VERSION ""

NS_ :

BS_:

BU_: DTCO ICL COO11 SRR6TRightMaster_R_Master SRR6TLeftMaster_L_Master

BO_ 2399091085 SRRL_Objects_09_SRR2: 64 SRR6TLeftMaster_L_Master
 SG_ SRRL_Object_E2E_CRC_09 : 0|16@1+ (1,0) [0|65535] "-"  COO11
 SG_ SRRL_Object_E2E_Counter_09 : 16|8@1+ (1,0) [0|255] "-"  COO11
 SG_ BatchId_SRRObj_L_09 : 24|3@1+ (1,0) [0|5] "-"  COO11
 SG_ LonPosition_L_17 : 28|13@1+ (0.0625,-254.9375) [-254.9375|254.9375] "m"  COO11
 SG_ LonPositionStd_L_17 : 41|10@1+ (0.025,0.025) [0.025|20] "m"  COO11
 SG_ LatPosition_L_17 : 51|13@1+ (0.0625,-254.9375) [-254.9375|254.9375] "m"  COO11
 SG_ LatPositionStd_L_17 : 64|10@1+ (0.025,0.025) [0.025|20] "m"  COO11
 SG_ LonGndVel_L_17 : 74|13@1+ (0.0625,-170) [-170|170] "m/s"  COO11
 SG_ LonGndVelStd_L_17 : 87|10@1+ (0.025,0.025) [0.025|14] "m/s"  COO11
 SG_ LatGndVel_L_17 : 97|13@1+ (0.0625,-170) [-170|170] "m/s"  COO11
 SG_ LatGndVelStd_L_17 : 110|10@1+ (0.025,0.025) [0.025|14] "m/s"  COO11
 SG_ ExistenceProbability_L_17 : 120|8@1+ (0.4,0) [0|100] "%"  COO11
 SG_ Width_L_17 : 128|8@1+ (0.1,0) [0|4] "m"  COO11
 SG_ Length_L_17 : 136|10@1+ (0.1,0) [0|60] "m"  COO11
 SG_ HeadingAngle_L_17 : 146|8@1+ (0.02618,-3.1416) [-3.1416|3.1416] "rad"  COO11
 SG_ DynamicProperty_L_17 : 154|3@1+ (1,0) [0|5] "-"  COO11
 SG_ ClassMostProb_L_17 : 157|3@1+ (1,0) [0|5] "-"  COO11
 SG_ ClassMostProbConf_L_17 : 160|8@1+ (0.4,0) [0|100] "%"  COO11
 SG_ ClassSecMostProb_L_17 : 168|3@1+ (1,0) [0|5] "-"  COO11
 SG_ ClassSecMostProbConf_L_17 : 171|8@1+ (0.4,0) [0|100] "%"  COO11
 SG_ MaintenanceState_L_17 : 179|3@1+ (1,0) [0|3] "-"  COO11
 SG_ YawRate_L_17 : 182|16@1+ (0.0001220703125,-3) [-3|3] "rad/s"  COO11
 SG_ Occlusion_L_17 : 198|3@1+ (1,0) [0|3] "-"  COO11
 SG_ TrackingId_L_17 : 201|8@1+ (1,0) [0|250] "-"  COO11
 SG_ ReferencePoint_L_17 : 209|4@1+ (1,0) [0|8] "-"  COO11
 SG_ RadarCrossSection_L_17 : 213|11@1+ (0.1,-100) [-100|100] "dBm²"  COO11
 SG_ AgeSinceCreated_L_17 : 224|10@1+ (0.01,0) [0|10] "s"  COO11
 SG_ LonPosition_L_18 : 268|13@1+ (0.0625,-254.9375) [-254.9375|254.9375] "m"  COO11
 SG_ LonPositionStd_L_18 : 281|10@1+ (0.025,0.025) [0.025|20] "m"  COO11
 SG_ LatPosition_L_18 : 291|13@1+ (0.0625,-254.9375) [-254.9375|254.9375] "m"  COO11
 SG_ LatPositionStd_L_18 : 304|10@1+ (0.025,0.025) [0.025|20] "m"  COO11
 SG_ LonGndVel_L_18 : 314|13@1+ (0.0625,-170) [-170|170] "m/s"  COO11
 SG_ LonGndVelStd_L_18 : 327|10@1+ (0.025,0.025) [0.025|14] "m/s"  COO11
 SG_ LatGndVel_L_18 : 337|13@1+ (0.0625,-170) [-170|170] "m/s"  COO11
 SG_ LatGndVelStd_L_18 : 350|10@1+ (0.025,0.025) [0.025|14] "m/s"  COO11
 SG_ ExistenceProbability_L_18 : 360|8@1+ (0.4,0) [0|100] "%"  COO11
 SG_ Width_L_18 : 368|8@1+ (0.1,0) [0|4] "m"  COO11
 SG_ Length_L_18 : 376|10@1+ (0.1,0) [0|60] "m"  COO11
 SG_ HeadingAngle_L_18 : 386|8@1+ (0.02618,-3.1416) [-3.1416|3.1416] "rad"  COO11
 SG_ DynamicProperty_L_18 : 394|3@1+ (1,0) [0|5] "-"  COO11
 SG_ ClassMostProb_L_18 : 397|3@1+ (1,0) [0|5] "-"  COO11
 SG_ ClassMostProbConf_L_18 : 400|8@1+ (0.4,0) [0|100] "%"  COO11
 SG_ ClassSecMostProb_L_18 : 408|3@1+ (1,0) [0|5] "-"  COO11
 SG_ ClassSecMostProbConf_L_18 : 411|8@1+ (0.4,0) [0|100] "%"  COO11
 SG_ MaintenanceState_L_18 : 419|3@1+ (1,0) [0|3] "-"  COO11
 SG_ YawRate_L_18 : 422|16@1+ (0.0001220703125,-3) [-3|3] "rad/s"  COO11
 SG_ Occlusion_L_18 : 438|3@1+ (1,0) [0|3] "-"  COO11
 SG_ TrackingId_L_18 : 441|8@1+ (1,0) [0|250] "-"  COO11
 SG_ ReferencePoint_L_18 : 449|4@1+ (1,0) [0|8] "-"  COO11
 SG_ RadarCrossSection_L_18 : 453|11@1+ (0.1,-100) [-100|100] "dbm²"  COO11
 SG_ AgeSinceCreated_L_18 : 464|10@1+ (0.01,0) [0|10] "s"  COO11

BO_ 2399091341 SRRL_Objects_10_SRR2: 64 SRR6TLeftMaster_L_Master
 SG_ SRRL_Object_E2E_CRC_10 : 0|16@1+ (1,0) [0|65535] "-"  COO11
 SG_ SRRL_Object_E2E_Counter_10 : 16|8@1+ (1,0) [0|255] "-"  COO11
 SG_ BatchId_SRRObj_L_10 : 24|3@1+ (1,0) [0|5] "-"  COO11
 SG_ LonPosition_L_19 : 28|13@1+ (0.0625,-254.9375) [-254.9375|254.9375] "m"  COO11
 SG_ LonPositionStd_L_19 : 41|10@1+ (0.025,0.025) [0.025|20] "m"  COO11
 SG_ LatPosition_L_19 : 51|13@1+ (0.0625,-254.9375) [-254.9375|254.9375] "m"  COO11
 SG_ LatPositionStd_L_19 : 64|10@1+ (0.025,0.025) [0.025|20] "m"  COO11
 SG_ LonGndVel_L_19 : 74|13@1+ (0.0625,-170) [-170|170] "m/s"  COO11
 SG_ LonGndVelStd_L_19 : 87|10@1+ (0.025,0.025) [0.025|14] "m/s"  COO11
 SG_ LatGndVel_L_19 : 97|13@1+ (0.0625,-170) [-170|170] "m/s"  COO11
 SG_ LatGndVelStd_L_19 : 110|10@1+ (0.025,0.025) [0.025|14] "m/s"  COO11
 SG_ ExistenceProbability_L_19 : 120|8@1+ (0.4,0) [0|100] "%"  COO11
 SG_ Width_L_19 : 128|8@1+ (0.1,0) [0|4] "m"  COO11
 SG_ Length_L_19 : 136|10@1+ (0.1,0) [0|60] "m"  COO11
 SG_ HeadingAngle_L_19 : 146|8@1+ (0.02618,-3.1416) [-3.1416|3.1416] "rad"  COO11
 SG_ DynamicProperty_L_19 : 154|3@1+ (1,0) [0|5] "-"  COO11
 SG_ ClassMostProb_L_19 : 157|3@1+ (1,0) [0|5] "-"  COO11
 SG_ ClassMostProbConf_L_19 : 160|8@1+ (0.4,0) [0|100] "%"  COO11
 SG_ ClassSecMostProb_L_19 : 168|3@1+ (1,0) [0|5] "-"  COO11
 SG_ ClassSecMostProbConf_L_19 : 171|8@1+ (0.4,0) [0|100] "%"  COO11
 SG_ MaintenanceState_L_19 : 179|3@1+ (1,0) [0|3] "-"  COO11
 SG_ YawRate_L_19 : 182|16@1+ (0.0001220703125,-3) [-3|3] "rad/s"  COO11
 SG_ Occlusion_L_19 : 198|3@1+ (1,0) [0|3] "-"  COO11
 SG_ TrackingId_L_19 : 201|8@1+ (1,0) [0|250] "-"  COO11
 SG_ ReferencePoint_L_19 : 209|4@1+ (1,0) [0|8] "-"  COO11
 SG_ RadarCrossSection_L_19 : 213|11@1+ (0.1,-100) [-100|100] "dBm²"  COO11
 SG_ AgeSinceCreated_L_19 : 224|10@1+ (0.01,0) [0|10] "s"  COO11
 SG_ LonPosition_L_20 : 268|13@1+ (0.0625,-254.9375) [-254.9375|254.9375] "m"  COO11
 SG_ LonPositionStd_L_20 : 281|10@1+ (0.025,0.025) [0.025|20] "m"  COO11
 SG_ LatPosition_L_20 : 291|13@1+ (0.0625,-254.9375) [-254.9375|254.9375] "m"  COO11
 SG_ LatPositionStd_L_20 : 304|10@1+ (0.025,0.025) [0.025|20] "m"  COO11
 SG_ LonGndVel_L_20 : 314|13@1+ (0.0625,-170) [-170|170] "m/s"  COO11
 SG_ LonGndVelStd_L_20 : 327|10@1+ (0.025,0.025) [0.025|14] "m/s"  COO11
 SG_ LatGndVel_L_20 : 337|13@1+ (0.0625,-170) [-170|170] "m/s"  COO11
 SG_ LatGndVelStd_L_20 : 350|10@1+ (0.025,0.025) [0.025|14] "m/s"  COO11
 SG_ ExistenceProbability_L_20 : 360|8@1+ (0.4,0) [0|100] "%"  COO11
 SG_ Width_L_20 : 368|8@1+ (0.1,0) [0|4] "m"  COO11
 SG_ Length_L_20 : 376|10@1+ (0.1,0) [0|60] "m"  COO11
 SG_ HeadingAngle_L_20 : 386|8@1+ (0.02618,-3.1416) [-3.1416|3.1416] "rad"  COO11
 SG_ DynamicProperty_L_20 : 394|3@1+ (1,0) [0|5] "-"  COO11
 SG_ ClassMostProb_L_20 : 397|3@1+ (1,0) [0|5] "-"  COO11
 SG_ ClassMostProbConf_L_20 : 400|8@1+ (0.4,0) [0|100] "%"  COO11
 SG_ ClassSecMostProb_L_20 : 408|3@1+ (1,0) [0|5] "-"  COO11
 SG_ ClassSecMostProbConf_L_20 : 411|8@1+ (0.4,0) [0|100] "%"  COO11
 SG_ MaintenanceState_L_20 : 419|3@1+ (1,0) [0|3] "-"  COO11
 SG_ YawRate_L_20 : 422|16@1+ (0.0001220703125,-3) [-3|3] "rad/s"  COO11
 SG_ Occlusion_L_20 : 438|3@1+ (1,0) [0|3] "-"  COO11
 SG_ TrackingId_L_20 : 441|8@1+ (1,0) [0|250] "-"  COO11
 SG_ ReferencePoint_L_20 : 449|4@1+ (1,0) [0|8] "-"  COO11
 SG_ RadarCrossSection_L_20 : 453|11@1+ (0.1,-100) [-100|100] "dbm²"  COO11
 SG_ AgeSinceCreated_L_20 : 464|10@1+ (0.01,0) [0|10] "s"  COO11

BO_ 2399089039 SRRR_Objects_01_SRR2: 64 SRR6TRightMaster_R_Master
 SG_ SRRR_Object_E2E_CRC_01 : 0|16@1+ (1,0) [0|65535] "-"  COO11
 SG_ SRRR_Object_E2E_Counter_01 : 16|8@1+ (1,0) [0|255] "-"  COO11
 SG_ BatchId_SRRObj_R_01 : 24|3@1+ (1,0) [0|5] "-"  COO11
 SG_ LonPosition_R_01 : 28|13@1+ (0.0625,-254.9375) [-254.9375|254.9375] "m"  COO11
 SG_ LonPositionStd_R_01 : 41|10@1+ (0.025,0.025) [0.025|20] "m"  COO11
 SG_ LatPosition_R_01 : 51|13@1+ (0.0625,-254.9375) [-254.9375|254.9375] "m"  COO11
 SG_ LatPositionStd_R_01 : 64|10@1+ (0.025,0.025) [0.025|20] "m"  COO11
 SG_ LonGndVel_R_01 : 74|13@1+ (0.0625,-170) [-170|170] "m/s"  COO11
 SG_ LonGndVelStd_R_01 : 87|10@1+ (0.025,0.025) [0.025|14] "m/s"  COO11
 SG_ LatGndVel_R_01 : 97|13@1+ (0.0625,-170) [-170|170] "m/s"  COO11
 SG_ LatGndVelStd_R_01 : 110|10@1+ (0.025,0.025) [0.025|14] "m/s"  COO11
 SG_ ExistenceProbability_R_01 : 120|8@1+ (0.4,0) [0|100] "%"  COO11
 SG_ Width_R_01 : 128|8@1+ (0.1,0) [0|4] "m"  COO11
 SG_ Length_R_01 : 136|10@1+ (0.1,0) [0|60] "m"  COO11
 SG_ HeadingAngle_R_01 : 146|8@1+ (0.02618,-3.1416) [-3.1416|3.1416] "rad"  COO11
 SG_ DynamicProperty_R_01 : 154|3@1+ (1,0) [0|5] "-"  COO11
 SG_ ClassMostProb_R_01 : 157|3@1+ (1,0) [0|5] "-"  COO11
 SG_ ClassMostProbConf_R_01 : 160|8@1+ (0.4,0) [0|100] "%"  COO11
 SG_ ClassSecMostProb_R_01 : 168|3@1+ (1,0) [0|5] "-"  COO11
 SG_ ClassSecMostProbConf_R_01 : 171|8@1+ (0.4,0) [0|100] "%"  COO11
 SG_ MaintenanceState_R_01 : 179|3@1+ (1,0) [0|3] "-"  COO11
 SG_ YawRate_R_01 : 182|16@1+ (0.0001220703125,-3) [-3|3] "rad/s"  COO11
 SG_ Occlusion_R_01 : 198|3@1+ (1,0) [0|3] "-"  COO11
 SG_ TrackingId_R_01 : 201|8@1+ (1,0) [0|250] "-"  COO11
 SG_ ReferencePoint_R_01 : 209|4@1+ (1,0) [0|8] "-"  COO11
 SG_ RadarCrossSection_R_01 : 213|11@1+ (0.1,-100) [-100|100] "dBm²"  COO11
 SG_ AgeSinceCreated_R_01 : 224|10@1+ (0.01,0) [0|10] "s"  COO11
 SG_ LonPosition_R_02 : 268|13@1+ (0.0625,-254.9375) [-254.9375|254.9375] "m"  COO11
 SG_ LonPositionStd_R_02 : 281|10@1+ (0.025,0.025) [0.025|20] "m"  COO11
 SG_ LatPosition_R_02 : 291|13@1+ (0.0625,-254.9375) [-254.9375|254.9375] "m"  COO11
 SG_ LatPositionStd_R_02 : 304|10@1+ (0.025,0.025) [0.025|20] "m"  COO11
 SG_ LonGndVel_R_02 : 314|13@1+ (0.0625,-170) [-170|170] "m/s"  COO11
 SG_ LonGndVelStd_R_02 : 327|10@1+ (0.025,0.025) [0.025|14] "m/s"  COO11
 SG_ LatGndVel_R_02 : 337|13@1+ (0.0625,-170) [-170|170] "m/s"  COO11
 SG_ LatGndVelStd_R_02 : 350|10@1+ (0.025,0.025) [0.025|14] "m/s"  COO11
 SG_ ExistenceProbability_R_02 : 360|8@1+ (0.4,0) [0|100] "%"  COO11
 SG_ Width_R_02 : 368|8@1+ (0.1,0) [0|4] "m"  COO11
 SG_ Length_R_02 : 376|10@1+ (0.1,0) [0|60] "m"  COO11
 SG_ HeadingAngle_R_02 : 386|8@1+ (0.02618,-3.1416) [-3.1416|3.1416] "rad"  COO11
 SG_ DynamicProperty_R_02 : 394|3@1+ (1,0) [0|5] "-"  COO11
 SG_ ClassMostProb_R_02 : 397|3@1+ (1,0) [0|5] "-"  COO11
 SG_ ClassMostProbConf_R_02 : 400|8@1+ (0.4,0) [0|100] "%"  COO11
 SG_ ClassSecMostProb_R_02 : 408|3@1+ (1,0) [0|5] "-"  COO11
 SG_ ClassSecMostProbConf_R_02 : 411|8@1+ (0.4,0) [0|100] "%"  COO11
 SG_ MaintenanceState_R_02 : 419|3@1+ (1,0) [0|3] "-"  COO11
 SG_ YawRate_R_02 : 422|16@1+ (0.0001220703125,-3) [-3|3] "rad/s"  COO11
 SG_ Occlusion_R_02 : 438|3@1+ (1,0) [0|3] "-"  COO11
 SG_ TrackingId_R_02 : 441|8@1+ (1,0) [0|250] "-"  COO11
 SG_ ReferencePoint_R_02 : 449|4@1+ (1,0) [0|8] "-"  COO11
 SG_ RadarCrossSection_R_02 : 453|11@1+ (0.1,-100) [-100|100] "dbm²"  COO11
 SG_ AgeSinceCreated_R_02 : 464|10@1+ (0.01,0) [0|10] "s"  COO11

BO_ 2399089295 SRRR_Objects_02_SRR2: 64 SRR6TRightMaster_R_Master
 SG_ SRRR_Object_E2E_CRC_02 : 0|16@1+ (1,0) [0|65535] "-"  COO11
 SG_ SRRR_Object_E2E_Counter_02 : 16|8@1+ (1,0) [0|255] "-"  COO11
 SG_ BatchId_SRRObj_R_02 : 24|3@1+ (1,0) [0|5] "-"  COO11
 SG_ LonPosition_R_03 : 28|13@1+ (0.0625,-254.9375) [-254.9375|254.9375] "m"  COO11
 SG_ LonPositionStd_R_03 : 41|10@1+ (0.025,0.025) [0.025|20] "m"  COO11
 SG_ LatPosition_R_03 : 51|13@1+ (0.0625,-254.9375) [-254.9375|254.9375] "m"  COO11
 SG_ LatPositionStd_R_03 : 64|10@1+ (0.025,0.025) [0.025|20] "m"  COO11
 SG_ LonGndVel_R_03 : 74|13@1+ (0.0625,-170) [-170|170] "m/s"  COO11
 SG_ LonGndVelStd_R_03 : 87|10@1+ (0.025,0.025) [0.025|14] "m/s"  COO11
 SG_ LatGndVel_R_03 : 97|13@1+ (0.0625,-170) [-170|170] "m/s"  COO11
 SG_ LatGndVelStd_R_03 : 110|10@1+ (0.025,0.025) [0.025|14] "m/s"  COO11
 SG_ ExistenceProbability_R_03 : 120|8@1+ (0.4,0) [0|100] "%"  COO11
 SG_ Width_R_03 : 128|8@1+ (0.1,0) [0|4] "m"  COO11
 SG_ Length_R_03 : 136|10@1+ (0.1,0) [0|60] "m"  COO11
 SG_ HeadingAngle_R_03 : 146|8@1+ (0.02618,-3.1416) [-3.1416|3.1416] "rad"  COO11
 SG_ DynamicProperty_R_03 : 154|3@1+ (1,0) [0|5] "-"  COO11
 SG_ ClassMostProb_R_03 : 157|3@1+ (1,0) [0|5] "-"  COO11
 SG_ ClassMostProbConf_R_03 : 160|8@1+ (0.4,0) [0|100] "%"  COO11
 SG_ ClassSecMostProb_R_03 : 168|3@1+ (1,0) [0|5] "-"  COO11
 SG_ ClassSecMostProbConf_R_03 : 171|8@1+ (0.4,0) [0|100] "%"  COO11
 SG_ MaintenanceState_R_03 : 179|3@1+ (1,0) [0|3] "-"  COO11
 SG_ YawRate_R_03 : 182|16@1+ (0.0001220703125,-3) [-3|3] "rad/s"  COO11
 SG_ Occlusion_R_03 : 198|3@1+ (1,0) [0|3] "-"  COO11
 SG_ TrackingId_R_03 : 201|8@1+ (1,0) [0|250] "-"  COO11
 SG_ ReferencePoint_R_03 : 209|4@1+ (1,0) [0|8] "-"  COO11
 SG_ RadarCrossSection_R_03 : 213|11@1+ (0.1,-100) [-100|100] "dBm²"  COO11
 SG_ AgeSinceCreated_R_03 : 224|10@1+ (0.01,0) [0|10] "s"  COO11
 SG_ LonPosition_R_04 : 268|13@1+ (0.0625,-254.9375) [-254.9375|254.9375] "m"  COO11
 SG_ LonPositionStd_R_04 : 281|10@1+ (0.025,0.025) [0.025|20] "m"  COO11
 SG_ LatPosition_R_04 : 291|13@1+ (0.0625,-254.9375) [-254.9375|254.9375] "m"  COO11
 SG_ LatPositionStd_R_04 : 304|10@1+ (0.025,0.025) [0.025|20] "m"  COO11
 SG_ LonGndVel_R_04 : 314|13@1+ (0.0625,-170) [-170|170] "m/s"  COO11
 SG_ LonGndVelStd_R_04 : 327|10@1+ (0.025,0.025) [0.025|14] "m/s"  COO11
 SG_ LatGndVel_R_04 : 337|13@1+ (0.0625,-170) [-170|170] "m/s"  COO11
 SG_ LatGndVelStd_R_04 : 350|10@1+ (0.025,0.025) [0.025|14] "m/s"  COO11
 SG_ ExistenceProbability_R_04 : 360|8@1+ (0.4,0) [0|100] "%"  COO11
 SG_ Width_R_04 : 368|8@1+ (0.1,0) [0|4] "m"  COO11
 SG_ Length_R_04 : 376|10@1+ (0.1,0) [0|60] "m"  COO11
 SG_ HeadingAngle_R_04 : 386|8@1+ (0.02618,-3.1416) [-3.1416|3.1416] "rad"  COO11
 SG_ DynamicProperty_R_04 : 394|3@1+ (1,0) [0|5] "-"  COO11
 SG_ ClassMostProb_R_04 : 397|3@1+ (1,0) [0|5] "-"  COO11
 SG_ ClassMostProbConf_R_04 : 400|8@1+ (0.4,0) [0|100] "%"  COO11
 SG_ ClassSecMostProb_R_04 : 408|3@1+ (1,0) [0|5] "-"  COO11
 SG_ ClassSecMostProbConf_R_04 : 411|8@1+ (0.4,0) [0|100] "%"  COO11
 SG_ MaintenanceState_R_04 : 419|3@1+ (1,0) [0|3] "-"  COO11
 SG_ YawRate_R_04 : 422|16@1+ (0.0001220703125,-3) [-3|3] "rad/s"  COO11
 SG_ Occlusion_R_04 : 438|3@1+ (1,0) [0|3] "-"  COO11
 SG_ TrackingId_R_04 : 441|8@1+ (1,0) [0|250] "-"  COO11
 SG_ ReferencePoint_R_04 : 449|4@1+ (1,0) [0|8] "-"  COO11
 SG_ RadarCrossSection_R_04 : 453|11@1+ (0.1,-100) [-100|100] "dbm²"  COO11
 SG_ AgeSinceCreated_R_04 : 464|10@1+ (0.01,0) [0|10] "s"  COO11

BO_ 2399089551 SRRR_Objects_03_SRR2: 64 SRR6TRightMaster_R_Master
 SG_ SRRR_Object_E2E_CRC_03 : 0|16@1+ (1,0) [0|65535] "-"  COO11
 SG_ SRRR_Object_E2E_Counter_03 : 16|8@1+ (1,0) [0|255] "-"  COO11
 SG_ BatchId_SRRObj_R_03 : 24|3@1+ (1,0) [0|5] "-"  COO11
 SG_ LonPosition_R_05 : 28|13@1+ (0.0625,-254.9375) [-254.9375|254.9375] "m"  COO11
 SG_ LonPositionStd_R_05 : 41|10@1+ (0.025,0.025) [0.025|20] "m"  COO11
 SG_ LatPosition_R_05 : 51|13@1+ (0.0625,-254.9375) [-254.9375|254.9375] "m"  COO11
 SG_ LatPositionStd_R_05 : 64|10@1+ (0.025,0.025) [0.025|20] "m"  COO11
 SG_ LonGndVel_R_05 : 74|13@1+ (0.0625,-170) [-170|170] "m/s"  COO11
 SG_ LonGndVelStd_R_05 : 87|10@1+ (0.025,0.025) [0.025|14] "m/s"  COO11
 SG_ LatGndVel_R_05 : 97|13@1+ (0.0625,-170) [-170|170] "m/s"  COO11
 SG_ LatGndVelStd_R_05 : 110|10@1+ (0.025,0.025) [0.025|14] "m/s"  COO11
 SG_ ExistenceProbability_R_05 : 120|8@1+ (0.4,0) [0|100] "%"  COO11
 SG_ Width_R_05 : 128|8@1+ (0.1,0) [0|4] "m"  COO11
 SG_ Length_R_05 : 136|10@1+ (0.1,0) [0|60] "m"  COO11
 SG_ HeadingAngle_R_05 : 146|8@1+ (0.02618,-3.1416) [-3.1416|3.1416] "rad"  COO11
 SG_ DynamicProperty_R_05 : 154|3@1+ (1,0) [0|5] "-"  COO11
 SG_ ClassMostProb_R_05 : 157|3@1+ (1,0) [0|5] "-"  COO11
 SG_ ClassMostProbConf_R_05 : 160|8@1+ (0.4,0) [0|100] "%"  COO11
 SG_ ClassSecMostProb_R_05 : 168|3@1+ (1,0) [0|5] "-"  COO11
 SG_ ClassSecMostProbConf_R_05 : 171|8@1+ (0.4,0) [0|100] "%"  COO11
 SG_ MaintenanceState_R_05 : 179|3@1+ (1,0) [0|3] "-"  COO11
 SG_ YawRate_R_05 : 182|16@1+ (0.0001220703125,-3) [-3|3] "rad/s"  COO11
 SG_ Occlusion_R_05 : 198|3@1+ (1,0) [0|3] "-"  COO11
 SG_ TrackingId_R_05 : 201|8@1+ (1,0) [0|250] "-"  COO11
 SG_ ReferencePoint_R_05 : 209|4@1+ (1,0) [0|8] "-"  COO11
 SG_ RadarCrossSection_R_05 : 213|11@1+ (0.1,-100) [-100|100] "dBm²"  COO11
 SG_ AgeSinceCreated_R_05 : 224|10@1+ (0.01,0) [0|10] "s"  COO11
 SG_ LonPosition_R_06 : 268|13@1+ (0.0625,-254.9375) [-254.9375|254.9375] "m"  COO11
 SG_ LonPositionStd_R_06 : 281|10@1+ (0.025,0.025) [0.025|20] "m"  COO11
 SG_ LatPosition_R_06 : 291|13@1+ (0.0625,-254.9375) [-254.9375|254.9375] "m"  COO11
 SG_ LatPositionStd_R_06 : 304|10@1+ (0.025,0.025) [0.025|20] "m"  COO11
 SG_ LonGndVel_R_06 : 314|13@1+ (0.0625,-170) [-170|170] "m/s"  COO11
 SG_ LonGndVelStd_R_06 : 327|10@1+ (0.025,0.025) [0.025|14] "m/s"  COO11
 SG_ LatGndVel_R_06 : 337|13@1+ (0.0625,-170) [-170|170] "m/s"  COO11
 SG_ LatGndVelStd_R_06 : 350|10@1+ (0.025,0.025) [0.025|14] "m/s"  COO11
 SG_ ExistenceProbability_R_06 : 360|8@1+ (0.4,0) [0|100] "%"  COO11
 SG_ Width_R_06 : 368|8@1+ (0.1,0) [0|4] "m"  COO11
 SG_ Length_R_06 : 376|10@1+ (0.1,0) [0|60] "m"  COO11
 SG_ HeadingAngle_R_06 : 386|8@1+ (0.02618,-3.1416) [-3.1416|3.1416] "rad"  COO11
 SG_ DynamicProperty_R_06 : 394|3@1+ (1,0) [0|5] "-"  COO11
 SG_ ClassMostProb_R_06 : 397|3@1+ (1,0) [0|5] "-"  COO11
 SG_ ClassMostProbConf_R_06 : 400|8@1+ (0.4,0) [0|100] "%"  COO11
 SG_ ClassSecMostProb_R_06 : 408|3@1+ (1,0) [0|5] "-"  COO11
 SG_ ClassSecMostProbConf_R_06 : 411|8@1+ (0.4,0) [0|100] "%"  COO11
 SG_ MaintenanceState_R_06 : 419|3@1+ (1,0) [0|3] "-"  COO11
 SG_ YawRate_R_06 : 422|16@1+ (0.0001220703125,-3) [-3|3] "rad/s"  COO11
 SG_ Occlusion_R_06 : 438|3@1+ (1,0) [0|3] "-"  COO11
 SG_ TrackingId_R_06 : 441|8@1+ (1,0) [0|250] "-"  COO11
 SG_ ReferencePoint_R_06 : 449|4@1+ (1,0) [0|8] "-"  COO11
 SG_ RadarCrossSection_R_06 : 453|11@1+ (0.1,-100) [-100|100] "dbm²"  COO11
 SG_ AgeSinceCreated_R_06 : 464|10@1+ (0.01,0) [0|10] "s"  COO11

BO_ 2399089807 SRRR_Objects_04_SRR2: 64 SRR6TRightMaster_R_Master
 SG_ SRRR_Object_E2E_CRC_04 : 0|16@1+ (1,0) [0|65535] "-"  COO11
 SG_ SRRR_Object_E2E_Counter_04 : 16|8@1+ (1,0) [0|255] "-"  COO11
 SG_ BatchId_SRRObj_R_04 : 24|3@1+ (1,0) [0|5] "-"  COO11
 SG_ LonPosition_R_07 : 28|13@1+ (0.0625,-254.9375) [-254.9375|254.9375] "m"  COO11
 SG_ LonPositionStd_R_07 : 41|10@1+ (0.025,0.025) [0.025|20] "m"  COO11
 SG_ LatPosition_R_07 : 51|13@1+ (0.0625,-254.9375) [-254.9375|254.9375] "m"  COO11
 SG_ LatPositionStd_R_07 : 64|10@1+ (0.025,0.025) [0.025|20] "m"  COO11
 SG_ LonGndVel_R_07 : 74|13@1+ (0.0625,-170) [-170|170] "m/s"  COO11
 SG_ LonGndVelStd_R_07 : 87|10@1+ (0.025,0.025) [0.025|14] "m/s"  COO11
 SG_ LatGndVel_R_07 : 97|13@1+ (0.0625,-170) [-170|170] "m/s"  COO11
 SG_ LatGndVelStd_R_07 : 110|10@1+ (0.025,0.025) [0.025|14] "m/s"  COO11
 SG_ ExistenceProbability_R_07 : 120|8@1+ (0.4,0) [0|100] "%"  COO11
 SG_ Width_R_07 : 128|8@1+ (0.1,0) [0|4] "m"  COO11
 SG_ Length_R_07 : 136|10@1+ (0.1,0) [0|60] "m"  COO11
 SG_ HeadingAngle_R_07 : 146|8@1+ (0.02618,-3.1416) [-3.1416|3.1416] "rad"  COO11
 SG_ DynamicProperty_R_07 : 154|3@1+ (1,0) [0|5] "-"  COO11
 SG_ ClassMostProb_R_07 : 157|3@1+ (1,0) [0|5] "-"  COO11
 SG_ ClassMostProbConf_R_07 : 160|8@1+ (0.4,0) [0|100] "%"  COO11
 SG_ ClassSecMostProb_R_07 : 168|3@1+ (1,0) [0|5] "-"  COO11
 SG_ ClassSecMostProbConf_R_07 : 171|8@1+ (0.4,0) [0|100] "%"  COO11
 SG_ MaintenanceState_R_07 : 179|3@1+ (1,0) [0|3] "-"  COO11
 SG_ YawRate_R_07 : 182|16@1+ (0.0001220703125,-3) [-3|3] "rad/s"  COO11
 SG_ Occlusion_R_07 : 198|3@1+ (1,0) [0|3] "-"  COO11
 SG_ TrackingId_R_07 : 201|8@1+ (1,0) [0|250] "-"  COO11
 SG_ ReferencePoint_R_07 : 209|4@1+ (1,0) [0|8] "-"  COO11
 SG_ RadarCrossSection_R_07 : 213|11@1+ (0.1,-100) [-100|100] "dBm²"  COO11
 SG_ AgeSinceCreated_R_07 : 224|10@1+ (0.01,0) [0|10] "s"  COO11
 SG_ LonPosition_R_08 : 268|13@1+ (0.0625,-254.9375) [-254.9375|254.9375] "m"  COO11
 SG_ LonPositionStd_R_08 : 281|10@1+ (0.025,0.025) [0.025|20] "m"  COO11
 SG_ LatPosition_R_08 : 291|13@1+ (0.0625,-254.9375) [-254.9375|254.9375] "m"  COO11
 SG_ LatPositionStd_R_08 : 304|10@1+ (0.025,0.025) [0.025|20] "m"  COO11
 SG_ LonGndVel_R_08 : 314|13@1+ (0.0625,-170) [-170|170] "m/s"  COO11
 SG_ LonGndVelStd_R_08 : 327|10@1+ (0.025,0.025) [0.025|14] "m/s"  COO11
 SG_ LatGndVel_R_08 : 337|13@1+ (0.0625,-170) [-170|170] "m/s"  COO11
 SG_ LatGndVelStd_R_08 : 350|10@1+ (0.025,0.025) [0.025|14] "m/s"  COO11
 SG_ ExistenceProbability_R_08 : 360|8@1+ (0.4,0) [0|100] "%"  COO11
 SG_ Width_R_08 : 368|8@1+ (0.1,0) [0|4] "m"  COO11
 SG_ Length_R_08 : 376|10@1+ (0.1,0) [0|60] "m"  COO11
 SG_ HeadingAngle_R_08 : 386|8@1+ (0.02618,-3.1416) [-3.1416|3.1416] "rad"  COO11
 SG_ DynamicProperty_R_08 : 394|3@1+ (1,0) [0|5] "-"  COO11
 SG_ ClassMostProb_R_08 : 397|3@1+ (1,0) [0|5] "-"  COO11
 SG_ ClassMostProbConf_R_08 : 400|8@1+ (0.4,0) [0|100] "%"  COO11
 SG_ ClassSecMostProb_R_08 : 408|3@1+ (1,0) [0|5] "-"  COO11
 SG_ ClassSecMostProbConf_R_08 : 411|8@1+ (0.4,0) [0|100] "%"  COO11
 SG_ MaintenanceState_R_08 : 419|3@1+ (1,0) [0|3] "-"  COO11
 SG_ YawRate_R_08 : 422|16@1+ (0.0001220703125,-3) [-3|3] "rad/s"  COO11
 SG_ Occlusion_R_08 : 438|3@1+ (1,0) [0|3] "-"  COO11
 SG_ TrackingId_R_08 : 441|8@1+ (1,0) [0|250] "-"  COO11
 SG_ ReferencePoint_R_08 : 449|4@1+ (1,0) [0|8] "-"  COO11
 SG_ RadarCrossSection_R_08 : 453|11@1+ (0.1,-100) [-100|100] "dbm²"  COO11
 SG_ AgeSinceCreated_R_08 : 464|10@1+ (0.01,0) [0|10] "s"  COO11

BO_ 2399090063 SRRR_Objects_05_SRR2: 64 SRR6TRightMaster_R_Master
 SG_ SRRR_Object_E2E_CRC_05 : 0|16@1+ (1,0) [0|65535] "-"  COO11
 SG_ SRRR_Object_E2E_Counter_05 : 16|8@1+ (1,0) [0|255] "-"  COO11
 SG_ BatchId_SRRObj_R_05 : 24|3@1+ (1,0) [0|5] "-"  COO11
 SG_ LonPosition_R_09 : 28|13@1+ (0.0625,-254.9375) [-254.9375|254.9375] "m"  COO11
 SG_ LonPositionStd_R_09 : 41|10@1+ (0.025,0.025) [0.025|20] "m"  COO11
 SG_ LatPosition_R_09 : 51|13@1+ (0.0625,-254.9375) [-254.9375|254.9375] "m"  COO11
 SG_ LatPositionStd_R_09 : 64|10@1+ (0.025,0.025) [0.025|20] "m"  COO11
 SG_ LonGndVel_R_09 : 74|13@1+ (0.0625,-170) [-170|170] "m/s"  COO11
 SG_ LonGndVelStd_R_09 : 87|10@1+ (0.025,0.025) [0.025|14] "m/s"  COO11
 SG_ LatGndVel_R_09 : 97|13@1+ (0.0625,-170) [-170|170] "m/s"  COO11
 SG_ LatGndVelStd_R_09 : 110|10@1+ (0.025,0.025) [0.025|14] "m/s"  COO11
 SG_ ExistenceProbability_R_09 : 120|8@1+ (0.4,0) [0|100] "%"  COO11
 SG_ Width_R_09 : 128|8@1+ (0.1,0) [0|4] "m"  COO11
 SG_ Length_R_09 : 136|10@1+ (0.1,0) [0|60] "m"  COO11
 SG_ HeadingAngle_R_09 : 146|8@1+ (0.02618,-3.1416) [-3.1416|3.1416] "rad"  COO11
 SG_ DynamicProperty_R_09 : 154|3@1+ (1,0) [0|5] "-"  COO11
 SG_ ClassMostProb_R_09 : 157|3@1+ (1,0) [0|5] "-"  COO11
 SG_ ClassMostProbConf_R_09 : 160|8@1+ (0.4,0) [0|100] "%"  COO11
 SG_ ClassSecMostProb_R_09 : 168|3@1+ (1,0) [0|5] "-"  COO11
 SG_ ClassSecMostProbConf_R_09 : 171|8@1+ (0.4,0) [0|100] "%"  COO11
 SG_ MaintenanceState_R_09 : 179|3@1+ (1,0) [0|3] "-"  COO11
 SG_ YawRate_R_09 : 182|16@1+ (0.0001220703125,-3) [-3|3] "rad/s"  COO11
 SG_ Occlusion_R_09 : 198|3@1+ (1,0) [0|3] "-"  COO11
 SG_ TrackingId_R_09 : 201|8@1+ (1,0) [0|250] "-"  COO11
 SG_ ReferencePoint_R_09 : 209|4@1+ (1,0) [0|8] "-"  COO11
 SG_ RadarCrossSection_R_09 : 213|11@1+ (0.1,-100) [-100|100] "dBm²"  COO11
 SG_ AgeSinceCreated_R_09 : 224|10@1+ (0.01,0) [0|10] "s"  COO11
 SG_ LonPosition_R_10 : 268|13@1+ (0.0625,-254.9375) [-254.9375|254.9375] "m"  COO11
 SG_ LonPositionStd_R_10 : 281|10@1+ (0.025,0.025) [0.025|20] "m"  COO11
 SG_ LatPosition_R_10 : 291|13@1+ (0.0625,-254.9375) [-254.9375|254.9375] "m"  COO11
 SG_ LatPositionStd_R_10 : 304|10@1+ (0.025,0.025) [0.025|20] "m"  COO11
 SG_ LonGndVel_R_10 : 314|13@1+ (0.0625,-170) [-170|170] "m/s"  COO11
 SG_ LonGndVelStd_R_10 : 327|10@1+ (0.025,0.025) [0.025|14] "m/s"  COO11
 SG_ LatGndVel_R_10 : 337|13@1+ (0.0625,-170) [-170|170] "m/s"  COO11
 SG_ LatGndVelStd_R_10 : 350|10@1+ (0.025,0.025) [0.025|14] "m/s"  COO11
 SG_ ExistenceProbability_R_10 : 360|8@1+ (0.4,0) [0|100] "%"  COO11
 SG_ Width_R_10 : 368|8@1+ (0.1,0) [0|4] "m"  COO11
 SG_ Length_R_10 : 376|10@1+ (0.1,0) [0|60] "m"  COO11
 SG_ HeadingAngle_R_10 : 386|8@1+ (0.02618,-3.1416) [-3.1416|3.1416] "rad"  COO11
 SG_ DynamicProperty_R_10 : 394|3@1+ (1,0) [0|5] "-"  COO11
 SG_ ClassMostProb_R_10 : 397|3@1+ (1,0) [0|5] "-"  COO11
 SG_ ClassMostProbConf_R_10 : 400|8@1+ (0.4,0) [0|100] "%"  COO11
 SG_ ClassSecMostProb_R_10 : 408|3@1+ (1,0) [0|5] "-"  COO11
 SG_ ClassSecMostProbConf_R_10 : 411|8@1+ (0.4,0) [0|100] "%"  COO11
 SG_ MaintenanceState_R_10 : 419|3@1+ (1,0) [0|3] "-"  COO11
 SG_ YawRate_R_10 : 422|16@1+ (0.0001220703125,-3) [-3|3] "rad/s"  COO11
 SG_ Occlusion_R_10 : 438|3@1+ (1,0) [0|3] "-"  COO11
 SG_ TrackingId_R_10 : 441|8@1+ (1,0) [0|250] "-"  COO11
 SG_ ReferencePoint_R_10 : 449|4@1+ (1,0) [0|8] "-"  COO11
 SG_ RadarCrossSection_R_10 : 453|11@1+ (0.1,-100) [-100|100] "dbm²"  COO11
 SG_ AgeSinceCreated_R_10 : 464|10@1+ (0.01,0) [0|10] "s"  COO11

BO_ 2399090319 SRRR_Objects_06_SRR2: 64 SRR6TRightMaster_R_Master
 SG_ SRRR_Object_E2E_CRC_06 : 0|16@1+ (1,0) [0|65535] "-"  COO11
 SG_ SRRR_Object_E2E_Counter_06 : 16|8@1+ (1,0) [0|255] "-"  COO11
 SG_ BatchId_SRRObj_R_06 : 24|3@1+ (1,0) [0|5] "-"  COO11
 SG_ LonPosition_R_11 : 28|13@1+ (0.0625,-254.9375) [-254.9375|254.9375] "m"  COO11
 SG_ LonPositionStd_R_11 : 41|10@1+ (0.025,0.025) [0.025|20] "m"  COO11
 SG_ LatPosition_R_11 : 51|13@1+ (0.0625,-254.9375) [-254.9375|254.9375] "m"  COO11
 SG_ LatPositionStd_R_11 : 64|10@1+ (0.025,0.025) [0.025|20] "m"  COO11
 SG_ LonGndVel_R_11 : 74|13@1+ (0.0625,-170) [-170|170] "m/s"  COO11
 SG_ LonGndVelStd_R_11 : 87|10@1+ (0.025,0.025) [0.025|14] "m/s"  COO11
 SG_ LatGndVel_R_11 : 97|13@1+ (0.0625,-170) [-170|170] "m/s"  COO11
 SG_ LatGndVelStd_R_11 : 110|10@1+ (0.025,0.025) [0.025|14] "m/s"  COO11
 SG_ ExistenceProbability_R_11 : 120|8@1+ (0.4,0) [0|100] "%"  COO11
 SG_ Width_R_11 : 128|8@1+ (0.1,0) [0|4] "m"  COO11
 SG_ Length_R_11 : 136|10@1+ (0.1,0) [0|60] "m"  COO11
 SG_ HeadingAngle_R_11 : 146|8@1+ (0.02618,-3.1416) [-3.1416|3.1416] "rad"  COO11
 SG_ DynamicProperty_R_11 : 154|3@1+ (1,0) [0|5] "-"  COO11
 SG_ ClassMostProb_R_11 : 157|3@1+ (1,0) [0|5] "-"  COO11
 SG_ ClassMostProbConf_R_11 : 160|8@1+ (0.4,0) [0|100] "%"  COO11
 SG_ ClassSecMostProb_R_11 : 168|3@1+ (1,0) [0|5] "-"  COO11
 SG_ ClassSecMostProbConf_R_11 : 171|8@1+ (0.4,0) [0|100] "%"  COO11
 SG_ MaintenanceState_R_11 : 179|3@1+ (1,0) [0|3] "-"  COO11
 SG_ YawRate_R_11 : 182|16@1+ (0.0001220703125,-3) [-3|3] "rad/s"  COO11
 SG_ Occlusion_R_11 : 198|3@1+ (1,0) [0|3] "-"  COO11
 SG_ TrackingId_R_11 : 201|8@1+ (1,0) [0|250] "-"  COO11
 SG_ ReferencePoint_R_11 : 209|4@1+ (1,0) [0|8] "-"  COO11
 SG_ RadarCrossSection_R_11 : 213|11@1+ (0.1,-100) [-100|100] "dBm²"  COO11
 SG_ AgeSinceCreated_R_11 : 224|10@1+ (0.01,0) [0|10] "s"  COO11
 SG_ LonPosition_R_12 : 268|13@1+ (0.0625,-254.9375) [-254.9375|254.9375] "m"  COO11
 SG_ LonPositionStd_R_12 : 281|10@1+ (0.025,0.025) [0.025|20] "m"  COO11
 SG_ LatPosition_R_12 : 291|13@1+ (0.0625,-254.9375) [-254.9375|254.9375] "m"  COO11
 SG_ LatPositionStd_R_12 : 304|10@1+ (0.025,0.025) [0.025|20] "m"  COO11
 SG_ LonGndVel_R_12 : 314|13@1+ (0.0625,-170) [-170|170] "m/s"  COO11
 SG_ LonGndVelStd_R_12 : 327|10@1+ (0.025,0.025) [0.025|14] "m/s"  COO11
 SG_ LatGndVel_R_12 : 337|13@1+ (0.0625,-170) [-170|170] "m/s"  COO11
 SG_ LatGndVelStd_R_12 : 350|10@1+ (0.025,0.025) [0.025|14] "m/s"  COO11
 SG_ ExistenceProbability_R_12 : 360|8@1+ (0.4,0) [0|100] "%"  COO11
 SG_ Width_R_12 : 368|8@1+ (0.1,0) [0|4] "m"  COO11
 SG_ Length_R_12 : 376|10@1+ (0.1,0) [0|60] "m"  COO11
 SG_ HeadingAngle_R_12 : 386|8@1+ (0.02618,-3.1416) [-3.1416|3.1416] "rad"  COO11
 SG_ DynamicProperty_R_12 : 394|3@1+ (1,0) [0|5] "-"  COO11
 SG_ ClassMostProb_R_12 : 397|3@1+ (1,0) [0|5] "-"  COO11
 SG_ ClassMostProbConf_R_12 : 400|8@1+ (0.4,0) [0|100] "%"  COO11
 SG_ ClassSecMostProb_R_12 : 408|3@1+ (1,0) [0|5] "-"  COO11
 SG_ ClassSecMostProbConf_R_12 : 411|8@1+ (0.4,0) [0|100] "%"  COO11
 SG_ MaintenanceState_R_12 : 419|3@1+ (1,0) [0|3] "-"  COO11
 SG_ YawRate_R_12 : 422|16@1+ (0.0001220703125,-3) [-3|3] "rad/s"  COO11
 SG_ Occlusion_R_12 : 438|3@1+ (1,0) [0|3] "-"  COO11
 SG_ TrackingId_R_12 : 441|8@1+ (1,0) [0|250] "-"  COO11
 SG_ ReferencePoint_R_12 : 449|4@1+ (1,0) [0|8] "-"  COO11
 SG_ RadarCrossSection_R_12 : 453|11@1+ (0.1,-100) [-100|100] "dbm²"  COO11
 SG_ AgeSinceCreated_R_12 : 464|10@1+ (0.01,0) [0|10] "s"  COO11

BO_ 2399090575 SRRR_Objects_07_SRR2: 64 SRR6TRightMaster_R_Master
 SG_ SRRR_Object_E2E_CRC_07 : 0|16@1+ (1,0) [0|65535] "-"  COO11
 SG_ SRRR_Object_E2E_Counter_07 : 16|8@1+ (1,0) [0|255] "-"  COO11
 SG_ BatchId_SRRObj_R_07 : 24|3@1+ (1,0) [0|5] "-"  COO11
 SG_ LonPosition_R_13 : 28|13@1+ (0.0625,-254.9375) [-254.9375|254.9375] "m"  COO11
 SG_ LonPositionStd_R_13 : 41|10@1+ (0.025,0.025) [0.025|20] "m"  COO11
 SG_ LatPosition_R_13 : 51|13@1+ (0.0625,-254.9375) [-254.9375|254.9375] "m"  COO11
 SG_ LatPositionStd_R_13 : 64|10@1+ (0.025,0.025) [0.025|20] "m"  COO11
 SG_ LonGndVel_R_13 : 74|13@1+ (0.0625,-170) [-170|170] "m/s"  COO11
 SG_ LonGndVelStd_R_13 : 87|10@1+ (0.025,0.025) [0.025|14] "m/s"  COO11
 SG_ LatGndVel_R_13 : 97|13@1+ (0.0625,-170) [-170|170] "m/s"  COO11
 SG_ LatGndVelStd_R_13 : 110|10@1+ (0.025,0.025) [0.025|14] "m/s"  COO11
 SG_ ExistenceProbability_R_13 : 120|8@1+ (0.4,0) [0|100] "%"  COO11
 SG_ Width_R_13 : 128|8@1+ (0.1,0) [0|4] "m"  COO11
 SG_ Length_R_13 : 136|10@1+ (0.1,0) [0|60] "m"  COO11
 SG_ HeadingAngle_R_13 : 146|8@1+ (0.02618,-3.1416) [-3.1416|3.1416] "rad"  COO11
 SG_ DynamicProperty_R_13 : 154|3@1+ (1,0) [0|5] "-"  COO11
 SG_ ClassMostProb_R_13 : 157|3@1+ (1,0) [0|5] "-"  COO11
 SG_ ClassMostProbConf_R_13 : 160|8@1+ (0.4,0) [0|100] "%"  COO11
 SG_ ClassSecMostProb_R_13 : 168|3@1+ (1,0) [0|5] "-"  COO11
 SG_ ClassSecMostProbConf_R_13 : 171|8@1+ (0.4,0) [0|100] "%"  COO11
 SG_ MaintenanceState_R_13 : 179|3@1+ (1,0) [0|3] "-"  COO11
 SG_ YawRate_R_13 : 182|16@1+ (0.0001220703125,-3) [-3|3] "rad/s"  COO11
 SG_ Occlusion_R_13 : 198|3@1+ (1,0) [0|3] "-"  COO11
 SG_ TrackingId_R_13 : 201|8@1+ (1,0) [0|250] "-"  COO11
 SG_ ReferencePoint_R_13 : 209|4@1+ (1,0) [0|8] "-"  COO11
 SG_ RadarCrossSection_R_13 : 213|11@1+ (0.1,-100) [-100|100] "dBm²"  COO11
 SG_ AgeSinceCreated_R_13 : 224|10@1+ (0.01,0) [0|10] "s"  COO11
 SG_ LonPosition_R_14 : 268|13@1+ (0.0625,-254.9375) [-254.9375|254.9375] "m"  COO11
 SG_ LonPositionStd_R_14 : 281|10@1+ (0.025,0.025) [0.025|20] "m"  COO11
 SG_ LatPosition_R_14 : 291|13@1+ (0.0625,-254.9375) [-254.9375|254.9375] "m"  COO11
 SG_ LatPositionStd_R_14 : 304|10@1+ (0.025,0.025) [0.025|20] "m"  COO11
 SG_ LonGndVel_R_14 : 314|13@1+ (0.0625,-170) [-170|170] "m/s"  COO11
 SG_ LonGndVelStd_R_14 : 327|10@1+ (0.025,0.025) [0.025|14] "m/s"  COO11
 SG_ LatGndVel_R_14 : 337|13@1+ (0.0625,-170) [-170|170] "m/s"  COO11
 SG_ LatGndVelStd_R_14 : 350|10@1+ (0.025,0.025) [0.025|14] "m/s"  COO11
 SG_ ExistenceProbability_R_14 : 360|8@1+ (0.4,0) [0|100] "%"  COO11
 SG_ Width_R_14 : 368|8@1+ (0.1,0) [0|4] "m"  COO11
 SG_ Length_R_14 : 376|10@1+ (0.1,0) [0|60] "m"  COO11
 SG_ HeadingAngle_R_14 : 386|8@1+ (0.02618,-3.1416) [-3.1416|3.1416] "rad"  COO11
 SG_ DynamicProperty_R_14 : 394|3@1+ (1,0) [0|5] "-"  COO11
 SG_ ClassMostProb_R_14 : 397|3@1+ (1,0) [0|5] "-"  COO11
 SG_ ClassMostProbConf_R_14 : 400|8@1+ (0.4,0) [0|100] "%"  COO11
 SG_ ClassSecMostProb_R_14 : 408|3@1+ (1,0) [0|5] "-"  COO11
 SG_ ClassSecMostProbConf_R_14 : 411|8@1+ (0.4,0) [0|100] "%"  COO11
 SG_ MaintenanceState_R_14 : 419|3@1+ (1,0) [0|3] "-"  COO11
 SG_ YawRate_R_14 : 422|16@1+ (0.0001220703125,-3) [-3|3] "rad/s"  COO11
 SG_ Occlusion_R_14 : 438|3@1+ (1,0) [0|3] "-"  COO11
 SG_ TrackingId_R_14 : 441|8@1+ (1,0) [0|250] "-"  COO11
 SG_ ReferencePoint_R_14 : 449|4@1+ (1,0) [0|8] "-"  COO11
 SG_ RadarCrossSection_R_14 : 453|11@1+ (0.1,-100) [-100|100] "dbm²"  COO11
 SG_ AgeSinceCreated_R_14 : 464|10@1+ (0.01,0) [0|10] "s"  COO11

BO_ 2399090831 SRRR_Objects_08_SRR2: 64 SRR6TRightMaster_R_Master
 SG_ SRRR_Object_E2E_CRC_08 : 0|16@1+ (1,0) [0|65535] "-"  COO11
 SG_ SRRR_Object_E2E_Counter_08 : 16|8@1+ (1,0) [0|255] "-"  COO11
 SG_ BatchId_SRRObj_R_08 : 24|3@1+ (1,0) [0|5] "-"  COO11
 SG_ LonPosition_R_15 : 28|13@1+ (0.0625,-254.9375) [-254.9375|254.9375] "m"  COO11
 SG_ LonPositionStd_R_15 : 41|10@1+ (0.025,0.025) [0.025|20] "m"  COO11
 SG_ LatPosition_R_15 : 51|13@1+ (0.0625,-254.9375) [-254.9375|254.9375] "m"  COO11
 SG_ LatPositionStd_R_15 : 64|10@1+ (0.025,0.025) [0.025|20] "m"  COO11
 SG_ LonGndVel_R_15 : 74|13@1+ (0.0625,-170) [-170|170] "m/s"  COO11
 SG_ LonGndVelStd_R_15 : 87|10@1+ (0.025,0.025) [0.025|14] "m/s"  COO11
 SG_ LatGndVel_R_15 : 97|13@1+ (0.0625,-170) [-170|170] "m/s"  COO11
 SG_ LatGndVelStd_R_15 : 110|10@1+ (0.025,0.025) [0.025|14] "m/s"  COO11
 SG_ ExistenceProbability_R_15 : 120|8@1+ (0.4,0) [0|100] "%"  COO11
 SG_ Width_R_15 : 128|8@1+ (0.1,0) [0|4] "m"  COO11
 SG_ Length_R_15 : 136|10@1+ (0.1,0) [0|60] "m"  COO11
 SG_ HeadingAngle_R_15 : 146|8@1+ (0.02618,-3.1416) [-3.1416|3.1416] "rad"  COO11
 SG_ DynamicProperty_R_15 : 154|3@1+ (1,0) [0|5] "-"  COO11
 SG_ ClassMostProb_R_15 : 157|3@1+ (1,0) [0|5] "-"  COO11
 SG_ ClassMostProbConf_R_15 : 160|8@1+ (0.4,0) [0|100] "%"  COO11
 SG_ ClassSecMostProb_R_15 : 168|3@1+ (1,0) [0|5] "-"  COO11
 SG_ ClassSecMostProbConf_R_15 : 171|8@1+ (0.4,0) [0|100] "%"  COO11
 SG_ MaintenanceState_R_15 : 179|3@1+ (1,0) [0|3] "-"  COO11
 SG_ YawRate_R_15 : 182|16@1+ (0.0001220703125,-3) [-3|3] "rad/s"  COO11
 SG_ Occlusion_R_15 : 198|3@1+ (1,0) [0|3] "-"  COO11
 SG_ TrackingId_R_15 : 201|8@1+ (1,0) [0|250] "-"  COO11
 SG_ ReferencePoint_R_15 : 209|4@1+ (1,0) [0|8] "-"  COO11
 SG_ RadarCrossSection_R_15 : 213|11@1+ (0.1,-100) [-100|100] "dBm²"  COO11
 SG_ AgeSinceCreated_R_15 : 224|10@1+ (0.01,0) [0|10] "s"  COO11
 SG_ LonPosition_R_16 : 268|13@1+ (0.0625,-254.9375) [-254.9375|254.9375] "m"  COO11
 SG_ LonPositionStd_R_16 : 281|10@1+ (0.025,0.025) [0.025|20] "m"  COO11
 SG_ LatPosition_R_16 : 291|13@1+ (0.0625,-254.9375) [-254.9375|254.9375] "m"  COO11
 SG_ LatPositionStd_R_16 : 304|10@1+ (0.025,0.025) [0.025|20] "m"  COO11
 SG_ LonGndVel_R_16 : 314|13@1+ (0.0625,-170) [-170|170] "m/s"  COO11
 SG_ LonGndVelStd_R_16 : 327|10@1+ (0.025,0.025) [0.025|14] "m/s"  COO11
 SG_ LatGndVel_R_16 : 337|13@1+ (0.0625,-170) [-170|170] "m/s"  COO11
 SG_ LatGndVelStd_R_16 : 350|10@1+ (0.025,0.025) [0.025|14] "m/s"  COO11
 SG_ ExistenceProbability_R_16 : 360|8@1+ (0.4,0) [0|100] "%"  COO11
 SG_ Width_R_16 : 368|8@1+ (0.1,0) [0|4] "m"  COO11
 SG_ Length_R_16 : 376|10@1+ (0.1,0) [0|60] "m"  COO11
 SG_ HeadingAngle_R_16 : 386|8@1+ (0.02618,-3.1416) [-3.1416|3.1416] "rad"  COO11
 SG_ DynamicProperty_R_16 : 394|3@1+ (1,0) [0|5] "-"  COO11
 SG_ ClassMostProb_R_16 : 397|3@1+ (1,0) [0|5] "-"  COO11
 SG_ ClassMostProbConf_R_16 : 400|8@1+ (0.4,0) [0|100] "%"  COO11
 SG_ ClassSecMostProb_R_16 : 408|3@1+ (1,0) [0|5] "-"  COO11
 SG_ ClassSecMostProbConf_R_16 : 411|8@1+ (0.4,0) [0|100] "%"  COO11
 SG_ MaintenanceState_R_16 : 419|3@1+ (1,0) [0|3] "-"  COO11
 SG_ YawRate_R_16 : 422|16@1+ (0.0001220703125,-3) [-3|3] "rad/s"  COO11
 SG_ Occlusion_R_16 : 438|3@1+ (1,0) [0|3] "-"  COO11
 SG_ TrackingId_R_16 : 441|8@1+ (1,0) [0|250] "-"  COO11
 SG_ ReferencePoint_R_16 : 449|4@1+ (1,0) [0|8] "-"  COO11
 SG_ RadarCrossSection_R_16 : 453|11@1+ (0.1,-100) [-100|100] "dbm²"  COO11
 SG_ AgeSinceCreated_R_16 : 464|10@1+ (0.01,0) [0|10] "s"  COO11

BO_ 2399091087 SRRR_Objects_09_SRR2: 64 SRR6TRightMaster_R_Master
 SG_ SRRR_Object_E2E_CRC_09 : 0|16@1+ (1,0) [0|65535] "-"  COO11
 SG_ SRRR_Object_E2E_Counter_09 : 16|8@1+ (1,0) [0|255] "-"  COO11
 SG_ BatchId_SRRObj_R_09 : 24|3@1+ (1,0) [0|5] "-"  COO11
 SG_ LonPosition_R_17 : 28|13@1+ (0.0625,-254.9375) [-254.9375|254.9375] "m"  COO11
 SG_ LonPositionStd_R_17 : 41|10@1+ (0.025,0.025) [0.025|20] "m"  COO11
 SG_ LatPosition_R_17 : 51|13@1+ (0.0625,-254.9375) [-254.9375|254.9375] "m"  COO11
 SG_ LatPositionStd_R_17 : 64|10@1+ (0.025,0.025) [0.025|20] "m"  COO11
 SG_ LonGndVel_R_17 : 74|13@1+ (0.0625,-170) [-170|170] "m/s"  COO11
 SG_ LonGndVelStd_R_17 : 87|10@1+ (0.025,0.025) [0.025|14] "m/s"  COO11
 SG_ LatGndVel_R_17 : 97|13@1+ (0.0625,-170) [-170|170] "m/s"  COO11
 SG_ LatGndVelStd_R_17 : 110|10@1+ (0.025,0.025) [0.025|14] "m/s"  COO11
 SG_ ExistenceProbability_R_17 : 120|8@1+ (0.4,0) [0|100] "%"  COO11
 SG_ Width_R_17 : 128|8@1+ (0.1,0) [0|4] "m"  COO11
 SG_ Length_R_17 : 136|10@1+ (0.1,0) [0|60] "m"  COO11
 SG_ HeadingAngle_R_17 : 146|8@1+ (0.02618,-3.1416) [-3.1416|3.1416] "rad"  COO11
 SG_ DynamicProperty_R_17 : 154|3@1+ (1,0) [0|5] "-"  COO11
 SG_ ClassMostProb_R_17 : 157|3@1+ (1,0) [0|5] "-"  COO11
 SG_ ClassMostProbConf_R_17 : 160|8@1+ (0.4,0) [0|100] "%"  COO11
 SG_ ClassSecMostProb_R_17 : 168|3@1+ (1,0) [0|5] "-"  COO11
 SG_ ClassSecMostProbConf_R_17 : 171|8@1+ (0.4,0) [0|100] "%"  COO11
 SG_ MaintenanceState_R_17 : 179|3@1+ (1,0) [0|3] "-"  COO11
 SG_ YawRate_R_17 : 182|16@1+ (0.0001220703125,-3) [-3|3] "rad/s"  COO11
 SG_ Occlusion_R_17 : 198|3@1+ (1,0) [0|3] "-"  COO11
 SG_ TrackingId_R_17 : 201|8@1+ (1,0) [0|250] "-"  COO11
 SG_ ReferencePoint_R_17 : 209|4@1+ (1,0) [0|8] "-"  COO11
 SG_ RadarCrossSection_R_17 : 213|11@1+ (0.1,-100) [-100|100] "dBm²"  COO11
 SG_ AgeSinceCreated_R_17 : 224|10@1+ (0.01,0) [0|10] "s"  COO11
 SG_ LonPosition_R_18 : 268|13@1+ (0.0625,-254.9375) [-254.9375|254.9375] "m"  COO11
 SG_ LonPositionStd_R_18 : 281|10@1+ (0.025,0.025) [0.025|20] "m"  COO11
 SG_ LatPosition_R_18 : 291|13@1+ (0.0625,-254.9375) [-254.9375|254.9375] "m"  COO11
 SG_ LatPositionStd_R_18 : 304|10@1+ (0.025,0.025) [0.025|20] "m"  COO11
 SG_ LonGndVel_R_18 : 314|13@1+ (0.0625,-170) [-170|170] "m/s"  COO11
 SG_ LonGndVelStd_R_18 : 327|10@1+ (0.025,0.025) [0.025|14] "m/s"  COO11
 SG_ LatGndVel_R_18 : 337|13@1+ (0.0625,-170) [-170|170] "m/s"  COO11
 SG_ LatGndVelStd_R_18 : 350|10@1+ (0.025,0.025) [0.025|14] "m/s"  COO11
 SG_ ExistenceProbability_R_18 : 360|8@1+ (0.4,0) [0|100] "%"  COO11
 SG_ Width_R_18 : 368|8@1+ (0.1,0) [0|4] "m"  COO11
 SG_ Length_R_18 : 376|10@1+ (0.1,0) [0|60] "m"  COO11
 SG_ HeadingAngle_R_18 : 386|8@1+ (0.02618,-3.1416) [-3.1416|3.1416] "rad"  COO11
 SG_ DynamicProperty_R_18 : 394|3@1+ (1,0) [0|5] "-"  COO11
 SG_ ClassMostProb_R_18 : 397|3@1+ (1,0) [0|5] "-"  COO11
 SG_ ClassMostProbConf_R_18 : 400|8@1+ (0.4,0) [0|100] "%"  COO11
 SG_ ClassSecMostProb_R_18 : 408|3@1+ (1,0) [0|5] "-"  COO11
 SG_ ClassSecMostProbConf_R_18 : 411|8@1+ (0.4,0) [0|100] "%"  COO11
 SG_ MaintenanceState_R_18 : 419|3@1+ (1,0) [0|3] "-"  COO11
 SG_ YawRate_R_18 : 422|16@1+ (0.0001220703125,-3) [-3|3] "rad/s"  COO11
 SG_ Occlusion_R_18 : 438|3@1+ (1,0) [0|3] "-"  COO11
 SG_ TrackingId_R_18 : 441|8@1+ (1,0) [0|250] "-"  COO11
 SG_ ReferencePoint_R_18 : 449|4@1+ (1,0) [0|8] "-"  COO11
 SG_ RadarCrossSection_R_18 : 453|11@1+ (0.1,-100) [-100|100] "dbm²"  COO11
 SG_ AgeSinceCreated_R_18 : 464|10@1+ (0.01,0) [0|10] "s"  COO11

BO_ 2399091343 SRRR_Objects_10_SRR2: 64 SRR6TRightMaster_R_Master
 SG_ SRRR_Object_E2E_CRC_10 : 0|16@1+ (1,0) [0|65535] "-"  COO11
 SG_ SRRR_Object_E2E_Counter_10 : 16|8@1+ (1,0) [0|255] "-"  COO11
 SG_ BatchId_SRRObj_R_10 : 24|3@1+ (1,0) [0|5] "-"  COO11
 SG_ LonPosition_R_19 : 28|13@1+ (0.0625,-254.9375) [-254.9375|254.9375] "m"  COO11
 SG_ LonPositionStd_R_19 : 41|10@1+ (0.025,0.025) [0.025|20] "m"  COO11
 SG_ LatPosition_R_19 : 51|13@1+ (0.0625,-254.9375) [-254.9375|254.9375] "m"  COO11
 SG_ LatPositionStd_R_19 : 64|10@1+ (0.025,0.025) [0.025|20] "m"  COO11
 SG_ LonGndVel_R_19 : 74|13@1+ (0.0625,-170) [-170|170] "m/s"  COO11
 SG_ LonGndVelStd_R_19 : 87|10@1+ (0.025,0.025) [0.025|14] "m/s"  COO11
 SG_ LatGndVel_R_19 : 97|13@1+ (0.0625,-170) [-170|170] "m/s"  COO11
 SG_ LatGndVelStd_R_19 : 110|10@1+ (0.025,0.025) [0.025|14] "m/s"  COO11
 SG_ ExistenceProbability_R_19 : 120|8@1+ (0.4,0) [0|100] "%"  COO11
 SG_ Width_R_19 : 128|8@1+ (0.1,0) [0|4] "m"  COO11
 SG_ Length_R_19 : 136|10@1+ (0.1,0) [0|60] "m"  COO11
 SG_ HeadingAngle_R_19 : 146|8@1+ (0.02618,-3.1416) [-3.1416|3.1416] "rad"  COO11
 SG_ DynamicProperty_R_19 : 154|3@1+ (1,0) [0|5] "-"  COO11
 SG_ ClassMostProb_R_19 : 157|3@1+ (1,0) [0|5] "-"  COO11
 SG_ ClassMostProbConf_R_19 : 160|8@1+ (0.4,0) [0|100] "%"  COO11
 SG_ ClassSecMostProb_R_19 : 168|3@1+ (1,0) [0|5] "-"  COO11
 SG_ ClassSecMostProbConf_R_19 : 171|8@1+ (0.4,0) [0|100] "%"  COO11
 SG_ MaintenanceState_R_19 : 179|3@1+ (1,0) [0|3] "-"  COO11
 SG_ YawRate_R_19 : 182|16@1+ (0.0001220703125,-3) [-3|3] "rad/s"  COO11
 SG_ Occlusion_R_19 : 198|3@1+ (1,0) [0|3] "-"  COO11
 SG_ TrackingId_R_19 : 201|8@1+ (1,0) [0|250] "-"  COO11
 SG_ ReferencePoint_R_19 : 209|4@1+ (1,0) [0|8] "-"  COO11
 SG_ RadarCrossSection_R_19 : 213|11@1+ (0.1,-100) [-100|100] "dBm²"  COO11
 SG_ AgeSinceCreated_R_19 : 224|10@1+ (0.01,0) [0|10] "s"  COO11
 SG_ LonPosition_R_20 : 268|13@1+ (0.0625,-254.9375) [-254.9375|254.9375] "m"  COO11
 SG_ LonPositionStd_R_20 : 281|10@1+ (0.025,0.025) [0.025|20] "m"  COO11
 SG_ LatPosition_R_20 : 291|13@1+ (0.0625,-254.9375) [-254.9375|254.9375] "m"  COO11
 SG_ LatPositionStd_R_20 : 304|10@1+ (0.025,0.025) [0.025|20] "m"  COO11
 SG_ LonGndVel_R_20 : 314|13@1+ (0.0625,-170) [-170|170] "m/s"  COO11
 SG_ LonGndVelStd_R_20 : 327|10@1+ (0.025,0.025) [0.025|14] "m/s"  COO11
 SG_ LatGndVel_R_20 : 337|13@1+ (0.0625,-170) [-170|170] "m/s"  COO11
 SG_ LatGndVelStd_R_20 : 350|10@1+ (0.025,0.025) [0.025|14] "m/s"  COO11
 SG_ ExistenceProbability_R_20 : 360|8@1+ (0.4,0) [0|100] "%"  COO11
 SG_ Width_R_20 : 368|8@1+ (0.1,0) [0|4] "m"  COO11
 SG_ Length_R_20 : 376|10@1+ (0.1,0) [0|60] "m"  COO11
 SG_ HeadingAngle_R_20 : 386|8@1+ (0.02618,-3.1416) [-3.1416|3.1416] "rad"  COO11
 SG_ DynamicProperty_R_20 : 394|3@1+ (1,0) [0|5] "-"  COO11
 SG_ ClassMostProb_R_20 : 397|3@1+ (1,0) [0|5] "-"  COO11
 SG_ ClassMostProbConf_R_20 : 400|8@1+ (0.4,0) [0|100] "%"  COO11
 SG_ ClassSecMostProb_R_20 : 408|3@1+ (1,0) [0|5] "-"  COO11
 SG_ ClassSecMostProbConf_R_20 : 411|8@1+ (0.4,0) [0|100] "%"  COO11
 SG_ MaintenanceState_R_20 : 419|3@1+ (1,0) [0|3] "-"  COO11
 SG_ YawRate_R_20 : 422|16@1+ (0.0001220703125,-3) [-3|3] "rad/s"  COO11
 SG_ Occlusion_R_20 : 438|3@1+ (1,0) [0|3] "-"  COO11
 SG_ TrackingId_R_20 : 441|8@1+ (1,0) [0|250] "-"  COO11
 SG_ ReferencePoint_R_20 : 449|4@1+ (1,0) [0|8] "-"  COO11
 SG_ RadarCrossSection_R_20 : 453|11@1+ (0.1,-100) [-100|100] "dbm²"  COO11
 SG_ AgeSinceCreated_R_20 : 464|10@1+ (0.01,0) [0|10] "s"  COO11

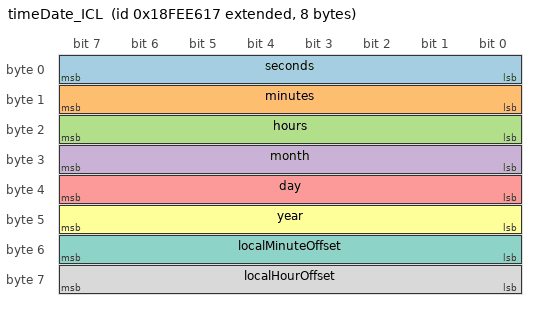
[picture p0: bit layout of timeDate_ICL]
BO_ 2566841879 timeDate_ICL: 8 ICL
 SG_ seconds : 0|8@1+ (0.25,0) [0|62.5] "s"  SRR6TRightMaster_R_Master,SRR6TLeftMaster_L_Master
 SG_ minutes : 8|8@1+ (1,0) [0|250] "min"  SRR6TRightMaster_R_Master,SRR6TLeftMaster_L_Master
 SG_ hours : 16|8@1+ (1,0) [0|250] "h"  SRR6TRightMaster_R_Master,SRR6TLeftMaster_L_Master
 SG_ month : 24|8@1+ (1,0) [0|250] "month"  SRR6TRightMaster_R_Master,SRR6TLeftMaster_L_Master
 SG_ day : 32|8@1+ (0.25,0) [0|62.5] "day"  SRR6TRightMaster_R_Master,SRR6TLeftMaster_L_Master
 SG_ year : 40|8@1+ (1,1985) [1985|2235] "year"  SRR6TRightMaster_R_Master,SRR6TLeftMaster_L_Master
 SG_ localMinuteOffset : 48|8@1+ (1,-125) [-125|125] "min"  SRR6TRightMaster_R_Master,SRR6TLeftMaster_L_Master
 SG_ localHourOffset : 56|8@1+ (1,-125) [-125|125] "h"  SRR6TRightMaster_R_Master,SRR6TLeftMaster_L_Master

BO_ 2399092775 SRR2_SensorInput_K: 16 COO11
 SG_ SRR2_Input_E2E_CRC : 0|16@1+ (1,0) [0|65535] "-"  SRR6TRightMaster_R_Master,SRR6TLeftMaster_L_Master
 SG_ SRR2_Input_E2E_Counter : 16|8@1+ (1,0) [0|255] "-"  SRR6TRightMaster_R_Master,SRR6TLeftMaster_L_Master
 SG_ VehicleSpeed : 24|16@1+ (0.00390625,-50) [-50|200.99609375] "km/h"  SRR6TRightMaster_R_Master,SRR6TLeftMaster_L_Master
 SG_ YawRate : 40|16@1+ (0.0001220703125,-3.9217529296875) [-3.9217529296875|3.9217529296875] "rad/s"  SRR6TRightMaster_R_Master,SRR6TLeftMaster_L_Master
 SG_ LongitudinalAcceleration : 56|8@1+ (0.1,-12.5) [-12.5|12.5] "m/s^2"  SRR6TRightMaster_R_Master,SRR6TLeftMaster_L_Master
 SG_ LateralAcceleration : 64|16@1+ (0.00048828125,-15.68701171875) [-15.68701171875|15.68701171875] "m/s^2"  SRR6TRightMaster_R_Master,SRR6TLeftMaster_L_Master
 SG_ EffectiveWheelBase : 80|8@1+ (0.05,0) [0|12.65] "m"  SRR6TRightMaster_R_Master,SRR6TLeftMaster_L_Master
 SG_ SteeringWheelAngle : 88|16@1+ (0.0009765625,-31.3740234375) [-31.3740234375|31.3740234375] "rad"  SRR6TRightMaster_R_Master,SRR6TLeftMaster_L_Master
 SG_ TrailerConnection : 104|2@1+ (1,0) [0|3] ""  SRR6TRightMaster_R_Master,SRR6TLeftMaster_L_Master
 SG_ ParkingBrakeStatus : 106|2@1+ (1,0) [0|3] ""  SRR6TRightMaster_R_Master,SRR6TLeftMaster_L_Master
 SG_ VehicleSpeed_QF : 108|2@1+ (1,0) [0|3] ""  SRR6TRightMaster_R_Master,SRR6TLeftMaster_L_Master
 SG_ YawRate_QF : 110|2@1+ (1,0) [0|3] ""  SRR6TRightMaster_R_Master,SRR6TLeftMaster_L_Master
 SG_ missionMode : 112|2@1+ (1,0) [0|3] ""  SRR6TRightMaster_R_Master,SRR6TLeftMaster_L_Master

BO_ 2631663611 UDSreq_FCN_FB_2SRR: 8 COO11
 SG_ SRR6T_FCN_Diag_Request : 0|64@1+ (1,0) [0|0] ""  SRR6TRightMaster_R_Master,SRR6TLeftMaster_L_Master

BO_ 2631663609 UDSreq_FCN_F9_2SRR: 8 COO11
 SG_ SRR6T_FCN_Diag_Request : 0|64@1+ (1,0) [0|0] ""  SRR6TRightMaster_R_Master,SRR6TLeftMaster_L_Master

BO_ 2631663601 UDSreq_FCN_F1_2SRR: 8 COO11
 SG_ SRR6T_FCN_Diag_Request : 0|64@1+ (1,0) [0|0] ""  SRR6TRightMaster_R_Master,SRR6TLeftMaster_L_Master

BO_ 2631663434 UDSreq_FCN_4A_2SRR: 8 COO11
 SG_ SRR6T_FCN_Diag_Request : 0|64@1+ (1,0) [0|0] ""  SRR6TRightMaster_R_Master,SRR6TLeftMaster_L_Master

BO_ 2631663403 UDSreq_FCN_2B_2SRR: 8 COO11
 SG_ SRR6T_FCN_Diag_Request : 0|64@1+ (1,0) [0|0] ""  SRR6TRightMaster_R_Master,SRR6TLeftMaster_L_Master

BO_ 2631663383 UDSreq_FCN_17_2SRR: 8 COO11
 SG_ SRR6T_FCN_Diag_Request : 0|64@1+ (1,0) [0|0] ""  SRR6TRightMaster_R_Master,SRR6TLeftMaster_L_Master

BO_ 2564554747 UDSreq_FCN_FB2SRR: 8 COO11
 SG_ SRR6T_FCN_Diag_Request : 0|64@1+ (1,0) [0|0] ""  SRR6TRightMaster_R_Master,SRR6TLeftMaster_L_Master

BO_ 2564554746 UDSreq_FCN_FA2SRR: 8 COO11
 SG_ SRR6T_FCN_Diag_Request : 0|64@1+ (1,0) [0|0] ""  SRR6TRightMaster_R_Master,SRR6TLeftMaster_L_Master

BO_ 2564554745 UDSreq_FCN_F92SRR: 8 COO11
 SG_ SRR6T_FCN_Diag_Request : 0|64@1+ (1,0) [0|0] ""  SRR6TRightMaster_R_Master,SRR6TLeftMaster_L_Master

BO_ 2564554570 UDSreq_FCN_4A2SRR: 8 COO11
 SG_ SRR6T_FCN_Diag_Request : 0|64@1+ (1,0) [0|0] ""  SRR6TRightMaster_R_Master,SRR6TLeftMaster_L_Master

BO_ 2564554539 UDSreq_FCN_2B2SRR: 8 COO11
 SG_ SRR6T_FCN_Diag_Request : 0|64@1+ (1,0) [0|0] ""  SRR6TRightMaster_R_Master,SRR6TLeftMaster_L_Master

BO_ 2564554519 UDSreq_FCN_172SRR: 8 COO11
 SG_ SRR6T_FCN_Diag_Request : 0|64@1+ (1,0) [0|0] ""  SRR6TRightMaster_R_Master,SRR6TLeftMaster_L_Master

BO_ 2564488079 UDSresp_FB2SRR_RR: 8 SRR6TRightMaster_R_Master
 SG_ SRR6T_R_Diag_Response : 0|64@1+ (1,0) [0|0] ""  COO11

BO_ 2564488077 UDSresp_FB2SRR_RL: 8 SRR6TLeftMaster_L_Master
 SG_ SRR6T_L_Diag_Response : 0|64@1+ (1,0) [0|0] ""  COO11

BO_ 2564488078 UDSresp_FB2SRR_FR: 8 SRR6TRightMaster_R_Master
 SG_ SRR6T_R_Diag_Response : 0|64@1+ (1,0) [0|0] ""  COO11

BO_ 2564488076 UDSresp_FB2SRR_FL: 8 SRR6TLeftMaster_L_Master
 SG_ SRR6T_L_Diag_Response : 0|64@1+ (1,0) [0|0] ""  COO11

BO_ 2564487823 UDSresp_FA2SRR_RR: 8 SRR6TRightMaster_R_Master
 SG_ SRR6T_R_Diag_Response : 0|64@1+ (1,0) [0|0] ""  COO11

BO_ 2564487821 UDSresp_FA2SRR_RL: 8 SRR6TLeftMaster_L_Master
 SG_ SRR6T_L_Diag_Response : 0|64@1+ (1,0) [0|0] ""  COO11

BO_ 2564487822 UDSresp_FA2SRR_FR: 8 SRR6TRightMaster_R_Master
 SG_ SRR6T_R_Diag_Response : 0|64@1+ (1,0) [0|0] ""  COO11

BO_ 2564487820 UDSresp_FA2SRR_FL: 8 SRR6TLeftMaster_L_Master
 SG_ SRR6T_L_Diag_Response : 0|64@1+ (1,0) [0|0] ""  COO11

BO_ 2564487567 UDSresp_F92SRR_RR: 8 SRR6TRightMaster_R_Master
 SG_ SRR6T_R_Diag_Response : 0|64@1+ (1,0) [0|0] ""  COO11

BO_ 2564487565 UDSresp_F92SRR_RL: 8 SRR6TLeftMaster_L_Master
 SG_ SRR6T_L_Diag_Response : 0|64@1+ (1,0) [0|0] ""  COO11

BO_ 2564487566 UDSresp_F92SRR_FR: 8 SRR6TRightMaster_R_Master
 SG_ SRR6T_R_Diag_Response : 0|64@1+ (1,0) [0|0] ""  COO11

BO_ 2564487564 UDSresp_F92SRR_FL: 8 SRR6TLeftMaster_L_Master
 SG_ SRR6T_L_Diag_Response : 0|64@1+ (1,0) [0|0] ""  COO11

BO_ 2564442767 UDSresp_4A2SRR_RR: 8 SRR6TRightMaster_R_Master
 SG_ SRR6T_R_Diag_Response : 0|64@1+ (1,0) [0|0] ""  COO11

BO_ 2564442765 UDSresp_4A2SRR_RL: 8 SRR6TLeftMaster_L_Master
 SG_ SRR6T_L_Diag_Response : 0|64@1+ (1,0) [0|0] ""  COO11

BO_ 2564442766 UDSresp_4A2SRR_FR: 8 SRR6TRightMaster_R_Master
 SG_ SRR6T_R_Diag_Response : 0|64@1+ (1,0) [0|0] ""  COO11

BO_ 2564442764 UDSresp_4A2SRR_FL: 8 SRR6TLeftMaster_L_Master
 SG_ SRR6T_L_Diag_Response : 0|64@1+ (1,0) [0|0] ""  COO11

BO_ 2564434831 UDSresp_2B2SRR_RR: 8 SRR6TRightMaster_R_Master
 SG_ SRR6T_R_Diag_Response : 0|64@1+ (1,0) [0|0] ""  COO11

BO_ 2564434829 UDSresp_2B2SRR_RL: 8 SRR6TLeftMaster_L_Master
 SG_ SRR6T_L_Diag_Response : 0|64@1+ (1,0) [0|0] ""  COO11

BO_ 2564434830 UDSresp_2B2SRR_FR: 8 SRR6TRightMaster_R_Master
 SG_ SRR6T_R_Diag_Response : 0|64@1+ (1,0) [0|0] ""  COO11

BO_ 2564434828 UDSresp_2B2SRR_FL: 8 SRR6TLeftMaster_L_Master
 SG_ SRR6T_L_Diag_Response : 0|64@1+ (1,0) [0|0] ""  COO11

BO_ 2564429711 UDSresp_172SRR_RR: 8 SRR6TRightMaster_R_Master
 SG_ SRR6T_R_Diag_Response : 0|64@1+ (1,0) [0|0] ""  COO11

BO_ 2564429709 UDSresp_172SRR_RL: 8 SRR6TLeftMaster_L_Master
 SG_ SRR6T_L_Diag_Response : 0|64@1+ (1,0) [0|0] ""  COO11

BO_ 2564429710 UDSresp_172SRR_FR: 8 SRR6TRightMaster_R_Master
 SG_ SRR6T_R_Diag_Response : 0|64@1+ (1,0) [0|0] ""  COO11

BO_ 2564429708 UDSresp_172SRR_FL: 8 SRR6TLeftMaster_L_Master
 SG_ SRR6T_L_Diag_Response : 0|64@1+ (1,0) [0|0] ""  COO11

BO_ 2564460539 UDSreq_FB2SRR_RR: 8 COO11
 SG_ SRR6T_R_Diag_Request : 0|64@1+ (1,0) [0|0] ""  SRR6TRightMaster_R_Master

BO_ 2564460027 UDSreq_FB2SRR_RL: 8 COO11
 SG_ SRR6T_L_Diag_Request : 0|64@1+ (1,0) [0|0] ""  SRR6TLeftMaster_L_Master

BO_ 2564460283 UDSreq_FB2SRR_FR: 8 COO11
 SG_ SRR6T_R_Diag_Request : 0|64@1+ (1,0) [0|0] ""  SRR6TRightMaster_R_Master

BO_ 2564459771 UDSreq_FB2SRR_FL: 8 COO11
 SG_ SRR6T_L_Diag_Request : 0|64@1+ (1,0) [0|0] ""  SRR6TLeftMaster_L_Master

BO_ 2564460538 UDSreq_FA2SRR_RR: 8 COO11
 SG_ SRR6T_R_Diag_Request : 0|64@1+ (1,0) [0|0] ""  SRR6TRightMaster_R_Master

BO_ 2564460026 UDSreq_FA2SRR_RL: 8 COO11
 SG_ SRR6T_L_Diag_Request : 0|64@1+ (1,0) [0|0] ""  SRR6TLeftMaster_L_Master

BO_ 2564460282 UDSreq_FA2SRR_FR: 8 COO11
 SG_ SRR6T_R_Diag_Request : 0|64@1+ (1,0) [0|0] ""  SRR6TRightMaster_R_Master

BO_ 2564459770 UDSreq_FA2SRR_FL: 8 COO11
 SG_ SRR6T_L_Diag_Request : 0|64@1+ (1,0) [0|0] ""  SRR6TLeftMaster_L_Master

BO_ 2564460537 UDSreq_F92SRR_RR: 8 COO11
 SG_ SRR6T_R_Diag_Request : 0|64@1+ (1,0) [0|0] ""  SRR6TRightMaster_R_Master

BO_ 2564460025 UDSreq_F92SRR_RL: 8 COO11
 SG_ SRR6T_L_Diag_Request : 0|64@1+ (1,0) [0|0] ""  SRR6TLeftMaster_L_Master

BO_ 2564460281 UDSreq_F92SRR_FR: 8 COO11
 SG_ SRR6T_R_Diag_Request : 0|64@1+ (1,0) [0|0] ""  SRR6TRightMaster_R_Master

BO_ 2564459769 UDSreq_F92SRR_FL: 8 COO11
 SG_ SRR6T_L_Diag_Request : 0|64@1+ (1,0) [0|0] ""  SRR6TLeftMaster_L_Master

BO_ 2564460362 UDSreq_4A2SRR_RR: 8 COO11
 SG_ SRR6T_R_Diag_Request : 0|64@1+ (1,0) [0|0] ""  SRR6TRightMaster_R_Master

BO_ 2564459850 UDSreq_4A2SRR_RL: 8 COO11
 SG_ SRR6T_L_Diag_Request : 0|64@1+ (1,0) [0|0] ""  SRR6TLeftMaster_L_Master

BO_ 2564460106 UDSreq_4A2SRR_FR: 8 COO11
 SG_ SRR6T_R_Diag_Request : 0|64@1+ (1,0) [0|0] ""  SRR6TRightMaster_R_Master

BO_ 2564459594 UDSreq_4A2SRR_FL: 8 COO11
 SG_ SRR6T_L_Diag_Request : 0|64@1+ (1,0) [0|0] ""  SRR6TLeftMaster_L_Master

BO_ 2564460331 UDSreq_2B2SRR_RR: 8 COO11
 SG_ SRR6T_R_Diag_Request : 0|64@1+ (1,0) [0|0] ""  SRR6TRightMaster_R_Master

BO_ 2564459819 UDSreq_2B2SRR_RL: 8 COO11
 SG_ SRR6T_L_Diag_Request : 0|64@1+ (1,0) [0|0] ""  SRR6TLeftMaster_L_Master

BO_ 2564460075 UDSreq_2B2SRR_FR: 8 COO11
 SG_ SRR6T_R_Diag_Request : 0|64@1+ (1,0) [0|0] ""  SRR6TRightMaster_R_Master

BO_ 2564459563 UDSreq_2B2SRR_FL: 8 COO11
 SG_ SRR6T_L_Diag_Request : 0|64@1+ (1,0) [0|0] ""  SRR6TLeftMaster_L_Master

BO_ 2564460311 UDSreq_172SRR_RR: 8 COO11
 SG_ SRR6T_R_Diag_Request : 0|64@1+ (1,0) [0|0] ""  SRR6TRightMaster_R_Master

BO_ 2564459799 UDSreq_172SRR_RL: 8 COO11
 SG_ SRR6T_L_Diag_Request : 0|64@1+ (1,0) [0|0] ""  SRR6TLeftMaster_L_Master

BO_ 2564460055 UDSreq_172SRR_FR: 8 COO11
 SG_ SRR6T_R_Diag_Request : 0|64@1+ (1,0) [0|0] ""  SRR6TRightMaster_R_Master

BO_ 2564459543 UDSreq_172SRR_FL: 8 COO11
 SG_ SRR6T_L_Diag_Request : 0|64@1+ (1,0) [0|0] ""  SRR6TLeftMaster_L_Master

BO_ 2631596931 UDSresp_FB_2SRR_RR: 8 SRR6TRightMaster_R_Master
 SG_ SRR6T_R_Diag_Response : 0|64@1+ (1,0) [0|0] ""  COO11

BO_ 2631596933 UDSresp_FB_2SRR_RL: 8 SRR6TLeftMaster_L_Master
 SG_ SRR6T_L_Diag_Response : 0|64@1+ (1,0) [0|0] ""  COO11

BO_ 2631596930 UDSresp_FB_2SRR_FR: 8 SRR6TRightMaster_R_Master
 SG_ SRR6T_R_Diag_Response : 0|64@1+ (1,0) [0|0] ""  COO11

BO_ 2631596932 UDSresp_FB_2SRR_FL: 8 SRR6TLeftMaster_L_Master
 SG_ SRR6T_L_Diag_Response : 0|64@1+ (1,0) [0|0] ""  COO11

BO_ 2631566331 UDSreq_FB_2SRR_RR: 8 COO11
 SG_ SRR6T_R_Diag_Request : 0|64@1+ (1,0) [0|0] ""  SRR6TRightMaster_R_Master

BO_ 2631566843 UDSreq_FB_2SRR_RL: 8 COO11
 SG_ SRR6T_L_Diag_Request : 0|64@1+ (1,0) [0|0] ""  SRR6TLeftMaster_L_Master

BO_ 2631566075 UDSreq_FB_2SRR_FR: 8 COO11
 SG_ SRR6T_R_Diag_Request : 0|64@1+ (1,0) [0|0] ""  SRR6TRightMaster_R_Master

BO_ 2631566587 UDSreq_FB_2SRR_FL: 8 COO11
 SG_ SRR6T_L_Diag_Request : 0|64@1+ (1,0) [0|0] ""  SRR6TLeftMaster_L_Master

BO_ 2631596419 UDSresp_F9_2SRR_RR: 8 SRR6TRightMaster_R_Master
 SG_ SRR6T_R_Diag_Response : 0|64@1+ (1,0) [0|0] ""  COO11

BO_ 2631596421 UDSresp_F9_2SRR_RL: 8 SRR6TLeftMaster_L_Master
 SG_ SRR6T_L_Diag_Response : 0|64@1+ (1,0) [0|0] ""  COO11

BO_ 2631596418 UDSresp_F9_2SRR_FR: 8 SRR6TRightMaster_R_Master
 SG_ SRR6T_R_Diag_Response : 0|64@1+ (1,0) [0|0] ""  COO11

BO_ 2631596420 UDSresp_F9_2SRR_FL: 8 SRR6TLeftMaster_L_Master
 SG_ SRR6T_L_Diag_Response : 0|64@1+ (1,0) [0|0] ""  COO11

BO_ 2631566329 UDSreq_F9_2SRR_RR: 8 COO11
 SG_ SRR6T_R_Diag_Request : 0|64@1+ (1,0) [0|0] ""  SRR6TRightMaster_R_Master

BO_ 2631566841 UDSreq_F9_2SRR_RL: 8 COO11
 SG_ SRR6T_L_Diag_Request : 0|64@1+ (1,0) [0|0] ""  SRR6TLeftMaster_L_Master

BO_ 2631566073 UDSreq_F9_2SRR_FR: 8 COO11
 SG_ SRR6T_R_Diag_Request : 0|64@1+ (1,0) [0|0] ""  SRR6TRightMaster_R_Master

BO_ 2631566585 UDSreq_F9_2SRR_FL: 8 COO11
 SG_ SRR6T_L_Diag_Request : 0|64@1+ (1,0) [0|0] ""  SRR6TLeftMaster_L_Master

BO_ 2631594371 UDSresp_F1_2SRR_RR: 8 SRR6TRightMaster_R_Master
 SG_ SRR6T_R_Diag_Response : 0|64@1+ (1,0) [0|0] ""  COO11

BO_ 2631594373 UDSresp_F1_2SRR_RL: 8 SRR6TLeftMaster_L_Master
 SG_ SRR6T_L_Diag_Response : 0|64@1+ (1,0) [0|0] ""  COO11

BO_ 2631594370 UDSresp_F1_2SRR_FR: 8 SRR6TRightMaster_R_Master
 SG_ SRR6T_R_Diag_Response : 0|64@1+ (1,0) [0|0] ""  COO11

BO_ 2631594372 UDSresp_F1_2SRR_FL: 8 SRR6TLeftMaster_L_Master
 SG_ SRR6T_L_Diag_Response : 0|64@1+ (1,0) [0|0] ""  COO11

BO_ 2631566321 UDSreq_F1_2SRR_RR: 8 COO11
 SG_ SRR6T_R_Diag_Request : 0|64@1+ (1,0) [0|0] ""  SRR6TRightMaster_R_Master

BO_ 2631566833 UDSreq_F1_2SRR_RL: 8 COO11
 SG_ SRR6T_L_Diag_Request : 0|64@1+ (1,0) [0|0] ""  SRR6TLeftMaster_L_Master

BO_ 2631566065 UDSreq_F1_2SRR_FR: 8 COO11
 SG_ SRR6T_R_Diag_Request : 0|64@1+ (1,0) [0|0] ""  SRR6TRightMaster_R_Master

BO_ 2631566577 UDSreq_F1_2SRR_FL: 8 COO11
 SG_ SRR6T_L_Diag_Request : 0|64@1+ (1,0) [0|0] ""  SRR6TLeftMaster_L_Master

BO_ 2631566154 UDSreq_4A_2SRR_RR: 8 COO11
 SG_ SRR6T_R_Diag_Request : 0|64@1+ (1,0) [0|0] ""  SRR6TRightMaster_R_Master

BO_ 2631566666 UDSreq_4A_2SRR_RL: 8 COO11
 SG_ SRR6T_L_Diag_Request : 0|64@1+ (1,0) [0|0] ""  SRR6TLeftMaster_L_Master

BO_ 2631565898 UDSreq_4A_2SRR_FR: 8 COO11
 SG_ SRR6T_R_Diag_Request : 0|64@1+ (1,0) [0|0] ""  SRR6TRightMaster_R_Master

BO_ 2631566410 UDSreq_4A_2SRR_FL: 8 COO11
 SG_ SRR6T_L_Diag_Request : 0|64@1+ (1,0) [0|0] ""  SRR6TLeftMaster_L_Master

BO_ 2631566123 UDSreq_2B_2SRR_RR: 8 COO11
 SG_ SRR6T_R_Diag_Request : 0|64@1+ (1,0) [0|0] ""  SRR6TRightMaster_R_Master

BO_ 2631566635 UDSreq_2B_2SRR_RL: 8 COO11
 SG_ SRR6T_L_Diag_Request : 0|64@1+ (1,0) [0|0] ""  SRR6TLeftMaster_L_Master

BO_ 2631565867 UDSreq_2B_2SRR_FR: 8 COO11
 SG_ SRR6T_R_Diag_Request : 0|64@1+ (1,0) [0|0] ""  SRR6TRightMaster_R_Master

BO_ 2631566379 UDSreq_2B_2SRR_FL: 8 COO11
 SG_ SRR6T_L_Diag_Request : 0|64@1+ (1,0) [0|0] ""  SRR6TLeftMaster_L_Master

BO_ 2631551619 UDSresp_4A_2SRR_RR: 8 SRR6TRightMaster_R_Master
 SG_ SRR6T_R_Diag_Response : 0|64@1+ (1,0) [0|0] ""  COO11

BO_ 2631551621 UDSresp_4A_2SRR_RL: 8 SRR6TLeftMaster_L_Master
 SG_ SRR6T_L_Diag_Response : 0|64@1+ (1,0) [0|0] ""  COO11

BO_ 2631551618 UDSresp_4A_2SRR_FR: 8 SRR6TRightMaster_R_Master
 SG_ SRR6T_R_Diag_Response : 0|64@1+ (1,0) [0|0] ""  COO11

BO_ 2631551620 UDSresp_4A_2SRR_FL: 8 SRR6TLeftMaster_L_Master
 SG_ SRR6T_L_Diag_Response : 0|64@1+ (1,0) [0|0] ""  COO11

BO_ 2631543683 UDSresp_2B_2SRR_RR: 8 SRR6TRightMaster_R_Master
 SG_ SRR6T_R_Diag_Response : 0|64@1+ (1,0) [0|0] ""  COO11

BO_ 2631543685 UDSresp_2B_2SRR_RL: 8 SRR6TLeftMaster_L_Master
 SG_ SRR6T_L_Diag_Response : 0|64@1+ (1,0) [0|0] ""  COO11

BO_ 2631543682 UDSresp_2B_2SRR_FR: 8 SRR6TRightMaster_R_Master
 SG_ SRR6T_R_Diag_Response : 0|64@1+ (1,0) [0|0] ""  COO11

BO_ 2631543684 UDSresp_2B_2SRR_FL: 8 SRR6TLeftMaster_L_Master
 SG_ SRR6T_L_Diag_Response : 0|64@1+ (1,0) [0|0] ""  COO11

BO_ 2631538563 UDSresp_17_2SRR_RR: 8 SRR6TRightMaster_R_Master
 SG_ SRR6T_R_Diag_Response : 0|64@1+ (1,0) [0|0] ""  COO11

BO_ 2631538565 UDSresp_17_2SRR_RL: 8 SRR6TLeftMaster_L_Master
 SG_ SRR6T_L_Diag_Response : 0|64@1+ (1,0) [0|0] ""  COO11

BO_ 2631538562 UDSresp_17_2SRR_FR: 8 SRR6TRightMaster_R_Master
 SG_ SRR6T_R_Diag_Response : 0|64@1+ (1,0) [0|0] ""  COO11

BO_ 2631538564 UDSresp_17_2SRR_FL: 8 SRR6TLeftMaster_L_Master
 SG_ SRR6T_L_Diag_Response : 0|64@1+ (1,0) [0|0] ""  COO11

BO_ 2631566103 UDSreq_17_2SRR_RR: 8 COO11
 SG_ SRR6T_R_Diag_Request : 0|64@1+ (1,0) [0|0] ""  SRR6TRightMaster_R_Master

BO_ 2631566615 UDSreq_17_2SRR_RL: 8 COO11
 SG_ SRR6T_L_Diag_Request : 0|64@1+ (1,0) [0|0] ""  SRR6TLeftMaster_L_Master

BO_ 2631565847 UDSreq_17_2SRR_FR: 8 COO11
 SG_ SRR6T_R_Diag_Request : 0|64@1+ (1,0) [0|0] ""  SRR6TRightMaster_R_Master

BO_ 2631566359 UDSreq_17_2SRR_FL: 8 COO11
 SG_ SRR6T_L_Diag_Request : 0|64@1+ (1,0) [0|0] ""  SRR6TLeftMaster_L_Master

BO_ 2631583107 UDSresp_C5_2SRR_RR: 8 SRR6TRightMaster_R_Master
 SG_ SRR6T_R_Diag_Response : 0|64@1+ (1,0) [0|0] ""  COO11

BO_ 2631582851 UDSresp_C4_2SRR_RR: 8 SRR6TRightMaster_R_Master
 SG_ SRR6T_R_Diag_Response : 0|64@1+ (1,0) [0|0] ""  COO11

BO_ 2631582595 UDSresp_C3_2SRR_RR: 8 SRR6TRightMaster_R_Master
 SG_ SRR6T_R_Diag_Response : 0|64@1+ (1,0) [0|0] ""  COO11

BO_ 2631582339 UDSresp_C2_2SRR_RR: 8 SRR6TRightMaster_R_Master
 SG_ SRR6T_R_Diag_Response : 0|64@1+ (1,0) [0|0] ""  COO11

BO_ 2631583109 UDSresp_C5_2SRR_RL: 8 SRR6TLeftMaster_L_Master
 SG_ SRR6T_L_Diag_Response : 0|64@1+ (1,0) [0|0] ""  COO11

BO_ 2631582853 UDSresp_C4_2SRR_RL: 8 SRR6TLeftMaster_L_Master
 SG_ SRR6T_L_Diag_Response : 0|64@1+ (1,0) [0|0] ""  COO11

BO_ 2631582597 UDSresp_C3_2SRR_RL: 8 SRR6TLeftMaster_L_Master
 SG_ SRR6T_L_Diag_Response : 0|64@1+ (1,0) [0|0] ""  COO11

BO_ 2631582341 UDSresp_C2_2SRR_RL: 8 SRR6TLeftMaster_L_Master
 SG_ SRR6T_L_Diag_Response : 0|64@1+ (1,0) [0|0] ""  COO11

BO_ 2631583106 UDSresp_C5_2SRR_FR: 8 SRR6TRightMaster_R_Master
 SG_ SRR6T_R_Diag_Response : 0|64@1+ (1,0) [0|0] ""  COO11

BO_ 2631582850 UDSresp_C4_2SRR_FR: 8 SRR6TRightMaster_R_Master
 SG_ SRR6T_R_Diag_Response : 0|64@1+ (1,0) [0|0] ""  COO11

BO_ 2631582594 UDSresp_C3_2SRR_FR: 8 SRR6TRightMaster_R_Master
 SG_ SRR6T_R_Diag_Response : 0|64@1+ (1,0) [0|0] ""  COO11

BO_ 2631582338 UDSresp_C2_2SRR_FR: 8 SRR6TRightMaster_R_Master
 SG_ SRR6T_R_Diag_Response : 0|64@1+ (1,0) [0|0] ""  COO11

BO_ 2631583108 UDSresp_C5_2SRR_FL: 8 SRR6TLeftMaster_L_Master
 SG_ SRR6T_L_Diag_Response : 0|64@1+ (1,0) [0|0] ""  COO11

BO_ 2631582852 UDSresp_C4_2SRR_FL: 8 SRR6TLeftMaster_L_Master
 SG_ SRR6T_L_Diag_Response : 0|64@1+ (1,0) [0|0] ""  COO11

BO_ 2631582596 UDSresp_C3_2SRR_FL: 8 SRR6TLeftMaster_L_Master
 SG_ SRR6T_L_Diag_Response : 0|64@1+ (1,0) [0|0] ""  COO11

BO_ 2631582340 UDSresp_C2_2SRR_FL: 8 SRR6TLeftMaster_L_Master
 SG_ SRR6T_L_Diag_Response : 0|64@1+ (1,0) [0|0] ""  COO11

BO_ 2631582083 UDSresp_C1_2SRR_RR: 8 SRR6TRightMaster_R_Master
 SG_ SRR6T_R_Diag_Response : 0|64@1+ (1,0) [0|0] ""  COO11

BO_ 2631581827 UDSresp_C0_2SRR_RR: 8 SRR6TRightMaster_R_Master
 SG_ SRR6T_R_Diag_Response : 0|64@1+ (1,0) [0|0] ""  COO11

BO_ 2631581829 UDSresp_C0_2SRR_RL: 8 SRR6TLeftMaster_L_Master
 SG_ SRR6T_L_Diag_Response : 0|64@1+ (1,0) [0|0] ""  COO11

BO_ 2631581826 UDSresp_C0_2SRR_FR: 8 SRR6TRightMaster_R_Master
 SG_ SRR6T_R_Diag_Response : 0|64@1+ (1,0) [0|0] ""  COO11

BO_ 2631581828 UDSresp_C0_2SRR_FL: 8 SRR6TLeftMaster_L_Master
 SG_ SRR6T_L_Diag_Response : 0|64@1+ (1,0) [0|0] ""  COO11

BO_ 2631582085 UDSresp_C1_2SRR_RL: 8 SRR6TLeftMaster_L_Master
 SG_ SRR6T_L_Diag_Response : 0|64@1+ (1,0) [0|0] ""  COO11

BO_ 2631582082 UDSresp_C1_2SRR_FR: 8 SRR6TRightMaster_R_Master
 SG_ SRR6T_R_Diag_Response : 0|64@1+ (1,0) [0|0] ""  COO11

BO_ 2631582084 UDSresp_C1_2SRR_FL: 8 SRR6TLeftMaster_L_Master
 SG_ SRR6T_L_Diag_Response : 0|64@1+ (1,0) [0|0] ""  COO11

BO_ 2631566277 UDSreq_C5_2SRR_RR: 8 COO11
 SG_ SRR6T_R_Diag_Request : 0|64@1+ (1,0) [0|0] ""  SRR6TRightMaster_R_Master

BO_ 2631566276 UDSreq_C4_2SRR_RR: 8 COO11
 SG_ SRR6T_R_Diag_Request : 0|64@1+ (1,0) [0|0] ""  SRR6TRightMaster_R_Master

BO_ 2631566275 UDSreq_C3_2SRR_RR: 8 COO11
 SG_ SRR6T_R_Diag_Request : 0|64@1+ (1,0) [0|0] ""  SRR6TRightMaster_R_Master

BO_ 2631566274 UDSreq_C2_2SRR_RR: 8 COO11
 SG_ SRR6T_R_Diag_Request : 0|64@1+ (1,0) [0|0] ""  SRR6TRightMaster_R_Master

BO_ 2631566789 UDSreq_C5_2SRR_RL: 8 COO11
 SG_ SRR6T_L_Diag_Request : 0|64@1+ (1,0) [0|0] ""  SRR6TLeftMaster_L_Master

BO_ 2631566788 UDSreq_C4_2SRR_RL: 8 COO11
 SG_ SRR6T_L_Diag_Request : 0|64@1+ (1,0) [0|0] ""  SRR6TLeftMaster_L_Master

BO_ 2631566787 UDSreq_C3_2SRR_RL: 8 COO11
 SG_ SRR6T_L_Diag_Request : 0|64@1+ (1,0) [0|0] ""  SRR6TLeftMaster_L_Master

BO_ 2631566786 UDSreq_C2_2SRR_RL: 8 COO11
 SG_ SRR6T_L_Diag_Request : 0|64@1+ (1,0) [0|0] ""  SRR6TLeftMaster_L_Master

BO_ 2631566021 UDSreq_C5_2SRR_FR: 8 COO11
 SG_ SRR6T_R_Diag_Request : 0|64@1+ (1,0) [0|0] ""  SRR6TRightMaster_R_Master

BO_ 2631566020 UDSreq_C4_2SRR_FR: 8 COO11
 SG_ SRR6T_R_Diag_Request : 0|64@1+ (1,0) [0|0] ""  SRR6TRightMaster_R_Master

BO_ 2631566019 UDSreq_C3_2SRR_FR: 8 COO11
 SG_ SRR6T_R_Diag_Request : 0|64@1+ (1,0) [0|0] ""  SRR6TRightMaster_R_Master

BO_ 2631566018 UDSreq_C2_2SRR_FR: 8 COO11
 SG_ SRR6T_R_Diag_Request : 0|64@1+ (1,0) [0|0] ""  SRR6TRightMaster_R_Master

BO_ 2631566533 UDSreq_C5_2SRR_FL: 8 COO11
 SG_ SRR6T_L_Diag_Request : 0|64@1+ (1,0) [0|0] ""  SRR6TLeftMaster_L_Master

BO_ 2631566532 UDSreq_C4_2SRR_FL: 8 COO11
 SG_ SRR6T_L_Diag_Request : 0|64@1+ (1,0) [0|0] ""  SRR6TLeftMaster_L_Master

BO_ 2631566531 UDSreq_C3_2SRR_FL: 8 COO11
 SG_ SRR6T_L_Diag_Request : 0|64@1+ (1,0) [0|0] ""  SRR6TLeftMaster_L_Master

BO_ 2631566530 UDSreq_C2_2SRR_FL: 8 COO11
 SG_ SRR6T_L_Diag_Request : 0|64@1+ (1,0) [0|0] ""  SRR6TLeftMaster_L_Master

BO_ 2631566273 UDSreq_C1_2SRR_RR: 8 COO11
 SG_ SRR6T_R_Diag_Request : 0|64@1+ (1,0) [0|0] ""  SRR6TRightMaster_R_Master

BO_ 2631566785 UDSreq_C1_2SRR_RL: 8 COO11
 SG_ SRR6T_L_Diag_Request : 0|64@1+ (1,0) [0|0] ""  SRR6TLeftMaster_L_Master

BO_ 2631566017 UDSreq_C1_2SRR_FR: 8 COO11
 SG_ SRR6T_R_Diag_Request : 0|64@1+ (1,0) [0|0] ""  SRR6TRightMaster_R_Master

BO_ 2631566529 UDSreq_C1_2SRR_FL: 8 COO11
 SG_ SRR6T_L_Diag_Request : 0|64@1+ (1,0) [0|0] ""  SRR6TLeftMaster_L_Master

BO_ 2631566272 UDSreq_C0_2SRR_RR: 8 COO11
 SG_ SRR6T_R_Diag_Request : 0|64@1+ (1,0) [0|0] ""  SRR6TRightMaster_R_Master

BO_ 2631566784 UDSreq_C0_2SRR_RL: 8 COO11
 SG_ SRR6T_L_Diag_Request : 0|64@1+ (1,0) [0|0] ""  SRR6TLeftMaster_L_Master

BO_ 2631566016 UDSreq_C0_2SRR_FR: 8 COO11
 SG_ SRR6T_R_Diag_Request : 0|64@1+ (1,0) [0|0] ""  SRR6TRightMaster_R_Master

BO_ 2631566528 UDSreq_C0_2SRR_FL: 8 COO11
 SG_ SRR6T_L_Diag_Request : 0|64@1+ (1,0) [0|0] ""  SRR6TLeftMaster_L_Master

BO_ 2631663557 UDSreq_FCN_C5_2SRR: 8 COO11
 SG_ SRR6T_FCN_Diag_Request : 0|64@1+ (1,0) [0|0] ""  SRR6TLeftMaster_L_Master,SRR6TRightMaster_R_Master

BO_ 2631663556 UDSreq_FCN_C4_2SRR: 8 COO11
 SG_ SRR6T_FCN_Diag_Request : 0|64@1+ (1,0) [0|0] ""  SRR6TLeftMaster_L_Master,SRR6TRightMaster_R_Master

BO_ 2631663555 UDSreq_FCN_C3_2SRR: 8 COO11
 SG_ SRR6T_FCN_Diag_Request : 0|64@1+ (1,0) [0|0] ""  SRR6TLeftMaster_L_Master,SRR6TRightMaster_R_Master

BO_ 2631663554 UDSreq_FCN_C2_2SRR: 8 COO11
 SG_ SRR6T_FCN_Diag_Request : 0|64@1+ (1,0) [0|0] ""  SRR6TLeftMaster_L_Master,SRR6TRightMaster_R_Master

BO_ 2631663553 UDSreq_FCN_C1_2SRR: 8 COO11
 SG_ SRR6T_FCN_Diag_Request : 0|64@1+ (1,0) [0|0] ""  SRR6TLeftMaster_L_Master,SRR6TRightMaster_R_Master

BO_ 2631663552 UDSreq_FCN_C0_2SRR: 8 COO11
 SG_ SRR6T_FCN_Diag_Request : 0|64@1+ (1,0) [0|0] ""  SRR6TLeftMaster_L_Master,SRR6TRightMaster_R_Master

CM_ BO_ 2566841879 "Error bit : 
TRUE  : 0x00000001
FALSE : 0x00000000";
CM_ SG_ 2399092775 missionMode "The signal indicates if mission mode is active or not.";
BA_DEF_ BO_  "N_Ar" INT 0 0;
BA_DEF_ BO_  "DiagFdOnly" ENUM  "No","Yes";
BA_DEF_ BO_  "DiagConnection" INT 0 0;
BA_DEF_ BO_  "DiagResponse" ENUM  "No","Yes";
BA_DEF_ BO_  "DiagRequest" ENUM  "No","Yes";
BA_DEF_ BO_  "DiagState" ENUM  "No","Yes";
BA_DEF_ BO_  "GenMsgILSupport" ENUM  "No","Yes","vector_leerstring";
BA_DEF_ BO_  "GenMsgSendType" ENUM  "cyclic","reserved","cyclicIfActive","reserved","reserved","reserved","reserved","reserved","noMsgSendType","vector_leerstring";
BA_DEF_ BO_  "GenMsgCycleTime" INT 0 3600000;
BA_DEF_ BO_  "GenMsgStartDelayTime" INT 0 0;
BA_DEF_ BO_  "VFrameFormat" ENUM  "StandardCAN","ExtendedCAN","reserved","reserved","reserved","reserved","reserved","reserved","reserved","reserved","reserved","reserved","reserved","reserved","StandardCAN_FD","ExtendedCAN_FD";
BA_DEF_ BO_  "E2EProfile" STRING ;
BA_DEF_ BO_  "E2EDataLength" INT 0 512;
BA_DEF_ BO_  "E2EDataId" INT 0 0;
BA_DEF_ SG_  "SystemSignalLongSymbol" STRING ;
BA_DEF_DEF_  "N_Ar" 1000;
BA_DEF_DEF_  "DiagFdOnly" "Yes";
BA_DEF_DEF_  "DiagConnection" 0;
BA_DEF_DEF_  "DiagResponse" "No";
BA_DEF_DEF_  "DiagRequest" "No";
BA_DEF_DEF_  "DiagState" "No";
BA_DEF_DEF_  "GenMsgILSupport" "Yes";
BA_DEF_DEF_  "GenMsgSendType" "noMsgSendType";
BA_DEF_DEF_  "GenMsgCycleTime" 1000;
BA_DEF_DEF_  "GenMsgStartDelayTime" 0;
BA_DEF_DEF_  "VFrameFormat" "";
BA_DEF_DEF_  "E2EProfile" "";
BA_DEF_DEF_  "E2EDataLength" 0;
BA_DEF_DEF_  "E2EDataId" 0;
BA_DEF_DEF_  "SystemSignalLongSymbol" "";
BA_ "GenMsgCycleTime" BO_ 2399091085 50;
BA_ "GenMsgSendType" BO_ 2399091085 0;
BA_ "E2EProfile" BO_ 2399091085 "P05";
BA_ "E2EDataId" BO_ 2399091085 9104;
BA_ "E2EDataLength" BO_ 2399091085 512;
BA_ "VFrameFormat" BO_ 2399091085 15;
BA_ "GenMsgCycleTime" BO_ 2399091341 50;
BA_ "GenMsgSendType" BO_ 2399091341 0;
BA_ "E2EProfile" BO_ 2399091341 "P05";
BA_ "E2EDataId" BO_ 2399091341 9120;
BA_ "E2EDataLength" BO_ 2399091341 512;
BA_ "VFrameFormat" BO_ 2399091341 15;
BA_ "GenMsgCycleTime" BO_ 2399089039 50;
BA_ "GenMsgSendType" BO_ 2399089039 0;
BA_ "E2EProfile" BO_ 2399089039 "P05";
BA_ "E2EDataId" BO_ 2399089039 8977;
BA_ "E2EDataLength" BO_ 2399089039 512;
BA_ "VFrameFormat" BO_ 2399089039 15;
BA_ "GenMsgCycleTime" BO_ 2399089295 50;
BA_ "GenMsgSendType" BO_ 2399089295 0;
BA_ "E2EProfile" BO_ 2399089295 "P05";
BA_ "E2EDataId" BO_ 2399089295 8993;
BA_ "E2EDataLength" BO_ 2399089295 512;
BA_ "VFrameFormat" BO_ 2399089295 15;
BA_ "GenMsgCycleTime" BO_ 2399089551 50;
BA_ "GenMsgSendType" BO_ 2399089551 0;
BA_ "E2EProfile" BO_ 2399089551 "P05";
BA_ "E2EDataId" BO_ 2399089551 9009;
BA_ "E2EDataLength" BO_ 2399089551 512;
BA_ "VFrameFormat" BO_ 2399089551 15;
BA_ "GenMsgCycleTime" BO_ 2399089807 50;
BA_ "GenMsgSendType" BO_ 2399089807 0;
BA_ "E2EProfile" BO_ 2399089807 "P05";
BA_ "E2EDataId" BO_ 2399089807 9025;
BA_ "E2EDataLength" BO_ 2399089807 512;
BA_ "VFrameFormat" BO_ 2399089807 15;
BA_ "GenMsgCycleTime" BO_ 2399090063 50;
BA_ "GenMsgSendType" BO_ 2399090063 0;
BA_ "E2EProfile" BO_ 2399090063 "P05";
BA_ "E2EDataId" BO_ 2399090063 9041;
BA_ "E2EDataLength" BO_ 2399090063 512;
BA_ "VFrameFormat" BO_ 2399090063 15;
BA_ "GenMsgCycleTime" BO_ 2399090319 50;
BA_ "GenMsgSendType" BO_ 2399090319 0;
BA_ "E2EProfile" BO_ 2399090319 "P05";
BA_ "E2EDataId" BO_ 2399090319 9057;
BA_ "E2EDataLength" BO_ 2399090319 512;
BA_ "VFrameFormat" BO_ 2399090319 15;
BA_ "GenMsgCycleTime" BO_ 2399090575 50;
BA_ "GenMsgSendType" BO_ 2399090575 0;
BA_ "E2EProfile" BO_ 2399090575 "P05";
BA_ "E2EDataId" BO_ 2399090575 9073;
BA_ "E2EDataLength" BO_ 2399090575 512;
BA_ "VFrameFormat" BO_ 2399090575 15;
BA_ "GenMsgCycleTime" BO_ 2399090831 50;
BA_ "GenMsgSendType" BO_ 2399090831 0;
BA_ "E2EProfile" BO_ 2399090831 "P05";
BA_ "E2EDataId" BO_ 2399090831 9089;
BA_ "E2EDataLength" BO_ 2399090831 512;
BA_ "VFrameFormat" BO_ 2399090831 15;
BA_ "GenMsgCycleTime" BO_ 2399091087 50;
BA_ "GenMsgSendType" BO_ 2399091087 0;
BA_ "E2EProfile" BO_ 2399091087 "P05";
BA_ "E2EDataId" BO_ 2399091087 9105;
BA_ "E2EDataLength" BO_ 2399091087 512;
BA_ "VFrameFormat" BO_ 2399091087 15;
BA_ "GenMsgCycleTime" BO_ 2399091343 50;
BA_ "GenMsgSendType" BO_ 2399091343 0;
BA_ "E2EProfile" BO_ 2399091343 "P05";
BA_ "E2EDataId" BO_ 2399091343 9121;
BA_ "E2EDataLength" BO_ 2399091343 512;
BA_ "VFrameFormat" BO_ 2399091343 15;
BA_ "GenMsgStartDelayTime" BO_ 2566841879 30;
BA_ "GenMsgSendType" BO_ 2566841879 0;
BA_ "VFrameFormat" BO_ 2566841879 1;
BA_ "GenMsgSendType" BO_ 2399092775 0;
BA_ "GenMsgCycleTime" BO_ 2399092775 20;
BA_ "E2EProfile" BO_ 2399092775 "P05";
BA_ "E2EDataId" BO_ 2399092775 9216;
BA_ "E2EDataLength" BO_ 2399092775 128;
BA_ "VFrameFormat" BO_ 2399092775 15;
BA_ "DiagConnection" BO_ 2631663611 25;
BA_ "VFrameFormat" BO_ 2631663611 1;
BA_ "DiagState" BO_ 2631663611 1;
BA_ "GenMsgCycleTime" BO_ 2631663611 0;
BA_ "DiagConnection" BO_ 2631663609 29;
BA_ "VFrameFormat" BO_ 2631663609 1;
BA_ "DiagState" BO_ 2631663609 1;
BA_ "GenMsgCycleTime" BO_ 2631663609 0;
BA_ "DiagConnection" BO_ 2631663601 33;
BA_ "VFrameFormat" BO_ 2631663601 1;
BA_ "DiagState" BO_ 2631663601 1;
BA_ "GenMsgCycleTime" BO_ 2631663601 0;
BA_ "DiagConnection" BO_ 2631663434 37;
BA_ "VFrameFormat" BO_ 2631663434 1;
BA_ "DiagState" BO_ 2631663434 1;
BA_ "GenMsgCycleTime" BO_ 2631663434 0;
BA_ "DiagConnection" BO_ 2631663403 41;
BA_ "VFrameFormat" BO_ 2631663403 1;
BA_ "DiagState" BO_ 2631663403 1;
BA_ "GenMsgCycleTime" BO_ 2631663403 0;
BA_ "DiagConnection" BO_ 2631663383 45;
BA_ "VFrameFormat" BO_ 2631663383 1;
BA_ "DiagState" BO_ 2631663383 1;
BA_ "GenMsgCycleTime" BO_ 2631663383 0;
BA_ "DiagConnection" BO_ 2564554747 1;
BA_ "VFrameFormat" BO_ 2564554747 1;
BA_ "DiagState" BO_ 2564554747 1;
BA_ "GenMsgCycleTime" BO_ 2564554747 0;
BA_ "DiagConnection" BO_ 2564554746 5;
BA_ "VFrameFormat" BO_ 2564554746 1;
BA_ "DiagState" BO_ 2564554746 1;
BA_ "GenMsgCycleTime" BO_ 2564554746 0;
BA_ "DiagConnection" BO_ 2564554745 9;
BA_ "VFrameFormat" BO_ 2564554745 1;
BA_ "DiagState" BO_ 2564554745 1;
BA_ "GenMsgCycleTime" BO_ 2564554745 0;
BA_ "DiagConnection" BO_ 2564554570 13;
BA_ "VFrameFormat" BO_ 2564554570 1;
BA_ "DiagState" BO_ 2564554570 1;
BA_ "GenMsgCycleTime" BO_ 2564554570 0;
BA_ "DiagConnection" BO_ 2564554539 17;
BA_ "VFrameFormat" BO_ 2564554539 1;
BA_ "DiagState" BO_ 2564554539 1;
BA_ "GenMsgCycleTime" BO_ 2564554539 0;
BA_ "DiagConnection" BO_ 2564554519 21;
BA_ "VFrameFormat" BO_ 2564554519 1;
BA_ "DiagState" BO_ 2564554519 1;
BA_ "GenMsgCycleTime" BO_ 2564554519 0;
BA_ "DiagConnection" BO_ 2564488079 1;
BA_ "VFrameFormat" BO_ 2564488079 1;
BA_ "DiagResponse" BO_ 2564488079 1;
BA_ "GenMsgCycleTime" BO_ 2564488079 0;
BA_ "DiagConnection" BO_ 2564488077 2;
BA_ "VFrameFormat" BO_ 2564488077 1;
BA_ "DiagResponse" BO_ 2564488077 1;
BA_ "GenMsgCycleTime" BO_ 2564488077 0;
BA_ "DiagConnection" BO_ 2564488078 3;
BA_ "VFrameFormat" BO_ 2564488078 1;
BA_ "DiagResponse" BO_ 2564488078 1;
BA_ "GenMsgCycleTime" BO_ 2564488078 0;
BA_ "DiagConnection" BO_ 2564488076 4;
BA_ "VFrameFormat" BO_ 2564488076 1;
BA_ "DiagResponse" BO_ 2564488076 1;
BA_ "GenMsgCycleTime" BO_ 2564488076 0;
BA_ "DiagConnection" BO_ 2564487823 5;
BA_ "VFrameFormat" BO_ 2564487823 1;
BA_ "DiagResponse" BO_ 2564487823 1;
BA_ "GenMsgCycleTime" BO_ 2564487823 0;
BA_ "DiagConnection" BO_ 2564487821 6;
BA_ "VFrameFormat" BO_ 2564487821 1;
BA_ "DiagResponse" BO_ 2564487821 1;
BA_ "GenMsgCycleTime" BO_ 2564487821 0;
BA_ "DiagConnection" BO_ 2564487822 7;
BA_ "VFrameFormat" BO_ 2564487822 1;
BA_ "DiagResponse" BO_ 2564487822 1;
BA_ "GenMsgCycleTime" BO_ 2564487822 0;
BA_ "DiagConnection" BO_ 2564487820 8;
BA_ "VFrameFormat" BO_ 2564487820 1;
BA_ "DiagResponse" BO_ 2564487820 1;
BA_ "GenMsgCycleTime" BO_ 2564487820 0;
BA_ "DiagConnection" BO_ 2564487567 9;
BA_ "VFrameFormat" BO_ 2564487567 1;
BA_ "DiagResponse" BO_ 2564487567 1;
BA_ "GenMsgCycleTime" BO_ 2564487567 0;
BA_ "DiagConnection" BO_ 2564487565 10;
BA_ "VFrameFormat" BO_ 2564487565 1;
BA_ "DiagResponse" BO_ 2564487565 1;
BA_ "GenMsgCycleTime" BO_ 2564487565 0;
BA_ "DiagConnection" BO_ 2564487566 64;
BA_ "VFrameFormat" BO_ 2564487566 1;
BA_ "DiagResponse" BO_ 2564487566 1;
BA_ "GenMsgCycleTime" BO_ 2564487566 0;
BA_ "DiagConnection" BO_ 2564487564 12;
BA_ "VFrameFormat" BO_ 2564487564 1;
BA_ "DiagResponse" BO_ 2564487564 1;
BA_ "GenMsgCycleTime" BO_ 2564487564 0;
BA_ "DiagConnection" BO_ 2564442767 13;
BA_ "VFrameFormat" BO_ 2564442767 1;
BA_ "DiagResponse" BO_ 2564442767 1;
BA_ "GenMsgCycleTime" BO_ 2564442767 0;
BA_ "DiagConnection" BO_ 2564442765 14;
BA_ "VFrameFormat" BO_ 2564442765 1;
BA_ "DiagResponse" BO_ 2564442765 1;
BA_ "GenMsgCycleTime" BO_ 2564442765 0;
BA_ "DiagConnection" BO_ 2564442766 15;
BA_ "VFrameFormat" BO_ 2564442766 1;
BA_ "DiagResponse" BO_ 2564442766 1;
BA_ "GenMsgCycleTime" BO_ 2564442766 0;
BA_ "DiagConnection" BO_ 2564442764 16;
BA_ "VFrameFormat" BO_ 2564442764 1;
BA_ "DiagResponse" BO_ 2564442764 1;
BA_ "GenMsgCycleTime" BO_ 2564442764 0;
BA_ "DiagConnection" BO_ 2564434831 17;
BA_ "VFrameFormat" BO_ 2564434831 1;
BA_ "DiagResponse" BO_ 2564434831 1;
BA_ "GenMsgCycleTime" BO_ 2564434831 0;
BA_ "DiagConnection" BO_ 2564434829 18;
BA_ "VFrameFormat" BO_ 2564434829 1;
BA_ "DiagResponse" BO_ 2564434829 1;
BA_ "GenMsgCycleTime" BO_ 2564434829 0;
BA_ "DiagConnection" BO_ 2564434830 19;
BA_ "VFrameFormat" BO_ 2564434830 1;
BA_ "DiagResponse" BO_ 2564434830 1;
BA_ "GenMsgCycleTime" BO_ 2564434830 0;
BA_ "DiagConnection" BO_ 2564434828 20;
BA_ "VFrameFormat" BO_ 2564434828 1;
BA_ "DiagResponse" BO_ 2564434828 1;
BA_ "GenMsgCycleTime" BO_ 2564434828 0;
BA_ "DiagConnection" BO_ 2564429711 21;
BA_ "VFrameFormat" BO_ 2564429711 1;
BA_ "DiagResponse" BO_ 2564429711 1;
BA_ "GenMsgCycleTime" BO_ 2564429711 0;
BA_ "DiagConnection" BO_ 2564429709 22;
BA_ "VFrameFormat" BO_ 2564429709 1;
BA_ "DiagResponse" BO_ 2564429709 1;
BA_ "GenMsgCycleTime" BO_ 2564429709 0;
BA_ "DiagConnection" BO_ 2564429710 23;
BA_ "VFrameFormat" BO_ 2564429710 1;
BA_ "DiagResponse" BO_ 2564429710 1;
BA_ "GenMsgCycleTime" BO_ 2564429710 0;
BA_ "DiagConnection" BO_ 2564429708 24;
BA_ "VFrameFormat" BO_ 2564429708 1;
BA_ "DiagResponse" BO_ 2564429708 1;
BA_ "GenMsgCycleTime" BO_ 2564429708 0;
BA_ "DiagConnection" BO_ 2564460539 1;
BA_ "VFrameFormat" BO_ 2564460539 1;
BA_ "DiagRequest" BO_ 2564460539 1;
BA_ "GenMsgCycleTime" BO_ 2564460539 0;
BA_ "DiagConnection" BO_ 2564460027 2;
BA_ "VFrameFormat" BO_ 2564460027 1;
BA_ "DiagRequest" BO_ 2564460027 1;
BA_ "GenMsgCycleTime" BO_ 2564460027 0;
BA_ "DiagConnection" BO_ 2564460283 3;
BA_ "VFrameFormat" BO_ 2564460283 1;
BA_ "DiagRequest" BO_ 2564460283 1;
BA_ "GenMsgCycleTime" BO_ 2564460283 0;
BA_ "DiagConnection" BO_ 2564459771 4;
BA_ "VFrameFormat" BO_ 2564459771 1;
BA_ "DiagRequest" BO_ 2564459771 1;
BA_ "GenMsgCycleTime" BO_ 2564459771 0;
BA_ "DiagConnection" BO_ 2564460538 5;
BA_ "VFrameFormat" BO_ 2564460538 1;
BA_ "DiagRequest" BO_ 2564460538 1;
BA_ "GenMsgCycleTime" BO_ 2564460538 0;
BA_ "DiagConnection" BO_ 2564460026 6;
BA_ "VFrameFormat" BO_ 2564460026 1;
BA_ "DiagRequest" BO_ 2564460026 1;
BA_ "GenMsgCycleTime" BO_ 2564460026 0;
BA_ "DiagConnection" BO_ 2564460282 7;
BA_ "VFrameFormat" BO_ 2564460282 1;
BA_ "DiagRequest" BO_ 2564460282 1;
BA_ "GenMsgCycleTime" BO_ 2564460282 0;
BA_ "DiagConnection" BO_ 2564459770 8;
BA_ "VFrameFormat" BO_ 2564459770 1;
BA_ "DiagRequest" BO_ 2564459770 1;
BA_ "GenMsgCycleTime" BO_ 2564459770 0;
BA_ "DiagConnection" BO_ 2564460537 9;
BA_ "VFrameFormat" BO_ 2564460537 1;
BA_ "DiagRequest" BO_ 2564460537 1;
BA_ "GenMsgCycleTime" BO_ 2564460537 0;
BA_ "DiagConnection" BO_ 2564460025 10;
BA_ "VFrameFormat" BO_ 2564460025 1;
BA_ "DiagRequest" BO_ 2564460025 1;
BA_ "GenMsgCycleTime" BO_ 2564460025 0;
BA_ "DiagConnection" BO_ 2564460281 11;
BA_ "VFrameFormat" BO_ 2564460281 1;
BA_ "DiagRequest" BO_ 2564460281 1;
BA_ "GenMsgCycleTime" BO_ 2564460281 0;
BA_ "DiagConnection" BO_ 2564459769 12;
BA_ "VFrameFormat" BO_ 2564459769 1;
BA_ "DiagRequest" BO_ 2564459769 1;
BA_ "GenMsgCycleTime" BO_ 2564459769 0;
BA_ "DiagConnection" BO_ 2564460362 13;
BA_ "VFrameFormat" BO_ 2564460362 1;
BA_ "DiagRequest" BO_ 2564460362 1;
BA_ "GenMsgCycleTime" BO_ 2564460362 0;
BA_ "DiagConnection" BO_ 2564459850 14;
BA_ "VFrameFormat" BO_ 2564459850 1;
BA_ "DiagRequest" BO_ 2564459850 1;
BA_ "GenMsgCycleTime" BO_ 2564459850 0;
BA_ "DiagConnection" BO_ 2564460106 15;
BA_ "VFrameFormat" BO_ 2564460106 1;
BA_ "DiagRequest" BO_ 2564460106 1;
BA_ "GenMsgCycleTime" BO_ 2564460106 0;
BA_ "DiagConnection" BO_ 2564459594 16;
BA_ "VFrameFormat" BO_ 2564459594 1;
BA_ "DiagRequest" BO_ 2564459594 1;
BA_ "GenMsgCycleTime" BO_ 2564459594 0;
BA_ "DiagConnection" BO_ 2564460331 17;
BA_ "VFrameFormat" BO_ 2564460331 1;
BA_ "DiagRequest" BO_ 2564460331 1;
BA_ "GenMsgCycleTime" BO_ 2564460331 0;
BA_ "DiagConnection" BO_ 2564459819 18;
BA_ "VFrameFormat" BO_ 2564459819 1;
BA_ "DiagRequest" BO_ 2564459819 1;
BA_ "GenMsgCycleTime" BO_ 2564459819 0;
BA_ "DiagConnection" BO_ 2564460075 19;
BA_ "VFrameFormat" BO_ 2564460075 1;
BA_ "DiagRequest" BO_ 2564460075 1;
BA_ "GenMsgCycleTime" BO_ 2564460075 0;
BA_ "DiagConnection" BO_ 2564459563 20;
BA_ "VFrameFormat" BO_ 2564459563 1;
BA_ "DiagRequest" BO_ 2564459563 1;
BA_ "GenMsgCycleTime" BO_ 2564459563 0;
BA_ "DiagConnection" BO_ 2564460311 21;
BA_ "VFrameFormat" BO_ 2564460311 1;
BA_ "DiagRequest" BO_ 2564460311 1;
BA_ "GenMsgCycleTime" BO_ 2564460311 0;
BA_ "DiagConnection" BO_ 2564459799 22;
BA_ "VFrameFormat" BO_ 2564459799 1;
BA_ "DiagRequest" BO_ 2564459799 1;
BA_ "GenMsgCycleTime" BO_ 2564459799 0;
BA_ "DiagConnection" BO_ 2564460055 23;
BA_ "VFrameFormat" BO_ 2564460055 1;
BA_ "DiagRequest" BO_ 2564460055 1;
BA_ "GenMsgCycleTime" BO_ 2564460055 0;
BA_ "DiagConnection" BO_ 2564459543 24;
BA_ "VFrameFormat" BO_ 2564459543 1;
BA_ "DiagRequest" BO_ 2564459543 1;
BA_ "GenMsgCycleTime" BO_ 2564459543 0;
BA_ "DiagConnection" BO_ 2631596931 25;
BA_ "VFrameFormat" BO_ 2631596931 1;
BA_ "DiagResponse" BO_ 2631596931 1;
BA_ "GenMsgCycleTime" BO_ 2631596931 0;
BA_ "DiagConnection" BO_ 2631596933 26;
BA_ "VFrameFormat" BO_ 2631596933 1;
BA_ "DiagResponse" BO_ 2631596933 1;
BA_ "GenMsgCycleTime" BO_ 2631596933 0;
BA_ "DiagConnection" BO_ 2631596930 27;
BA_ "VFrameFormat" BO_ 2631596930 1;
BA_ "DiagResponse" BO_ 2631596930 1;
BA_ "GenMsgCycleTime" BO_ 2631596930 0;
BA_ "DiagConnection" BO_ 2631596932 28;
BA_ "VFrameFormat" BO_ 2631596932 1;
BA_ "DiagResponse" BO_ 2631596932 1;
BA_ "GenMsgCycleTime" BO_ 2631596932 0;
BA_ "DiagConnection" BO_ 2631566331 25;
BA_ "VFrameFormat" BO_ 2631566331 1;
BA_ "DiagRequest" BO_ 2631566331 1;
BA_ "GenMsgCycleTime" BO_ 2631566331 0;
BA_ "DiagConnection" BO_ 2631566843 26;
BA_ "VFrameFormat" BO_ 2631566843 1;
BA_ "DiagRequest" BO_ 2631566843 1;
BA_ "GenMsgCycleTime" BO_ 2631566843 0;
BA_ "DiagConnection" BO_ 2631566075 27;
BA_ "VFrameFormat" BO_ 2631566075 1;
BA_ "DiagRequest" BO_ 2631566075 1;
BA_ "GenMsgCycleTime" BO_ 2631566075 0;
BA_ "DiagConnection" BO_ 2631566587 28;
BA_ "VFrameFormat" BO_ 2631566587 1;
BA_ "DiagRequest" BO_ 2631566587 1;
BA_ "GenMsgCycleTime" BO_ 2631566587 0;
BA_ "DiagConnection" BO_ 2631596419 29;
BA_ "VFrameFormat" BO_ 2631596419 1;
BA_ "DiagResponse" BO_ 2631596419 1;
BA_ "GenMsgCycleTime" BO_ 2631596419 0;
BA_ "DiagConnection" BO_ 2631596421 30;
BA_ "VFrameFormat" BO_ 2631596421 1;
BA_ "DiagResponse" BO_ 2631596421 1;
BA_ "GenMsgCycleTime" BO_ 2631596421 0;
BA_ "DiagConnection" BO_ 2631596418 31;
BA_ "VFrameFormat" BO_ 2631596418 1;
BA_ "DiagResponse" BO_ 2631596418 1;
BA_ "GenMsgCycleTime" BO_ 2631596418 0;
BA_ "DiagConnection" BO_ 2631596420 32;
BA_ "VFrameFormat" BO_ 2631596420 1;
BA_ "DiagResponse" BO_ 2631596420 1;
BA_ "GenMsgCycleTime" BO_ 2631596420 0;
BA_ "DiagConnection" BO_ 2631566329 29;
BA_ "VFrameFormat" BO_ 2631566329 1;
BA_ "DiagRequest" BO_ 2631566329 1;
BA_ "GenMsgCycleTime" BO_ 2631566329 0;
BA_ "DiagConnection" BO_ 2631566841 30;
BA_ "VFrameFormat" BO_ 2631566841 1;
BA_ "DiagRequest" BO_ 2631566841 1;
BA_ "GenMsgCycleTime" BO_ 2631566841 0;
BA_ "DiagConnection" BO_ 2631566073 31;
BA_ "VFrameFormat" BO_ 2631566073 1;
BA_ "DiagRequest" BO_ 2631566073 1;
BA_ "GenMsgCycleTime" BO_ 2631566073 0;
BA_ "DiagConnection" BO_ 2631566585 32;
BA_ "VFrameFormat" BO_ 2631566585 1;
BA_ "DiagRequest" BO_ 2631566585 1;
BA_ "GenMsgCycleTime" BO_ 2631566585 0;
BA_ "DiagConnection" BO_ 2631594371 33;
BA_ "VFrameFormat" BO_ 2631594371 1;
BA_ "DiagResponse" BO_ 2631594371 1;
BA_ "GenMsgCycleTime" BO_ 2631594371 0;
BA_ "DiagConnection" BO_ 2631594373 34;
BA_ "VFrameFormat" BO_ 2631594373 1;
BA_ "DiagResponse" BO_ 2631594373 1;
BA_ "GenMsgCycleTime" BO_ 2631594373 0;
BA_ "DiagConnection" BO_ 2631594370 35;
BA_ "VFrameFormat" BO_ 2631594370 1;
BA_ "DiagResponse" BO_ 2631594370 1;
BA_ "GenMsgCycleTime" BO_ 2631594370 0;
BA_ "DiagConnection" BO_ 2631594372 36;
BA_ "VFrameFormat" BO_ 2631594372 1;
BA_ "DiagResponse" BO_ 2631594372 1;
BA_ "GenMsgCycleTime" BO_ 2631594372 0;
BA_ "DiagConnection" BO_ 2631566321 33;
BA_ "VFrameFormat" BO_ 2631566321 1;
BA_ "DiagRequest" BO_ 2631566321 1;
BA_ "GenMsgCycleTime" BO_ 2631566321 0;
BA_ "DiagConnection" BO_ 2631566833 34;
BA_ "VFrameFormat" BO_ 2631566833 1;
BA_ "DiagRequest" BO_ 2631566833 1;
BA_ "GenMsgCycleTime" BO_ 2631566833 0;
BA_ "DiagConnection" BO_ 2631566065 35;
BA_ "VFrameFormat" BO_ 2631566065 1;
BA_ "DiagRequest" BO_ 2631566065 1;
BA_ "GenMsgCycleTime" BO_ 2631566065 0;
BA_ "DiagConnection" BO_ 2631566577 36;
BA_ "VFrameFormat" BO_ 2631566577 1;
BA_ "DiagRequest" BO_ 2631566577 1;
BA_ "GenMsgCycleTime" BO_ 2631566577 0;
BA_ "DiagConnection" BO_ 2631566154 37;
BA_ "VFrameFormat" BO_ 2631566154 1;
BA_ "DiagRequest" BO_ 2631566154 1;
BA_ "GenMsgCycleTime" BO_ 2631566154 0;
BA_ "DiagConnection" BO_ 2631566666 38;
BA_ "VFrameFormat" BO_ 2631566666 1;
BA_ "DiagRequest" BO_ 2631566666 1;
BA_ "GenMsgCycleTime" BO_ 2631566666 0;
BA_ "DiagConnection" BO_ 2631565898 39;
BA_ "VFrameFormat" BO_ 2631565898 1;
BA_ "DiagRequest" BO_ 2631565898 1;
BA_ "GenMsgCycleTime" BO_ 2631565898 0;
BA_ "DiagConnection" BO_ 2631566410 40;
BA_ "VFrameFormat" BO_ 2631566410 1;
BA_ "DiagRequest" BO_ 2631566410 1;
BA_ "GenMsgCycleTime" BO_ 2631566410 0;
BA_ "DiagConnection" BO_ 2631566123 41;
BA_ "VFrameFormat" BO_ 2631566123 1;
BA_ "DiagRequest" BO_ 2631566123 1;
BA_ "GenMsgCycleTime" BO_ 2631566123 0;
BA_ "DiagConnection" BO_ 2631566635 42;
BA_ "VFrameFormat" BO_ 2631566635 1;
BA_ "DiagRequest" BO_ 2631566635 1;
BA_ "GenMsgCycleTime" BO_ 2631566635 0;
BA_ "DiagConnection" BO_ 2631565867 43;
BA_ "VFrameFormat" BO_ 2631565867 1;
BA_ "DiagRequest" BO_ 2631565867 1;
BA_ "GenMsgCycleTime" BO_ 2631565867 0;
BA_ "DiagConnection" BO_ 2631566379 44;
BA_ "VFrameFormat" BO_ 2631566379 1;
BA_ "DiagRequest" BO_ 2631566379 1;
BA_ "GenMsgCycleTime" BO_ 2631566379 0;
BA_ "DiagConnection" BO_ 2631551619 37;
BA_ "VFrameFormat" BO_ 2631551619 1;
BA_ "DiagResponse" BO_ 2631551619 1;
BA_ "GenMsgCycleTime" BO_ 2631551619 0;
BA_ "DiagConnection" BO_ 2631551621 38;
BA_ "VFrameFormat" BO_ 2631551621 1;
BA_ "DiagResponse" BO_ 2631551621 1;
BA_ "GenMsgCycleTime" BO_ 2631551621 0;
BA_ "DiagConnection" BO_ 2631551618 39;
BA_ "VFrameFormat" BO_ 2631551618 1;
BA_ "DiagResponse" BO_ 2631551618 1;
BA_ "GenMsgCycleTime" BO_ 2631551618 0;
BA_ "DiagConnection" BO_ 2631551620 40;
BA_ "VFrameFormat" BO_ 2631551620 1;
BA_ "DiagResponse" BO_ 2631551620 1;
BA_ "GenMsgCycleTime" BO_ 2631551620 0;
BA_ "DiagConnection" BO_ 2631543683 41;
BA_ "VFrameFormat" BO_ 2631543683 1;
BA_ "DiagResponse" BO_ 2631543683 1;
BA_ "GenMsgCycleTime" BO_ 2631543683 0;
BA_ "DiagConnection" BO_ 2631543685 42;
BA_ "VFrameFormat" BO_ 2631543685 1;
BA_ "DiagResponse" BO_ 2631543685 1;
BA_ "GenMsgCycleTime" BO_ 2631543685 0;
BA_ "DiagConnection" BO_ 2631543682 43;
BA_ "VFrameFormat" BO_ 2631543682 1;
BA_ "DiagResponse" BO_ 2631543682 1;
BA_ "GenMsgCycleTime" BO_ 2631543682 0;
BA_ "DiagConnection" BO_ 2631543684 44;
BA_ "VFrameFormat" BO_ 2631543684 1;
BA_ "DiagResponse" BO_ 2631543684 1;
BA_ "GenMsgCycleTime" BO_ 2631543684 0;
BA_ "DiagConnection" BO_ 2631538563 45;
BA_ "VFrameFormat" BO_ 2631538563 1;
BA_ "DiagResponse" BO_ 2631538563 1;
BA_ "GenMsgCycleTime" BO_ 2631538563 0;
BA_ "DiagConnection" BO_ 2631538565 46;
BA_ "VFrameFormat" BO_ 2631538565 1;
BA_ "DiagResponse" BO_ 2631538565 1;
BA_ "GenMsgCycleTime" BO_ 2631538565 0;
BA_ "DiagConnection" BO_ 2631538562 47;
BA_ "VFrameFormat" BO_ 2631538562 1;
BA_ "DiagResponse" BO_ 2631538562 1;
BA_ "GenMsgCycleTime" BO_ 2631538562 0;
BA_ "DiagConnection" BO_ 2631538564 48;
BA_ "VFrameFormat" BO_ 2631538564 1;
BA_ "DiagResponse" BO_ 2631538564 1;
BA_ "GenMsgCycleTime" BO_ 2631538564 0;
BA_ "DiagConnection" BO_ 2631566103 45;
BA_ "VFrameFormat" BO_ 2631566103 1;
BA_ "DiagRequest" BO_ 2631566103 1;
BA_ "GenMsgCycleTime" BO_ 2631566103 0;
BA_ "DiagConnection" BO_ 2631566615 46;
BA_ "VFrameFormat" BO_ 2631566615 1;
BA_ "DiagRequest" BO_ 2631566615 1;
BA_ "GenMsgCycleTime" BO_ 2631566615 0;
BA_ "DiagConnection" BO_ 2631565847 47;
BA_ "VFrameFormat" BO_ 2631565847 1;
BA_ "DiagRequest" BO_ 2631565847 1;
BA_ "GenMsgCycleTime" BO_ 2631565847 0;
BA_ "DiagConnection" BO_ 2631566359 48;
BA_ "VFrameFormat" BO_ 2631566359 1;
BA_ "DiagRequest" BO_ 2631566359 1;
BA_ "GenMsgCycleTime" BO_ 2631566359 0;
BA_ "DiagResponse" BO_ 2631583107 1;
BA_ "DiagConnection" BO_ 2631583107 81;
BA_ "VFrameFormat" BO_ 2631583107 1;
BA_ "GenMsgCycleTime" BO_ 2631583107 0;
BA_ "DiagResponse" BO_ 2631582851 1;
BA_ "DiagConnection" BO_ 2631582851 77;
BA_ "VFrameFormat" BO_ 2631582851 1;
BA_ "GenMsgCycleTime" BO_ 2631582851 0;
BA_ "DiagResponse" BO_ 2631582595 1;
BA_ "DiagConnection" BO_ 2631582595 73;
BA_ "VFrameFormat" BO_ 2631582595 1;
BA_ "GenMsgCycleTime" BO_ 2631582595 0;
BA_ "DiagResponse" BO_ 2631582339 1;
BA_ "DiagConnection" BO_ 2631582339 69;
BA_ "VFrameFormat" BO_ 2631582339 1;
BA_ "GenMsgCycleTime" BO_ 2631582339 0;
BA_ "DiagResponse" BO_ 2631583109 1;
BA_ "DiagConnection" BO_ 2631583109 82;
BA_ "VFrameFormat" BO_ 2631583109 1;
BA_ "GenMsgCycleTime" BO_ 2631583109 0;
BA_ "DiagResponse" BO_ 2631582853 1;
BA_ "DiagConnection" BO_ 2631582853 78;
BA_ "VFrameFormat" BO_ 2631582853 1;
BA_ "GenMsgCycleTime" BO_ 2631582853 0;
BA_ "DiagResponse" BO_ 2631582597 1;
BA_ "DiagConnection" BO_ 2631582597 74;
BA_ "VFrameFormat" BO_ 2631582597 1;
BA_ "GenMsgCycleTime" BO_ 2631582597 0;
BA_ "DiagResponse" BO_ 2631582341 1;
BA_ "DiagConnection" BO_ 2631582341 70;
BA_ "VFrameFormat" BO_ 2631582341 1;
BA_ "GenMsgCycleTime" BO_ 2631582341 0;
BA_ "DiagResponse" BO_ 2631583106 1;
BA_ "DiagConnection" BO_ 2631583106 83;
BA_ "VFrameFormat" BO_ 2631583106 1;
BA_ "GenMsgCycleTime" BO_ 2631583106 0;
BA_ "DiagResponse" BO_ 2631582850 1;
BA_ "DiagConnection" BO_ 2631582850 79;
BA_ "VFrameFormat" BO_ 2631582850 1;
BA_ "GenMsgCycleTime" BO_ 2631582850 0;
BA_ "DiagResponse" BO_ 2631582594 1;
BA_ "DiagConnection" BO_ 2631582594 75;
BA_ "VFrameFormat" BO_ 2631582594 1;
BA_ "GenMsgCycleTime" BO_ 2631582594 0;
BA_ "DiagResponse" BO_ 2631582338 1;
BA_ "DiagConnection" BO_ 2631582338 71;
BA_ "VFrameFormat" BO_ 2631582338 1;
BA_ "GenMsgCycleTime" BO_ 2631582338 0;
BA_ "DiagResponse" BO_ 2631583108 1;
BA_ "DiagConnection" BO_ 2631583108 84;
BA_ "VFrameFormat" BO_ 2631583108 1;
BA_ "GenMsgCycleTime" BO_ 2631583108 0;
BA_ "DiagResponse" BO_ 2631582852 1;
BA_ "DiagConnection" BO_ 2631582852 80;
BA_ "VFrameFormat" BO_ 2631582852 1;
BA_ "GenMsgCycleTime" BO_ 2631582852 0;
BA_ "DiagResponse" BO_ 2631582596 1;
BA_ "DiagConnection" BO_ 2631582596 76;
BA_ "VFrameFormat" BO_ 2631582596 1;
BA_ "GenMsgCycleTime" BO_ 2631582596 0;
BA_ "DiagResponse" BO_ 2631582340 1;
BA_ "DiagConnection" BO_ 2631582340 72;
BA_ "VFrameFormat" BO_ 2631582340 1;
BA_ "GenMsgCycleTime" BO_ 2631582340 0;
BA_ "VFrameFormat" BO_ 2631582083 1;
BA_ "DiagConnection" BO_ 2631582083 65;
BA_ "DiagResponse" BO_ 2631582083 1;
BA_ "GenMsgCycleTime" BO_ 2631582083 0;
BA_ "DiagResponse" BO_ 2631581827 1;
BA_ "DiagConnection" BO_ 2631581827 88;
BA_ "VFrameFormat" BO_ 2631581827 1;
BA_ "GenMsgCycleTime" BO_ 2631581827 0;
BA_ "DiagResponse" BO_ 2631581829 1;
BA_ "DiagConnection" BO_ 2631581829 87;
BA_ "VFrameFormat" BO_ 2631581829 1;
BA_ "GenMsgCycleTime" BO_ 2631581829 0;
BA_ "DiagResponse" BO_ 2631581826 1;
BA_ "DiagConnection" BO_ 2631581826 86;
BA_ "VFrameFormat" BO_ 2631581826 1;
BA_ "GenMsgCycleTime" BO_ 2631581826 0;
BA_ "DiagResponse" BO_ 2631581828 1;
BA_ "DiagConnection" BO_ 2631581828 85;
BA_ "VFrameFormat" BO_ 2631581828 1;
BA_ "GenMsgCycleTime" BO_ 2631581828 0;
BA_ "VFrameFormat" BO_ 2631582085 1;
BA_ "DiagConnection" BO_ 2631582085 66;
BA_ "DiagResponse" BO_ 2631582085 1;
BA_ "GenMsgCycleTime" BO_ 2631582085 0;
BA_ "VFrameFormat" BO_ 2631582082 1;
BA_ "DiagConnection" BO_ 2631582082 67;
BA_ "DiagResponse" BO_ 2631582082 1;
BA_ "GenMsgCycleTime" BO_ 2631582082 0;
BA_ "VFrameFormat" BO_ 2631582084 1;
BA_ "DiagConnection" BO_ 2631582084 68;
BA_ "DiagResponse" BO_ 2631582084 1;
BA_ "GenMsgCycleTime" BO_ 2631582084 0;
BA_ "VFrameFormat" BO_ 2631566277 1;
BA_ "DiagConnection" BO_ 2631566277 81;
BA_ "DiagRequest" BO_ 2631566277 1;
BA_ "GenMsgCycleTime" BO_ 2631566277 0;
BA_ "VFrameFormat" BO_ 2631566276 1;
BA_ "DiagConnection" BO_ 2631566276 77;
BA_ "DiagRequest" BO_ 2631566276 1;
BA_ "GenMsgCycleTime" BO_ 2631566276 0;
BA_ "VFrameFormat" BO_ 2631566275 1;
BA_ "DiagConnection" BO_ 2631566275 73;
BA_ "DiagRequest" BO_ 2631566275 1;
BA_ "GenMsgCycleTime" BO_ 2631566275 0;
BA_ "VFrameFormat" BO_ 2631566274 1;
BA_ "DiagConnection" BO_ 2631566274 69;
BA_ "DiagRequest" BO_ 2631566274 1;
BA_ "GenMsgCycleTime" BO_ 2631566274 0;
BA_ "VFrameFormat" BO_ 2631566789 1;
BA_ "DiagConnection" BO_ 2631566789 82;
BA_ "DiagRequest" BO_ 2631566789 1;
BA_ "GenMsgCycleTime" BO_ 2631566789 0;
BA_ "VFrameFormat" BO_ 2631566788 1;
BA_ "DiagConnection" BO_ 2631566788 78;
BA_ "DiagRequest" BO_ 2631566788 1;
BA_ "GenMsgCycleTime" BO_ 2631566788 0;
BA_ "VFrameFormat" BO_ 2631566787 1;
BA_ "DiagConnection" BO_ 2631566787 74;
BA_ "DiagRequest" BO_ 2631566787 1;
BA_ "GenMsgCycleTime" BO_ 2631566787 0;
BA_ "VFrameFormat" BO_ 2631566786 1;
BA_ "DiagConnection" BO_ 2631566786 70;
BA_ "DiagRequest" BO_ 2631566786 1;
BA_ "GenMsgCycleTime" BO_ 2631566786 0;
BA_ "VFrameFormat" BO_ 2631566021 1;
BA_ "DiagConnection" BO_ 2631566021 83;
BA_ "DiagRequest" BO_ 2631566021 1;
BA_ "GenMsgCycleTime" BO_ 2631566021 0;
BA_ "VFrameFormat" BO_ 2631566020 1;
BA_ "DiagConnection" BO_ 2631566020 79;
BA_ "DiagRequest" BO_ 2631566020 1;
BA_ "GenMsgCycleTime" BO_ 2631566020 0;
BA_ "VFrameFormat" BO_ 2631566019 1;
BA_ "DiagConnection" BO_ 2631566019 75;
BA_ "DiagRequest" BO_ 2631566019 1;
BA_ "GenMsgCycleTime" BO_ 2631566019 0;
BA_ "VFrameFormat" BO_ 2631566018 1;
BA_ "DiagConnection" BO_ 2631566018 71;
BA_ "DiagRequest" BO_ 2631566018 1;
BA_ "GenMsgCycleTime" BO_ 2631566018 0;
BA_ "VFrameFormat" BO_ 2631566533 1;
BA_ "DiagConnection" BO_ 2631566533 84;
BA_ "DiagRequest" BO_ 2631566533 1;
BA_ "GenMsgCycleTime" BO_ 2631566533 0;
BA_ "VFrameFormat" BO_ 2631566532 1;
BA_ "DiagConnection" BO_ 2631566532 80;
BA_ "DiagRequest" BO_ 2631566532 1;
BA_ "GenMsgCycleTime" BO_ 2631566532 0;
BA_ "VFrameFormat" BO_ 2631566531 1;
BA_ "DiagConnection" BO_ 2631566531 76;
BA_ "DiagRequest" BO_ 2631566531 1;
BA_ "GenMsgCycleTime" BO_ 2631566531 0;
BA_ "VFrameFormat" BO_ 2631566530 1;
BA_ "DiagConnection" BO_ 2631566530 72;
BA_ "DiagRequest" BO_ 2631566530 1;
BA_ "GenMsgCycleTime" BO_ 2631566530 0;
BA_ "VFrameFormat" BO_ 2631566273 1;
BA_ "DiagConnection" BO_ 2631566273 65;
BA_ "DiagRequest" BO_ 2631566273 1;
BA_ "GenMsgCycleTime" BO_ 2631566273 0;
BA_ "VFrameFormat" BO_ 2631566785 1;
BA_ "DiagConnection" BO_ 2631566785 66;
BA_ "DiagRequest" BO_ 2631566785 1;
BA_ "GenMsgCycleTime" BO_ 2631566785 0;
BA_ "VFrameFormat" BO_ 2631566017 1;
BA_ "DiagConnection" BO_ 2631566017 67;
BA_ "DiagRequest" BO_ 2631566017 1;
BA_ "GenMsgCycleTime" BO_ 2631566017 0;
BA_ "VFrameFormat" BO_ 2631566529 1;
BA_ "DiagConnection" BO_ 2631566529 68;
BA_ "DiagRequest" BO_ 2631566529 1;
BA_ "GenMsgCycleTime" BO_ 2631566529 0;
BA_ "DiagRequest" BO_ 2631566272 1;
BA_ "DiagConnection" BO_ 2631566272 88;
BA_ "VFrameFormat" BO_ 2631566272 1;
BA_ "GenMsgCycleTime" BO_ 2631566272 0;
BA_ "DiagRequest" BO_ 2631566784 1;
BA_ "DiagConnection" BO_ 2631566784 87;
BA_ "VFrameFormat" BO_ 2631566784 1;
BA_ "GenMsgCycleTime" BO_ 2631566784 0;
BA_ "DiagRequest" BO_ 2631566016 1;
BA_ "DiagConnection" BO_ 2631566016 86;
BA_ "VFrameFormat" BO_ 2631566016 1;
BA_ "GenMsgCycleTime" BO_ 2631566016 0;
BA_ "DiagRequest" BO_ 2631566528 1;
BA_ "DiagConnection" BO_ 2631566528 85;
BA_ "VFrameFormat" BO_ 2631566528 1;
BA_ "GenMsgCycleTime" BO_ 2631566528 0;
BA_ "VFrameFormat" BO_ 2631663557 1;
BA_ "DiagConnection" BO_ 2631663557 81;
BA_ "DiagState" BO_ 2631663557 1;
BA_ "GenMsgCycleTime" BO_ 2631663557 0;
BA_ "VFrameFormat" BO_ 2631663556 1;
BA_ "DiagConnection" BO_ 2631663556 77;
BA_ "DiagState" BO_ 2631663556 1;
BA_ "GenMsgCycleTime" BO_ 2631663556 0;
BA_ "VFrameFormat" BO_ 2631663555 1;
BA_ "DiagConnection" BO_ 2631663555 73;
BA_ "DiagState" BO_ 2631663555 1;
BA_ "GenMsgCycleTime" BO_ 2631663555 0;
BA_ "VFrameFormat" BO_ 2631663554 1;
BA_ "DiagConnection" BO_ 2631663554 69;
BA_ "DiagState" BO_ 2631663554 1;
BA_ "GenMsgCycleTime" BO_ 2631663554 0;
BA_ "VFrameFormat" BO_ 2631663553 1;
BA_ "DiagConnection" BO_ 2631663553 65;
BA_ "DiagState" BO_ 2631663553 1;
BA_ "GenMsgCycleTime" BO_ 2631663553 0;
BA_ "DiagState" BO_ 2631663552 1;
BA_ "DiagConnection" BO_ 2631663552 88;
BA_ "VFrameFormat" BO_ 2631663552 1;
BA_ "GenMsgCycleTime" BO_ 2631663552 0;
VAL_ 2399091085 BatchId_SRRObj_L_09 6 "Error" 7 "Not available" ;
VAL_ 2399091085 LonPosition_L_17 8160 "Error" 8176 "Not available" ;
VAL_ 2399091085 LonPositionStd_L_17 1022 "Error" 1023 "Not available" ;
VAL_ 2399091085 LatPosition_L_17 8160 "Error" 8176 "Not available" ;
VAL_ 2399091085 LatPositionStd_L_17 1022 "Error" 1023 "Not available" ;
VAL_ 2399091085 LonGndVel_L_17 8160 "Error" 8176 "Not available" ;
VAL_ 2399091085 LonGndVelStd_L_17 1022 "Error" 1023 "Not available" ;
VAL_ 2399091085 LatGndVel_L_17 8160 "Error" 8176 "Not available" ;
VAL_ 2399091085 LatGndVelStd_L_17 1022 "Error" 1023 "Not available" ;
VAL_ 2399091085 ExistenceProbability_L_17 254 "Error" 255 "Not available" ;
VAL_ 2399091085 Width_L_17 254 "Error" 255 "Not available" ;
VAL_ 2399091085 Length_L_17 1022 "Error" 1023 "Not available" ;
VAL_ 2399091085 HeadingAngle_L_17 254 "Error" 255 "Not available" ;
VAL_ 2399091085 DynamicProperty_L_17 0 "Invalid object" 1 "Stationary" 2 "Stopped" 3 "Moving" 6 "Error" 7 "Not available" ;
VAL_ 2399091085 ClassMostProb_L_17 0 "Unknown" 1 "Car" 2 "Motorbike" 3 "Truck" 4 "Bicycle" 5 "Pedestrian" 6 "Error" 7 "Not available" ;
VAL_ 2399091085 ClassMostProbConf_L_17 254 "Error" 255 "Not available" ;
VAL_ 2399091085 ClassSecMostProb_L_17 0 "Unknown" 1 "Car" 2 "Motorbike" 3 "Truck" 4 "Bicycle" 5 "Pedestrian" 6 "Error" 7 "Not available" ;
VAL_ 2399091085 ClassSecMostProbConf_L_17 254 "Error" 255 "Not available" ;
VAL_ 2399091085 MaintenanceState_L_17 0 "Not active" 1 "Newly created" 2 "Measured" 3 "Predicted" 6 "Error" 7 "Not available" ;
VAL_ 2399091085 YawRate_L_17 65024 "Error" 65280 "Not available" ;
VAL_ 2399091085 Occlusion_L_17 0 "Undefined" 1 "Occluded" 2 "On edge" 3 "Visible" 6 "Error" 7 "Not available" ;
VAL_ 2399091085 TrackingId_L_17 254 "Error" 255 "Not available" ;
VAL_ 2399091085 ReferencePoint_L_17 0 "Front left" 1 "Front" 2 "Front right" 3 "Right" 4 "Rear right" 5 "Rear" 6 "Rear left" 7 "Left" 8 "Unknown" 14 "Error" 15 "Not available" ;
VAL_ 2399091085 RadarCrossSection_L_17 2046 "Error" 2047 "Not available" ;
VAL_ 2399091085 AgeSinceCreated_L_17 1022 "Error" 1023 "Not available" ;
VAL_ 2399091085 LonPosition_L_18 8160 "Error" 8176 "Not available" ;
VAL_ 2399091085 LonPositionStd_L_18 1022 "Error" 1023 "Not available" ;
VAL_ 2399091085 LatPosition_L_18 8160 "Error" 8176 "Not available" ;
VAL_ 2399091085 LatPositionStd_L_18 1022 "Error" 1023 "Not available" ;
VAL_ 2399091085 LonGndVel_L_18 8160 "Error" 8176 "Not available" ;
VAL_ 2399091085 LonGndVelStd_L_18 1022 "Error" 1023 "Not available" ;
VAL_ 2399091085 LatGndVel_L_18 8160 "Error" 8176 "Not available" ;
VAL_ 2399091085 LatGndVelStd_L_18 1022 "Error" 1023 "Not available" ;
VAL_ 2399091085 ExistenceProbability_L_18 254 "Error" 255 "Not available" ;
VAL_ 2399091085 Width_L_18 254 "Error" 255 "Not available" ;
VAL_ 2399091085 Length_L_18 1022 "Error" 1023 "Not available" ;
VAL_ 2399091085 HeadingAngle_L_18 254 "Error" 255 "Not available" ;
VAL_ 2399091085 DynamicProperty_L_18 0 "Invalid object" 1 "Stationary" 2 "Stopped" 3 "Moving" 6 "Error" 7 "Not available" ;
VAL_ 2399091085 ClassMostProb_L_18 0 "Unknown" 1 "Car" 2 "Motorbike" 3 "Truck" 4 "Bicycle" 5 "Pedestrian" 6 "Error" 7 "Not available" ;
VAL_ 2399091085 ClassMostProbConf_L_18 254 "Error" 255 "Not available" ;
VAL_ 2399091085 ClassSecMostProb_L_18 0 "Unknown" 1 "Car" 2 "Motorbike" 3 "Truck" 4 "Bicycle" 5 "Pedestrian" 6 "Error" 7 "Not available" ;
VAL_ 2399091085 ClassSecMostProbConf_L_18 254 "Error" 255 "Not available" ;
VAL_ 2399091085 MaintenanceState_L_18 0 "Not active" 1 "Newly created" 2 "Measured" 3 "Predicted" 6 "Error" 7 "Not available" ;
VAL_ 2399091085 YawRate_L_18 65024 "Error" 65280 "Not available" ;
VAL_ 2399091085 Occlusion_L_18 0 "Undefined" 1 "Occluded" 2 "On edge" 3 "Visible" 6 "Error" 7 "Not available" ;
VAL_ 2399091085 TrackingId_L_18 254 "Error" 255 "Not available" ;
VAL_ 2399091085 ReferencePoint_L_18 0 "Front left" 1 "Front" 2 "Front right" 3 "Right" 4 "Rear right" 5 "Rear" 6 "Rear left" 7 "Left" 8 "Unknown" 14 "Error" 15 "Not available" ;
VAL_ 2399091085 RadarCrossSection_L_18 2046 "Error" 2047 "Not available" ;
VAL_ 2399091085 AgeSinceCreated_L_18 1022 "Error" 1023 "Not available" ;
VAL_ 2399091341 BatchId_SRRObj_L_10 6 "Error" 7 "Not available" ;
VAL_ 2399091341 LonPosition_L_19 8160 "Error" 8176 "Not available" ;
VAL_ 2399091341 LonPositionStd_L_19 1022 "Error" 1023 "Not available" ;
VAL_ 2399091341 LatPosition_L_19 8160 "Error" 8176 "Not available" ;
VAL_ 2399091341 LatPositionStd_L_19 1022 "Error" 1023 "Not available" ;
VAL_ 2399091341 LonGndVel_L_19 8160 "Error" 8176 "Not available" ;
VAL_ 2399091341 LonGndVelStd_L_19 1022 "Error" 1023 "Not available" ;
VAL_ 2399091341 LatGndVel_L_19 8160 "Error" 8176 "Not available" ;
VAL_ 2399091341 LatGndVelStd_L_19 1022 "Error" 1023 "Not available" ;
VAL_ 2399091341 ExistenceProbability_L_19 254 "Error" 255 "Not available" ;
VAL_ 2399091341 Width_L_19 254 "Error" 255 "Not available" ;
VAL_ 2399091341 Length_L_19 1022 "Error" 1023 "Not available" ;
VAL_ 2399091341 HeadingAngle_L_19 254 "Error" 255 "Not available" ;
VAL_ 2399091341 DynamicProperty_L_19 0 "Invalid object" 1 "Stationary" 2 "Stopped" 3 "Moving" 6 "Error" 7 "Not available" ;
VAL_ 2399091341 ClassMostProb_L_19 0 "Unknown" 1 "Car" 2 "Motorbike" 3 "Truck" 4 "Bicycle" 5 "Pedestrian" 6 "Error" 7 "Not available" ;
VAL_ 2399091341 ClassMostProbConf_L_19 254 "Error" 255 "Not available" ;
VAL_ 2399091341 ClassSecMostProb_L_19 0 "Unknown" 1 "Car" 2 "Motorbike" 3 "Truck" 4 "Bicycle" 5 "Pedestrian" 6 "Error" 7 "Not available" ;
VAL_ 2399091341 ClassSecMostProbConf_L_19 254 "Error" 255 "Not available" ;
VAL_ 2399091341 MaintenanceState_L_19 0 "Not active" 1 "Newly created" 2 "Measured" 3 "Predicted" 6 "Error" 7 "Not available" ;
VAL_ 2399091341 YawRate_L_19 65024 "Error" 65280 "Not available" ;
VAL_ 2399091341 Occlusion_L_19 0 "Undefined" 1 "Occluded" 2 "On edge" 3 "Visible" 6 "Error" 7 "Not available" ;
VAL_ 2399091341 TrackingId_L_19 254 "Error" 255 "Not available" ;
VAL_ 2399091341 ReferencePoint_L_19 0 "Front left" 1 "Front" 2 "Front right" 3 "Right" 4 "Rear right" 5 "Rear" 6 "Rear left" 7 "Left" 8 "Unknown" 14 "Error" 15 "Not available" ;
VAL_ 2399091341 RadarCrossSection_L_19 2046 "Error" 2047 "Not available" ;
VAL_ 2399091341 AgeSinceCreated_L_19 1022 "Error" 1023 "Not available" ;
VAL_ 2399091341 LonPosition_L_20 8160 "Error" 8176 "Not available" ;
VAL_ 2399091341 LonPositionStd_L_20 1022 "Error" 1023 "Not available" ;
VAL_ 2399091341 LatPosition_L_20 8160 "Error" 8176 "Not available" ;
VAL_ 2399091341 LatPositionStd_L_20 1022 "Error" 1023 "Not available" ;
VAL_ 2399091341 LonGndVel_L_20 8160 "Error" 8176 "Not available" ;
VAL_ 2399091341 LonGndVelStd_L_20 1022 "Error" 1023 "Not available" ;
VAL_ 2399091341 LatGndVel_L_20 8160 "Error" 8176 "Not available" ;
VAL_ 2399091341 LatGndVelStd_L_20 1022 "Error" 1023 "Not available" ;
VAL_ 2399091341 ExistenceProbability_L_20 254 "Error" 255 "Not available" ;
VAL_ 2399091341 Width_L_20 254 "Error" 255 "Not available" ;
VAL_ 2399091341 Length_L_20 1022 "Error" 1023 "Not available" ;
VAL_ 2399091341 HeadingAngle_L_20 254 "Error" 255 "Not available" ;
VAL_ 2399091341 DynamicProperty_L_20 0 "Invalid object" 1 "Stationary" 2 "Stopped" 3 "Moving" 6 "Error" 7 "Not available" ;
VAL_ 2399091341 ClassMostProb_L_20 0 "Unknown" 1 "Car" 2 "Motorbike" 3 "Truck" 4 "Bicycle" 5 "Pedestrian" 6 "Error" 7 "Not available" ;
VAL_ 2399091341 ClassMostProbConf_L_20 254 "Error" 255 "Not available" ;
VAL_ 2399091341 ClassSecMostProb_L_20 0 "Unknown" 1 "Car" 2 "Motorbike" 3 "Truck" 4 "Bicycle" 5 "Pedestrian" 6 "Error" 7 "Not available" ;
VAL_ 2399091341 ClassSecMostProbConf_L_20 254 "Error" 255 "Not available" ;
VAL_ 2399091341 MaintenanceState_L_20 0 "Not active" 1 "Newly created" 2 "Measured" 3 "Predicted" 6 "Error" 7 "Not available" ;
VAL_ 2399091341 YawRate_L_20 65024 "Error" 65280 "Not available" ;
VAL_ 2399091341 Occlusion_L_20 0 "Undefined" 1 "Occluded" 2 "On edge" 3 "Visible" 6 "Error" 7 "Not available" ;
VAL_ 2399091341 TrackingId_L_20 254 "Error" 255 "Not available" ;
VAL_ 2399091341 ReferencePoint_L_20 0 "Front left" 1 "Front" 2 "Front right" 3 "Right" 4 "Rear right" 5 "Rear" 6 "Rear left" 7 "Left" 8 "Unknown" 14 "Error" 15 "Not available" ;
VAL_ 2399091341 RadarCrossSection_L_20 2046 "Error" 2047 "Not available" ;
VAL_ 2399091341 AgeSinceCreated_L_20 1022 "Error" 1023 "Not available" ;
VAL_ 2399089039 BatchId_SRRObj_R_01 6 "Error" 7 "Not available" ;
VAL_ 2399089039 LonPosition_R_01 8160 "Error" 8176 "Not available" ;
VAL_ 2399089039 LonPositionStd_R_01 1022 "Error" 1023 "Not available" ;
VAL_ 2399089039 LatPosition_R_01 8160 "Error" 8176 "Not available" ;
VAL_ 2399089039 LatPositionStd_R_01 1022 "Error" 1023 "Not available" ;
VAL_ 2399089039 LonGndVel_R_01 8160 "Error" 8176 "Not available" ;
VAL_ 2399089039 LonGndVelStd_R_01 1022 "Error" 1023 "Not available" ;
VAL_ 2399089039 LatGndVel_R_01 8160 "Error" 8176 "Not available" ;
VAL_ 2399089039 LatGndVelStd_R_01 1022 "Error" 1023 "Not available" ;
VAL_ 2399089039 ExistenceProbability_R_01 254 "Error" 255 "Not available" ;
VAL_ 2399089039 Width_R_01 254 "Error" 255 "Not available" ;
VAL_ 2399089039 Length_R_01 1022 "Error" 1023 "Not available" ;
VAL_ 2399089039 HeadingAngle_R_01 254 "Error" 255 "Not available" ;
VAL_ 2399089039 DynamicProperty_R_01 0 "Invalid object" 1 "Stationary" 2 "Stopped" 3 "Moving" 6 "Error" 7 "Not available" ;
VAL_ 2399089039 ClassMostProb_R_01 0 "Unknown" 1 "Car" 2 "Motorbike" 3 "Truck" 4 "Bicycle" 5 "Pedestrian" 6 "Error" 7 "Not available" ;
VAL_ 2399089039 ClassMostProbConf_R_01 254 "Error" 255 "Not available" ;
VAL_ 2399089039 ClassSecMostProb_R_01 0 "Unknown" 1 "Car" 2 "Motorbike" 3 "Truck" 4 "Bicycle" 5 "Pedestrian" 6 "Error" 7 "Not available" ;
VAL_ 2399089039 ClassSecMostProbConf_R_01 254 "Error" 255 "Not available" ;
VAL_ 2399089039 MaintenanceState_R_01 0 "Not active" 1 "Newly created" 2 "Measured" 3 "Predicted" 6 "Error" 7 "Not available" ;
VAL_ 2399089039 YawRate_R_01 65024 "Error" 65280 "Not available" ;
VAL_ 2399089039 Occlusion_R_01 0 "Undefined" 1 "Occluded" 2 "On edge" 3 "Visible" 6 "Error" 7 "Not available" ;
VAL_ 2399089039 TrackingId_R_01 254 "Error" 255 "Not available" ;
VAL_ 2399089039 ReferencePoint_R_01 0 "Front left" 1 "Front" 2 "Front right" 3 "Right" 4 "Rear right" 5 "Rear" 6 "Rear left" 7 "Left" 8 "Unknown" 14 "Error" 15 "Not available" ;
VAL_ 2399089039 RadarCrossSection_R_01 2046 "Error" 2047 "Not available" ;
VAL_ 2399089039 AgeSinceCreated_R_01 1022 "Error" 1023 "Not available" ;
VAL_ 2399089039 LonPosition_R_02 8160 "Error" 8176 "Not available" ;
VAL_ 2399089039 LonPositionStd_R_02 1022 "Error" 1023 "Not available" ;
VAL_ 2399089039 LatPosition_R_02 8160 "Error" 8176 "Not available" ;
VAL_ 2399089039 LatPositionStd_R_02 1022 "Error" 1023 "Not available" ;
VAL_ 2399089039 LonGndVel_R_02 8160 "Error" 8176 "Not available" ;
VAL_ 2399089039 LonGndVelStd_R_02 1022 "Error" 1023 "Not available" ;
VAL_ 2399089039 LatGndVel_R_02 8160 "Error" 8176 "Not available" ;
VAL_ 2399089039 LatGndVelStd_R_02 1022 "Error" 1023 "Not available" ;
VAL_ 2399089039 ExistenceProbability_R_02 254 "Error" 255 "Not available" ;
VAL_ 2399089039 Width_R_02 254 "Error" 255 "Not available" ;
VAL_ 2399089039 Length_R_02 1022 "Error" 1023 "Not available" ;
VAL_ 2399089039 HeadingAngle_R_02 254 "Error" 255 "Not available" ;
VAL_ 2399089039 DynamicProperty_R_02 0 "Invalid object" 1 "Stationary" 2 "Stopped" 3 "Moving" 6 "Error" 7 "Not available" ;
VAL_ 2399089039 ClassMostProb_R_02 0 "Unknown" 1 "Car" 2 "Motorbike" 3 "Truck" 4 "Bicycle" 5 "Pedestrian" 6 "Error" 7 "Not available" ;
VAL_ 2399089039 ClassMostProbConf_R_02 254 "Error" 255 "Not available" ;
VAL_ 2399089039 ClassSecMostProb_R_02 0 "Unknown" 1 "Car" 2 "Motorbike" 3 "Truck" 4 "Bicycle" 5 "Pedestrian" 6 "Error" 7 "Not available" ;
VAL_ 2399089039 ClassSecMostProbConf_R_02 254 "Error" 255 "Not available" ;
VAL_ 2399089039 MaintenanceState_R_02 0 "Not active" 1 "Newly created" 2 "Measured" 3 "Predicted" 6 "Error" 7 "Not available" ;
VAL_ 2399089039 YawRate_R_02 65024 "Error" 65280 "Not available" ;
VAL_ 2399089039 Occlusion_R_02 0 "Undefined" 1 "Occluded" 2 "On edge" 3 "Visible" 6 "Error" 7 "Not available" ;
VAL_ 2399089039 TrackingId_R_02 254 "Error" 255 "Not available" ;
VAL_ 2399089039 ReferencePoint_R_02 0 "Front left" 1 "Front" 2 "Front right" 3 "Right" 4 "Rear right" 5 "Rear" 6 "Rear left" 7 "Left" 8 "Unknown" 14 "Error" 15 "Not available" ;
VAL_ 2399089039 RadarCrossSection_R_02 2046 "Error" 2047 "Not available" ;
VAL_ 2399089039 AgeSinceCreated_R_02 1022 "Error" 1023 "Not available" ;
VAL_ 2399089295 BatchId_SRRObj_R_02 6 "Error" 7 "Not available" ;
VAL_ 2399089295 LonPosition_R_03 8160 "Error" 8176 "Not available" ;
VAL_ 2399089295 LonPositionStd_R_03 1022 "Error" 1023 "Not available" ;
VAL_ 2399089295 LatPosition_R_03 8160 "Error" 8176 "Not available" ;
VAL_ 2399089295 LatPositionStd_R_03 1022 "Error" 1023 "Not available" ;
VAL_ 2399089295 LonGndVel_R_03 8160 "Error" 8176 "Not available" ;
VAL_ 2399089295 LonGndVelStd_R_03 1022 "Error" 1023 "Not available" ;
VAL_ 2399089295 LatGndVel_R_03 8160 "Error" 8176 "Not available" ;
VAL_ 2399089295 LatGndVelStd_R_03 1022 "Error" 1023 "Not available" ;
VAL_ 2399089295 ExistenceProbability_R_03 254 "Error" 255 "Not available" ;
VAL_ 2399089295 Width_R_03 254 "Error" 255 "Not available" ;
VAL_ 2399089295 Length_R_03 1022 "Error" 1023 "Not available" ;
VAL_ 2399089295 HeadingAngle_R_03 254 "Error" 255 "Not available" ;
VAL_ 2399089295 DynamicProperty_R_03 0 "Invalid object" 1 "Stationary" 2 "Stopped" 3 "Moving" 6 "Error" 7 "Not available" ;
VAL_ 2399089295 ClassMostProb_R_03 0 "Unknown" 1 "Car" 2 "Motorbike" 3 "Truck" 4 "Bicycle" 5 "Pedestrian" 6 "Error" 7 "Not available" ;
VAL_ 2399089295 ClassMostProbConf_R_03 254 "Error" 255 "Not available" ;
VAL_ 2399089295 ClassSecMostProb_R_03 0 "Unknown" 1 "Car" 2 "Motorbike" 3 "Truck" 4 "Bicycle" 5 "Pedestrian" 6 "Error" 7 "Not available" ;
VAL_ 2399089295 ClassSecMostProbConf_R_03 254 "Error" 255 "Not available" ;
VAL_ 2399089295 MaintenanceState_R_03 0 "Not active" 1 "Newly created" 2 "Measured" 3 "Predicted" 6 "Error" 7 "Not available" ;
VAL_ 2399089295 YawRate_R_03 65024 "Error" 65280 "Not available" ;
VAL_ 2399089295 Occlusion_R_03 0 "Undefined" 1 "Occluded" 2 "On edge" 3 "Visible" 6 "Error" 7 "Not available" ;
VAL_ 2399089295 TrackingId_R_03 254 "Error" 255 "Not available" ;
VAL_ 2399089295 ReferencePoint_R_03 0 "Front left" 1 "Front" 2 "Front right" 3 "Right" 4 "Rear right" 5 "Rear" 6 "Rear left" 7 "Left" 8 "Unknown" 14 "Error" 15 "Not available" ;
VAL_ 2399089295 RadarCrossSection_R_03 2046 "Error" 2047 "Not available" ;
VAL_ 2399089295 AgeSinceCreated_R_03 1022 "Error" 1023 "Not available" ;
VAL_ 2399089295 LonPosition_R_04 8160 "Error" 8176 "Not available" ;
VAL_ 2399089295 LonPositionStd_R_04 1022 "Error" 1023 "Not available" ;
VAL_ 2399089295 LatPosition_R_04 8160 "Error" 8176 "Not available" ;
VAL_ 2399089295 LatPositionStd_R_04 1022 "Error" 1023 "Not available" ;
VAL_ 2399089295 LonGndVel_R_04 8160 "Error" 8176 "Not available" ;
VAL_ 2399089295 LonGndVelStd_R_04 1022 "Error" 1023 "Not available" ;
VAL_ 2399089295 LatGndVel_R_04 8160 "Error" 8176 "Not available" ;
VAL_ 2399089295 LatGndVelStd_R_04 1022 "Error" 1023 "Not available" ;
VAL_ 2399089295 ExistenceProbability_R_04 254 "Error" 255 "Not available" ;
VAL_ 2399089295 Width_R_04 254 "Error" 255 "Not available" ;
VAL_ 2399089295 Length_R_04 1022 "Error" 1023 "Not available" ;
VAL_ 2399089295 HeadingAngle_R_04 254 "Error" 255 "Not available" ;
VAL_ 2399089295 DynamicProperty_R_04 0 "Invalid object" 1 "Stationary" 2 "Stopped" 3 "Moving" 6 "Error" 7 "Not available" ;
VAL_ 2399089295 ClassMostProb_R_04 0 "Unknown" 1 "Car" 2 "Motorbike" 3 "Truck" 4 "Bicycle" 5 "Pedestrian" 6 "Error" 7 "Not available" ;
VAL_ 2399089295 ClassMostProbConf_R_04 254 "Error" 255 "Not available" ;
VAL_ 2399089295 ClassSecMostProb_R_04 0 "Unknown" 1 "Car" 2 "Motorbike" 3 "Truck" 4 "Bicycle" 5 "Pedestrian" 6 "Error" 7 "Not available" ;
VAL_ 2399089295 ClassSecMostProbConf_R_04 254 "Error" 255 "Not available" ;
VAL_ 2399089295 MaintenanceState_R_04 0 "Not active" 1 "Newly created" 2 "Measured" 3 "Predicted" 6 "Error" 7 "Not available" ;
VAL_ 2399089295 YawRate_R_04 65024 "Error" 65280 "Not available" ;
VAL_ 2399089295 Occlusion_R_04 0 "Undefined" 1 "Occluded" 2 "On edge" 3 "Visible" 6 "Error" 7 "Not available" ;
VAL_ 2399089295 TrackingId_R_04 254 "Error" 255 "Not available" ;
VAL_ 2399089295 ReferencePoint_R_04 0 "Front left" 1 "Front" 2 "Front right" 3 "Right" 4 "Rear right" 5 "Rear" 6 "Rear left" 7 "Left" 8 "Unknown" 14 "Error" 15 "Not available" ;
VAL_ 2399089295 RadarCrossSection_R_04 2046 "Error" 2047 "Not available" ;
VAL_ 2399089295 AgeSinceCreated_R_04 1022 "Error" 1023 "Not available" ;
VAL_ 2399089551 BatchId_SRRObj_R_03 6 "Error" 7 "Not available" ;
VAL_ 2399089551 LonPosition_R_05 8160 "Error" 8176 "Not available" ;
VAL_ 2399089551 LonPositionStd_R_05 1022 "Error" 1023 "Not available" ;
VAL_ 2399089551 LatPosition_R_05 8160 "Error" 8176 "Not available" ;
VAL_ 2399089551 LatPositionStd_R_05 1022 "Error" 1023 "Not available" ;
VAL_ 2399089551 LonGndVel_R_05 8160 "Error" 8176 "Not available" ;
VAL_ 2399089551 LonGndVelStd_R_05 1022 "Error" 1023 "Not available" ;
VAL_ 2399089551 LatGndVel_R_05 8160 "Error" 8176 "Not available" ;
VAL_ 2399089551 LatGndVelStd_R_05 1022 "Error" 1023 "Not available" ;
VAL_ 2399089551 ExistenceProbability_R_05 254 "Error" 255 "Not available" ;
VAL_ 2399089551 Width_R_05 254 "Error" 255 "Not available" ;
VAL_ 2399089551 Length_R_05 1022 "Error" 1023 "Not available" ;
VAL_ 2399089551 HeadingAngle_R_05 254 "Error" 255 "Not available" ;
VAL_ 2399089551 DynamicProperty_R_05 0 "Invalid object" 1 "Stationary" 2 "Stopped" 3 "Moving" 6 "Error" 7 "Not available" ;
VAL_ 2399089551 ClassMostProb_R_05 0 "Unknown" 1 "Car" 2 "Motorbike" 3 "Truck" 4 "Bicycle" 5 "Pedestrian" 6 "Error" 7 "Not available" ;
VAL_ 2399089551 ClassMostProbConf_R_05 254 "Error" 255 "Not available" ;
VAL_ 2399089551 ClassSecMostProb_R_05 0 "Unknown" 1 "Car" 2 "Motorbike" 3 "Truck" 4 "Bicycle" 5 "Pedestrian" 6 "Error" 7 "Not available" ;
VAL_ 2399089551 ClassSecMostProbConf_R_05 254 "Error" 255 "Not available" ;
VAL_ 2399089551 MaintenanceState_R_05 0 "Not active" 1 "Newly created" 2 "Measured" 3 "Predicted" 6 "Error" 7 "Not available" ;
VAL_ 2399089551 YawRate_R_05 65024 "Error" 65280 "Not available" ;
VAL_ 2399089551 Occlusion_R_05 0 "Undefined" 1 "Occluded" 2 "On edge" 3 "Visible" 6 "Error" 7 "Not available" ;
VAL_ 2399089551 TrackingId_R_05 254 "Error" 255 "Not available" ;
VAL_ 2399089551 ReferencePoint_R_05 0 "Front left" 1 "Front" 2 "Front right" 3 "Right" 4 "Rear right" 5 "Rear" 6 "Rear left" 7 "Left" 8 "Unknown" 14 "Error" 15 "Not available" ;
VAL_ 2399089551 RadarCrossSection_R_05 2046 "Error" 2047 "Not available" ;
VAL_ 2399089551 AgeSinceCreated_R_05 1022 "Error" 1023 "Not available" ;
VAL_ 2399089551 LonPosition_R_06 8160 "Error" 8176 "Not available" ;
VAL_ 2399089551 LonPositionStd_R_06 1022 "Error" 1023 "Not available" ;
VAL_ 2399089551 LatPosition_R_06 8160 "Error" 8176 "Not available" ;
VAL_ 2399089551 LatPositionStd_R_06 1022 "Error" 1023 "Not available" ;
VAL_ 2399089551 LonGndVel_R_06 8160 "Error" 8176 "Not available" ;
VAL_ 2399089551 LonGndVelStd_R_06 1022 "Error" 1023 "Not available" ;
VAL_ 2399089551 LatGndVel_R_06 8160 "Error" 8176 "Not available" ;
VAL_ 2399089551 LatGndVelStd_R_06 1022 "Error" 1023 "Not available" ;
VAL_ 2399089551 ExistenceProbability_R_06 254 "Error" 255 "Not available" ;
VAL_ 2399089551 Width_R_06 254 "Error" 255 "Not available" ;
VAL_ 2399089551 Length_R_06 1022 "Error" 1023 "Not available" ;
VAL_ 2399089551 HeadingAngle_R_06 254 "Error" 255 "Not available" ;
VAL_ 2399089551 DynamicProperty_R_06 0 "Invalid object" 1 "Stationary" 2 "Stopped" 3 "Moving" 6 "Error" 7 "Not available" ;
VAL_ 2399089551 ClassMostProb_R_06 0 "Unknown" 1 "Car" 2 "Motorbike" 3 "Truck" 4 "Bicycle" 5 "Pedestrian" 6 "Error" 7 "Not available" ;
VAL_ 2399089551 ClassMostProbConf_R_06 254 "Error" 255 "Not available" ;
VAL_ 2399089551 ClassSecMostProb_R_06 0 "Unknown" 1 "Car" 2 "Motorbike" 3 "Truck" 4 "Bicycle" 5 "Pedestrian" 6 "Error" 7 "Not available" ;
VAL_ 2399089551 ClassSecMostProbConf_R_06 254 "Error" 255 "Not available" ;
VAL_ 2399089551 MaintenanceState_R_06 0 "Not active" 1 "Newly created" 2 "Measured" 3 "Predicted" 6 "Error" 7 "Not available" ;
VAL_ 2399089551 YawRate_R_06 65024 "Error" 65280 "Not available" ;
VAL_ 2399089551 Occlusion_R_06 0 "Undefined" 1 "Occluded" 2 "On edge" 3 "Visible" 6 "Error" 7 "Not available" ;
VAL_ 2399089551 TrackingId_R_06 254 "Error" 255 "Not available" ;
VAL_ 2399089551 ReferencePoint_R_06 0 "Front left" 1 "Front" 2 "Front right" 3 "Right" 4 "Rear right" 5 "Rear" 6 "Rear left" 7 "Left" 8 "Unknown" 14 "Error" 15 "Not available" ;
VAL_ 2399089551 RadarCrossSection_R_06 2046 "Error" 2047 "Not available" ;
VAL_ 2399089551 AgeSinceCreated_R_06 1022 "Error" 1023 "Not available" ;
VAL_ 2399089807 BatchId_SRRObj_R_04 6 "Error" 7 "Not available" ;
VAL_ 2399089807 LonPosition_R_07 8160 "Error" 8176 "Not available" ;
VAL_ 2399089807 LonPositionStd_R_07 1022 "Error" 1023 "Not available" ;
VAL_ 2399089807 LatPosition_R_07 8160 "Error" 8176 "Not available" ;
VAL_ 2399089807 LatPositionStd_R_07 1022 "Error" 1023 "Not available" ;
VAL_ 2399089807 LonGndVel_R_07 8160 "Error" 8176 "Not available" ;
VAL_ 2399089807 LonGndVelStd_R_07 1022 "Error" 1023 "Not available" ;
VAL_ 2399089807 LatGndVel_R_07 8160 "Error" 8176 "Not available" ;
VAL_ 2399089807 LatGndVelStd_R_07 1022 "Error" 1023 "Not available" ;
VAL_ 2399089807 ExistenceProbability_R_07 254 "Error" 255 "Not available" ;
VAL_ 2399089807 Width_R_07 254 "Error" 255 "Not available" ;
VAL_ 2399089807 Length_R_07 1022 "Error" 1023 "Not available" ;
VAL_ 2399089807 HeadingAngle_R_07 254 "Error" 255 "Not available" ;
VAL_ 2399089807 DynamicProperty_R_07 0 "Invalid object" 1 "Stationary" 2 "Stopped" 3 "Moving" 6 "Error" 7 "Not available" ;
VAL_ 2399089807 ClassMostProb_R_07 0 "Unknown" 1 "Car" 2 "Motorbike" 3 "Truck" 4 "Bicycle" 5 "Pedestrian" 6 "Error" 7 "Not available" ;
VAL_ 2399089807 ClassMostProbConf_R_07 254 "Error" 255 "Not available" ;
VAL_ 2399089807 ClassSecMostProb_R_07 0 "Unknown" 1 "Car" 2 "Motorbike" 3 "Truck" 4 "Bicycle" 5 "Pedestrian" 6 "Error" 7 "Not available" ;
VAL_ 2399089807 ClassSecMostProbConf_R_07 254 "Error" 255 "Not available" ;
VAL_ 2399089807 MaintenanceState_R_07 0 "Not active" 1 "Newly created" 2 "Measured" 3 "Predicted" 6 "Error" 7 "Not available" ;
VAL_ 2399089807 YawRate_R_07 65024 "Error" 65280 "Not available" ;
VAL_ 2399089807 Occlusion_R_07 0 "Undefined" 1 "Occluded" 2 "On edge" 3 "Visible" 6 "Error" 7 "Not available" ;
VAL_ 2399089807 TrackingId_R_07 254 "Error" 255 "Not available" ;
VAL_ 2399089807 ReferencePoint_R_07 0 "Front left" 1 "Front" 2 "Front right" 3 "Right" 4 "Rear right" 5 "Rear" 6 "Rear left" 7 "Left" 8 "Unknown" 14 "Error" 15 "Not available" ;
VAL_ 2399089807 RadarCrossSection_R_07 2046 "Error" 2047 "Not available" ;
VAL_ 2399089807 AgeSinceCreated_R_07 1022 "Error" 1023 "Not available" ;
VAL_ 2399089807 LonPosition_R_08 8160 "Error" 8176 "Not available" ;
VAL_ 2399089807 LonPositionStd_R_08 1022 "Error" 1023 "Not available" ;
VAL_ 2399089807 LatPosition_R_08 8160 "Error" 8176 "Not available" ;
VAL_ 2399089807 LatPositionStd_R_08 1022 "Error" 1023 "Not available" ;
VAL_ 2399089807 LonGndVel_R_08 8160 "Error" 8176 "Not available" ;
VAL_ 2399089807 LonGndVelStd_R_08 1022 "Error" 1023 "Not available" ;
VAL_ 2399089807 LatGndVel_R_08 8160 "Error" 8176 "Not available" ;
VAL_ 2399089807 LatGndVelStd_R_08 1022 "Error" 1023 "Not available" ;
VAL_ 2399089807 ExistenceProbability_R_08 254 "Error" 255 "Not available" ;
VAL_ 2399089807 Width_R_08 254 "Error" 255 "Not available" ;
VAL_ 2399089807 Length_R_08 1022 "Error" 1023 "Not available" ;
VAL_ 2399089807 HeadingAngle_R_08 254 "Error" 255 "Not available" ;
VAL_ 2399089807 DynamicProperty_R_08 0 "Invalid object" 1 "Stationary" 2 "Stopped" 3 "Moving" 6 "Error" 7 "Not available" ;
VAL_ 2399089807 ClassMostProb_R_08 0 "Unknown" 1 "Car" 2 "Motorbike" 3 "Truck" 4 "Bicycle" 5 "Pedestrian" 6 "Error" 7 "Not available" ;
VAL_ 2399089807 ClassMostProbConf_R_08 254 "Error" 255 "Not available" ;
VAL_ 2399089807 ClassSecMostProb_R_08 0 "Unknown" 1 "Car" 2 "Motorbike" 3 "Truck" 4 "Bicycle" 5 "Pedestrian" 6 "Error" 7 "Not available" ;
VAL_ 2399089807 ClassSecMostProbConf_R_08 254 "Error" 255 "Not available" ;
VAL_ 2399089807 MaintenanceState_R_08 0 "Not active" 1 "Newly created" 2 "Measured" 3 "Predicted" 6 "Error" 7 "Not available" ;
VAL_ 2399089807 YawRate_R_08 65024 "Error" 65280 "Not available" ;
VAL_ 2399089807 Occlusion_R_08 0 "Undefined" 1 "Occluded" 2 "On edge" 3 "Visible" 6 "Error" 7 "Not available" ;
VAL_ 2399089807 TrackingId_R_08 254 "Error" 255 "Not available" ;
VAL_ 2399089807 ReferencePoint_R_08 0 "Front left" 1 "Front" 2 "Front right" 3 "Right" 4 "Rear right" 5 "Rear" 6 "Rear left" 7 "Left" 8 "Unknown" 14 "Error" 15 "Not available" ;
VAL_ 2399089807 RadarCrossSection_R_08 2046 "Error" 2047 "Not available" ;
VAL_ 2399089807 AgeSinceCreated_R_08 1022 "Error" 1023 "Not available" ;
VAL_ 2399090063 BatchId_SRRObj_R_05 6 "Error" 7 "Not available" ;
VAL_ 2399090063 LonPosition_R_09 8160 "Error" 8176 "Not available" ;
VAL_ 2399090063 LonPositionStd_R_09 1022 "Error" 1023 "Not available" ;
VAL_ 2399090063 LatPosition_R_09 8160 "Error" 8176 "Not available" ;
VAL_ 2399090063 LatPositionStd_R_09 1022 "Error" 1023 "Not available" ;
VAL_ 2399090063 LonGndVel_R_09 8160 "Error" 8176 "Not available" ;
VAL_ 2399090063 LonGndVelStd_R_09 1022 "Error" 1023 "Not available" ;
VAL_ 2399090063 LatGndVel_R_09 8160 "Error" 8176 "Not available" ;
VAL_ 2399090063 LatGndVelStd_R_09 1022 "Error" 1023 "Not available" ;
VAL_ 2399090063 ExistenceProbability_R_09 254 "Error" 255 "Not available" ;
VAL_ 2399090063 Width_R_09 254 "Error" 255 "Not available" ;
VAL_ 2399090063 Length_R_09 1022 "Error" 1023 "Not available" ;
VAL_ 2399090063 HeadingAngle_R_09 254 "Error" 255 "Not available" ;
VAL_ 2399090063 DynamicProperty_R_09 0 "Invalid object" 1 "Stationary" 2 "Stopped" 3 "Moving" 6 "Error" 7 "Not available" ;
VAL_ 2399090063 ClassMostProb_R_09 0 "Unknown" 1 "Car" 2 "Motorbike" 3 "Truck" 4 "Bicycle" 5 "Pedestrian" 6 "Error" 7 "Not available" ;
VAL_ 2399090063 ClassMostProbConf_R_09 254 "Error" 255 "Not available" ;
VAL_ 2399090063 ClassSecMostProb_R_09 0 "Unknown" 1 "Car" 2 "Motorbike" 3 "Truck" 4 "Bicycle" 5 "Pedestrian" 6 "Error" 7 "Not available" ;
VAL_ 2399090063 ClassSecMostProbConf_R_09 254 "Error" 255 "Not available" ;
VAL_ 2399090063 MaintenanceState_R_09 0 "Not active" 1 "Newly created" 2 "Measured" 3 "Predicted" 6 "Error" 7 "Not available" ;
VAL_ 2399090063 YawRate_R_09 65024 "Error" 65280 "Not available" ;
VAL_ 2399090063 Occlusion_R_09 0 "Undefined" 1 "Occluded" 2 "On edge" 3 "Visible" 6 "Error" 7 "Not available" ;
VAL_ 2399090063 TrackingId_R_09 254 "Error" 255 "Not available" ;
VAL_ 2399090063 ReferencePoint_R_09 0 "Front left" 1 "Front" 2 "Front right" 3 "Right" 4 "Rear right" 5 "Rear" 6 "Rear left" 7 "Left" 8 "Unknown" 14 "Error" 15 "Not available" ;
VAL_ 2399090063 RadarCrossSection_R_09 2046 "Error" 2047 "Not available" ;
VAL_ 2399090063 AgeSinceCreated_R_09 1022 "Error" 1023 "Not available" ;
VAL_ 2399090063 LonPosition_R_10 8160 "Error" 8176 "Not available" ;
VAL_ 2399090063 LonPositionStd_R_10 1022 "Error" 1023 "Not available" ;
VAL_ 2399090063 LatPosition_R_10 8160 "Error" 8176 "Not available" ;
VAL_ 2399090063 LatPositionStd_R_10 1022 "Error" 1023 "Not available" ;
VAL_ 2399090063 LonGndVel_R_10 8160 "Error" 8176 "Not available" ;
VAL_ 2399090063 LonGndVelStd_R_10 1022 "Error" 1023 "Not available" ;
VAL_ 2399090063 LatGndVel_R_10 8160 "Error" 8176 "Not available" ;
VAL_ 2399090063 LatGndVelStd_R_10 1022 "Error" 1023 "Not available" ;
VAL_ 2399090063 ExistenceProbability_R_10 254 "Error" 255 "Not available" ;
VAL_ 2399090063 Width_R_10 254 "Error" 255 "Not available" ;
VAL_ 2399090063 Length_R_10 1022 "Error" 1023 "Not available" ;
VAL_ 2399090063 HeadingAngle_R_10 254 "Error" 255 "Not available" ;
VAL_ 2399090063 DynamicProperty_R_10 0 "Invalid object" 1 "Stationary" 2 "Stopped" 3 "Moving" 6 "Error" 7 "Not available" ;
VAL_ 2399090063 ClassMostProb_R_10 0 "Unknown" 1 "Car" 2 "Motorbike" 3 "Truck" 4 "Bicycle" 5 "Pedestrian" 6 "Error" 7 "Not available" ;
VAL_ 2399090063 ClassMostProbConf_R_10 254 "Error" 255 "Not available" ;
VAL_ 2399090063 ClassSecMostProb_R_10 0 "Unknown" 1 "Car" 2 "Motorbike" 3 "Truck" 4 "Bicycle" 5 "Pedestrian" 6 "Error" 7 "Not available" ;
VAL_ 2399090063 ClassSecMostProbConf_R_10 254 "Error" 255 "Not available" ;
VAL_ 2399090063 MaintenanceState_R_10 0 "Not active" 1 "Newly created" 2 "Measured" 3 "Predicted" 6 "Error" 7 "Not available" ;
VAL_ 2399090063 YawRate_R_10 65024 "Error" 65280 "Not available" ;
VAL_ 2399090063 Occlusion_R_10 0 "Undefined" 1 "Occluded" 2 "On edge" 3 "Visible" 6 "Error" 7 "Not available" ;
VAL_ 2399090063 TrackingId_R_10 254 "Error" 255 "Not available" ;
VAL_ 2399090063 ReferencePoint_R_10 0 "Front left" 1 "Front" 2 "Front right" 3 "Right" 4 "Rear right" 5 "Rear" 6 "Rear left" 7 "Left" 8 "Unknown" 14 "Error" 15 "Not available" ;
VAL_ 2399090063 RadarCrossSection_R_10 2046 "Error" 2047 "Not available" ;
VAL_ 2399090063 AgeSinceCreated_R_10 1022 "Error" 1023 "Not available" ;
VAL_ 2399090319 BatchId_SRRObj_R_06 6 "Error" 7 "Not available" ;
VAL_ 2399090319 LonPosition_R_11 8160 "Error" 8176 "Not available" ;
VAL_ 2399090319 LonPositionStd_R_11 1022 "Error" 1023 "Not available" ;
VAL_ 2399090319 LatPosition_R_11 8160 "Error" 8176 "Not available" ;
VAL_ 2399090319 LatPositionStd_R_11 1022 "Error" 1023 "Not available" ;
VAL_ 2399090319 LonGndVel_R_11 8160 "Error" 8176 "Not available" ;
VAL_ 2399090319 LonGndVelStd_R_11 1022 "Error" 1023 "Not available" ;
VAL_ 2399090319 LatGndVel_R_11 8160 "Error" 8176 "Not available" ;
VAL_ 2399090319 LatGndVelStd_R_11 1022 "Error" 1023 "Not available" ;
VAL_ 2399090319 ExistenceProbability_R_11 254 "Error" 255 "Not available" ;
VAL_ 2399090319 Width_R_11 254 "Error" 255 "Not available" ;
VAL_ 2399090319 Length_R_11 1022 "Error" 1023 "Not available" ;
VAL_ 2399090319 HeadingAngle_R_11 254 "Error" 255 "Not available" ;
VAL_ 2399090319 DynamicProperty_R_11 0 "Invalid object" 1 "Stationary" 2 "Stopped" 3 "Moving" 6 "Error" 7 "Not available" ;
VAL_ 2399090319 ClassMostProb_R_11 0 "Unknown" 1 "Car" 2 "Motorbike" 3 "Truck" 4 "Bicycle" 5 "Pedestrian" 6 "Error" 7 "Not available" ;
VAL_ 2399090319 ClassMostProbConf_R_11 254 "Error" 255 "Not available" ;
VAL_ 2399090319 ClassSecMostProb_R_11 0 "Unknown" 1 "Car" 2 "Motorbike" 3 "Truck" 4 "Bicycle" 5 "Pedestrian" 6 "Error" 7 "Not available" ;
VAL_ 2399090319 ClassSecMostProbConf_R_11 254 "Error" 255 "Not available" ;
VAL_ 2399090319 MaintenanceState_R_11 0 "Not active" 1 "Newly created" 2 "Measured" 3 "Predicted" 6 "Error" 7 "Not available" ;
VAL_ 2399090319 YawRate_R_11 65024 "Error" 65280 "Not available" ;
VAL_ 2399090319 Occlusion_R_11 0 "Undefined" 1 "Occluded" 2 "On edge" 3 "Visible" 6 "Error" 7 "Not available" ;
VAL_ 2399090319 TrackingId_R_11 254 "Error" 255 "Not available" ;
VAL_ 2399090319 ReferencePoint_R_11 0 "Front left" 1 "Front" 2 "Front right" 3 "Right" 4 "Rear right" 5 "Rear" 6 "Rear left" 7 "Left" 8 "Unknown" 14 "Error" 15 "Not available" ;
VAL_ 2399090319 RadarCrossSection_R_11 2046 "Error" 2047 "Not available" ;
VAL_ 2399090319 AgeSinceCreated_R_11 1022 "Error" 1023 "Not available" ;
VAL_ 2399090319 LonPosition_R_12 8160 "Error" 8176 "Not available" ;
VAL_ 2399090319 LonPositionStd_R_12 1022 "Error" 1023 "Not available" ;
VAL_ 2399090319 LatPosition_R_12 8160 "Error" 8176 "Not available" ;
VAL_ 2399090319 LatPositionStd_R_12 1022 "Error" 1023 "Not available" ;
VAL_ 2399090319 LonGndVel_R_12 8160 "Error" 8176 "Not available" ;
VAL_ 2399090319 LonGndVelStd_R_12 1022 "Error" 1023 "Not available" ;
VAL_ 2399090319 LatGndVel_R_12 8160 "Error" 8176 "Not available" ;
VAL_ 2399090319 LatGndVelStd_R_12 1022 "Error" 1023 "Not available" ;
VAL_ 2399090319 ExistenceProbability_R_12 254 "Error" 255 "Not available" ;
VAL_ 2399090319 Width_R_12 254 "Error" 255 "Not available" ;
VAL_ 2399090319 Length_R_12 1022 "Error" 1023 "Not available" ;
VAL_ 2399090319 HeadingAngle_R_12 254 "Error" 255 "Not available" ;
VAL_ 2399090319 DynamicProperty_R_12 0 "Invalid object" 1 "Stationary" 2 "Stopped" 3 "Moving" 6 "Error" 7 "Not available" ;
VAL_ 2399090319 ClassMostProb_R_12 0 "Unknown" 1 "Car" 2 "Motorbike" 3 "Truck" 4 "Bicycle" 5 "Pedestrian" 6 "Error" 7 "Not available" ;
VAL_ 2399090319 ClassMostProbConf_R_12 254 "Error" 255 "Not available" ;
VAL_ 2399090319 ClassSecMostProb_R_12 0 "Unknown" 1 "Car" 2 "Motorbike" 3 "Truck" 4 "Bicycle" 5 "Pedestrian" 6 "Error" 7 "Not available" ;
VAL_ 2399090319 ClassSecMostProbConf_R_12 254 "Error" 255 "Not available" ;
VAL_ 2399090319 MaintenanceState_R_12 0 "Not active" 1 "Newly created" 2 "Measured" 3 "Predicted" 6 "Error" 7 "Not available" ;
VAL_ 2399090319 YawRate_R_12 65024 "Error" 65280 "Not available" ;
VAL_ 2399090319 Occlusion_R_12 0 "Undefined" 1 "Occluded" 2 "On edge" 3 "Visible" 6 "Error" 7 "Not available" ;
VAL_ 2399090319 TrackingId_R_12 254 "Error" 255 "Not available" ;
VAL_ 2399090319 ReferencePoint_R_12 0 "Front left" 1 "Front" 2 "Front right" 3 "Right" 4 "Rear right" 5 "Rear" 6 "Rear left" 7 "Left" 8 "Unknown" 14 "Error" 15 "Not available" ;
VAL_ 2399090319 RadarCrossSection_R_12 2046 "Error" 2047 "Not available" ;
VAL_ 2399090319 AgeSinceCreated_R_12 1022 "Error" 1023 "Not available" ;
VAL_ 2399090575 BatchId_SRRObj_R_07 6 "Error" 7 "Not available" ;
VAL_ 2399090575 LonPosition_R_13 8160 "Error" 8176 "Not available" ;
VAL_ 2399090575 LonPositionStd_R_13 1022 "Error" 1023 "Not available" ;
VAL_ 2399090575 LatPosition_R_13 8160 "Error" 8176 "Not available" ;
VAL_ 2399090575 LatPositionStd_R_13 1022 "Error" 1023 "Not available" ;
VAL_ 2399090575 LonGndVel_R_13 8160 "Error" 8176 "Not available" ;
VAL_ 2399090575 LonGndVelStd_R_13 1022 "Error" 1023 "Not available" ;
VAL_ 2399090575 LatGndVel_R_13 8160 "Error" 8176 "Not available" ;
VAL_ 2399090575 LatGndVelStd_R_13 1022 "Error" 1023 "Not available" ;
VAL_ 2399090575 ExistenceProbability_R_13 254 "Error" 255 "Not available" ;
VAL_ 2399090575 Width_R_13 254 "Error" 255 "Not available" ;
VAL_ 2399090575 Length_R_13 1022 "Error" 1023 "Not available" ;
VAL_ 2399090575 HeadingAngle_R_13 254 "Error" 255 "Not available" ;
VAL_ 2399090575 DynamicProperty_R_13 0 "Invalid object" 1 "Stationary" 2 "Stopped" 3 "Moving" 6 "Error" 7 "Not available" ;
VAL_ 2399090575 ClassMostProb_R_13 0 "Unknown" 1 "Car" 2 "Motorbike" 3 "Truck" 4 "Bicycle" 5 "Pedestrian" 6 "Error" 7 "Not available" ;
VAL_ 2399090575 ClassMostProbConf_R_13 254 "Error" 255 "Not available" ;
VAL_ 2399090575 ClassSecMostProb_R_13 0 "Unknown" 1 "Car" 2 "Motorbike" 3 "Truck" 4 "Bicycle" 5 "Pedestrian" 6 "Error" 7 "Not available" ;
VAL_ 2399090575 ClassSecMostProbConf_R_13 254 "Error" 255 "Not available" ;
VAL_ 2399090575 MaintenanceState_R_13 0 "Not active" 1 "Newly created" 2 "Measured" 3 "Predicted" 6 "Error" 7 "Not available" ;
VAL_ 2399090575 YawRate_R_13 65024 "Error" 65280 "Not available" ;
VAL_ 2399090575 Occlusion_R_13 0 "Undefined" 1 "Occluded" 2 "On edge" 3 "Visible" 6 "Error" 7 "Not available" ;
VAL_ 2399090575 TrackingId_R_13 254 "Error" 255 "Not available" ;
VAL_ 2399090575 ReferencePoint_R_13 0 "Front left" 1 "Front" 2 "Front right" 3 "Right" 4 "Rear right" 5 "Rear" 6 "Rear left" 7 "Left" 8 "Unknown" 14 "Error" 15 "Not available" ;
VAL_ 2399090575 RadarCrossSection_R_13 2046 "Error" 2047 "Not available" ;
VAL_ 2399090575 AgeSinceCreated_R_13 1022 "Error" 1023 "Not available" ;
VAL_ 2399090575 LonPosition_R_14 8160 "Error" 8176 "Not available" ;
VAL_ 2399090575 LonPositionStd_R_14 1022 "Error" 1023 "Not available" ;
VAL_ 2399090575 LatPosition_R_14 8160 "Error" 8176 "Not available" ;
VAL_ 2399090575 LatPositionStd_R_14 1022 "Error" 1023 "Not available" ;
VAL_ 2399090575 LonGndVel_R_14 8160 "Error" 8176 "Not available" ;
VAL_ 2399090575 LonGndVelStd_R_14 1022 "Error" 1023 "Not available" ;
VAL_ 2399090575 LatGndVel_R_14 8160 "Error" 8176 "Not available" ;
VAL_ 2399090575 LatGndVelStd_R_14 1022 "Error" 1023 "Not available" ;
VAL_ 2399090575 ExistenceProbability_R_14 254 "Error" 255 "Not available" ;
VAL_ 2399090575 Width_R_14 254 "Error" 255 "Not available" ;
VAL_ 2399090575 Length_R_14 1022 "Error" 1023 "Not available" ;
VAL_ 2399090575 HeadingAngle_R_14 254 "Error" 255 "Not available" ;
VAL_ 2399090575 DynamicProperty_R_14 0 "Invalid object" 1 "Stationary" 2 "Stopped" 3 "Moving" 6 "Error" 7 "Not available" ;
VAL_ 2399090575 ClassMostProb_R_14 0 "Unknown" 1 "Car" 2 "Motorbike" 3 "Truck" 4 "Bicycle" 5 "Pedestrian" 6 "Error" 7 "Not available" ;
VAL_ 2399090575 ClassMostProbConf_R_14 254 "Error" 255 "Not available" ;
VAL_ 2399090575 ClassSecMostProb_R_14 0 "Unknown" 1 "Car" 2 "Motorbike" 3 "Truck" 4 "Bicycle" 5 "Pedestrian" 6 "Error" 7 "Not available" ;
VAL_ 2399090575 ClassSecMostProbConf_R_14 254 "Error" 255 "Not available" ;
VAL_ 2399090575 MaintenanceState_R_14 0 "Not active" 1 "Newly created" 2 "Measured" 3 "Predicted" 6 "Error" 7 "Not available" ;
VAL_ 2399090575 YawRate_R_14 65024 "Error" 65280 "Not available" ;
VAL_ 2399090575 Occlusion_R_14 0 "Undefined" 1 "Occluded" 2 "On edge" 3 "Visible" 6 "Error" 7 "Not available" ;
VAL_ 2399090575 TrackingId_R_14 254 "Error" 255 "Not available" ;
VAL_ 2399090575 ReferencePoint_R_14 0 "Front left" 1 "Front" 2 "Front right" 3 "Right" 4 "Rear right" 5 "Rear" 6 "Rear left" 7 "Left" 8 "Unknown" 14 "Error" 15 "Not available" ;
VAL_ 2399090575 RadarCrossSection_R_14 2046 "Error" 2047 "Not available" ;
VAL_ 2399090575 AgeSinceCreated_R_14 1022 "Error" 1023 "Not available" ;
VAL_ 2399090831 BatchId_SRRObj_R_08 6 "Error" 7 "Not available" ;
VAL_ 2399090831 LonPosition_R_15 8160 "Error" 8176 "Not available" ;
VAL_ 2399090831 LonPositionStd_R_15 1022 "Error" 1023 "Not available" ;
VAL_ 2399090831 LatPosition_R_15 8160 "Error" 8176 "Not available" ;
VAL_ 2399090831 LatPositionStd_R_15 1022 "Error" 1023 "Not available" ;
VAL_ 2399090831 LonGndVel_R_15 8160 "Error" 8176 "Not available" ;
VAL_ 2399090831 LonGndVelStd_R_15 1022 "Error" 1023 "Not available" ;
VAL_ 2399090831 LatGndVel_R_15 8160 "Error" 8176 "Not available" ;
VAL_ 2399090831 LatGndVelStd_R_15 1022 "Error" 1023 "Not available" ;
VAL_ 2399090831 ExistenceProbability_R_15 254 "Error" 255 "Not available" ;
VAL_ 2399090831 Width_R_15 254 "Error" 255 "Not available" ;
VAL_ 2399090831 Length_R_15 1022 "Error" 1023 "Not available" ;
VAL_ 2399090831 HeadingAngle_R_15 254 "Error" 255 "Not available" ;
VAL_ 2399090831 DynamicProperty_R_15 0 "Invalid object" 1 "Stationary" 2 "Stopped" 3 "Moving" 6 "Error" 7 "Not available" ;
VAL_ 2399090831 ClassMostProb_R_15 0 "Unknown" 1 "Car" 2 "Motorbike" 3 "Truck" 4 "Bicycle" 5 "Pedestrian" 6 "Error" 7 "Not available" ;
VAL_ 2399090831 ClassMostProbConf_R_15 254 "Error" 255 "Not available" ;
VAL_ 2399090831 ClassSecMostProb_R_15 0 "Unknown" 1 "Car" 2 "Motorbike" 3 "Truck" 4 "Bicycle" 5 "Pedestrian" 6 "Error" 7 "Not available" ;
VAL_ 2399090831 ClassSecMostProbConf_R_15 254 "Error" 255 "Not available" ;
VAL_ 2399090831 MaintenanceState_R_15 0 "Not active" 1 "Newly created" 2 "Measured" 3 "Predicted" 6 "Error" 7 "Not available" ;
VAL_ 2399090831 YawRate_R_15 65024 "Error" 65280 "Not available" ;
VAL_ 2399090831 Occlusion_R_15 0 "Undefined" 1 "Occluded" 2 "On edge" 3 "Visible" 6 "Error" 7 "Not available" ;
VAL_ 2399090831 TrackingId_R_15 254 "Error" 255 "Not available" ;
VAL_ 2399090831 ReferencePoint_R_15 0 "Front left" 1 "Front" 2 "Front right" 3 "Right" 4 "Rear right" 5 "Rear" 6 "Rear left" 7 "Left" 8 "Unknown" 14 "Error" 15 "Not available" ;
VAL_ 2399090831 RadarCrossSection_R_15 2046 "Error" 2047 "Not available" ;
VAL_ 2399090831 AgeSinceCreated_R_15 1022 "Error" 1023 "Not available" ;
VAL_ 2399090831 LonPosition_R_16 8160 "Error" 8176 "Not available" ;
VAL_ 2399090831 LonPositionStd_R_16 1022 "Error" 1023 "Not available" ;
VAL_ 2399090831 LatPosition_R_16 8160 "Error" 8176 "Not available" ;
VAL_ 2399090831 LatPositionStd_R_16 1022 "Error" 1023 "Not available" ;
VAL_ 2399090831 LonGndVel_R_16 8160 "Error" 8176 "Not available" ;
VAL_ 2399090831 LonGndVelStd_R_16 1022 "Error" 1023 "Not available" ;
VAL_ 2399090831 LatGndVel_R_16 8160 "Error" 8176 "Not available" ;
VAL_ 2399090831 LatGndVelStd_R_16 1022 "Error" 1023 "Not available" ;
VAL_ 2399090831 ExistenceProbability_R_16 254 "Error" 255 "Not available" ;
VAL_ 2399090831 Width_R_16 254 "Error" 255 "Not available" ;
VAL_ 2399090831 Length_R_16 1022 "Error" 1023 "Not available" ;
VAL_ 2399090831 HeadingAngle_R_16 254 "Error" 255 "Not available" ;
VAL_ 2399090831 DynamicProperty_R_16 0 "Invalid object" 1 "Stationary" 2 "Stopped" 3 "Moving" 6 "Error" 7 "Not available" ;
VAL_ 2399090831 ClassMostProb_R_16 0 "Unknown" 1 "Car" 2 "Motorbike" 3 "Truck" 4 "Bicycle" 5 "Pedestrian" 6 "Error" 7 "Not available" ;
VAL_ 2399090831 ClassMostProbConf_R_16 254 "Error" 255 "Not available" ;
VAL_ 2399090831 ClassSecMostProb_R_16 0 "Unknown" 1 "Car" 2 "Motorbike" 3 "Truck" 4 "Bicycle" 5 "Pedestrian" 6 "Error" 7 "Not available" ;
VAL_ 2399090831 ClassSecMostProbConf_R_16 254 "Error" 255 "Not available" ;
VAL_ 2399090831 MaintenanceState_R_16 0 "Not active" 1 "Newly created" 2 "Measured" 3 "Predicted" 6 "Error" 7 "Not available" ;
VAL_ 2399090831 YawRate_R_16 65024 "Error" 65280 "Not available" ;
VAL_ 2399090831 Occlusion_R_16 0 "Undefined" 1 "Occluded" 2 "On edge" 3 "Visible" 6 "Error" 7 "Not available" ;
VAL_ 2399090831 TrackingId_R_16 254 "Error" 255 "Not available" ;
VAL_ 2399090831 ReferencePoint_R_16 0 "Front left" 1 "Front" 2 "Front right" 3 "Right" 4 "Rear right" 5 "Rear" 6 "Rear left" 7 "Left" 8 "Unknown" 14 "Error" 15 "Not available" ;
VAL_ 2399090831 RadarCrossSection_R_16 2046 "Error" 2047 "Not available" ;
VAL_ 2399090831 AgeSinceCreated_R_16 1022 "Error" 1023 "Not available" ;
VAL_ 2399091087 BatchId_SRRObj_R_09 6 "Error" 7 "Not available" ;
VAL_ 2399091087 LonPosition_R_17 8160 "Error" 8176 "Not available" ;
VAL_ 2399091087 LonPositionStd_R_17 1022 "Error" 1023 "Not available" ;
VAL_ 2399091087 LatPosition_R_17 8160 "Error" 8176 "Not available" ;
VAL_ 2399091087 LatPositionStd_R_17 1022 "Error" 1023 "Not available" ;
VAL_ 2399091087 LonGndVel_R_17 8160 "Error" 8176 "Not available" ;
VAL_ 2399091087 LonGndVelStd_R_17 1022 "Error" 1023 "Not available" ;
VAL_ 2399091087 LatGndVel_R_17 8160 "Error" 8176 "Not available" ;
VAL_ 2399091087 LatGndVelStd_R_17 1022 "Error" 1023 "Not available" ;
VAL_ 2399091087 ExistenceProbability_R_17 254 "Error" 255 "Not available" ;
VAL_ 2399091087 Width_R_17 254 "Error" 255 "Not available" ;
VAL_ 2399091087 Length_R_17 1022 "Error" 1023 "Not available" ;
VAL_ 2399091087 HeadingAngle_R_17 254 "Error" 255 "Not available" ;
VAL_ 2399091087 DynamicProperty_R_17 0 "Invalid object" 1 "Stationary" 2 "Stopped" 3 "Moving" 6 "Error" 7 "Not available" ;
VAL_ 2399091087 ClassMostProb_R_17 0 "Unknown" 1 "Car" 2 "Motorbike" 3 "Truck" 4 "Bicycle" 5 "Pedestrian" 6 "Error" 7 "Not available" ;
VAL_ 2399091087 ClassMostProbConf_R_17 254 "Error" 255 "Not available" ;
VAL_ 2399091087 ClassSecMostProb_R_17 0 "Unknown" 1 "Car" 2 "Motorbike" 3 "Truck" 4 "Bicycle" 5 "Pedestrian" 6 "Error" 7 "Not available" ;
VAL_ 2399091087 ClassSecMostProbConf_R_17 254 "Error" 255 "Not available" ;
VAL_ 2399091087 MaintenanceState_R_17 0 "Not active" 1 "Newly created" 2 "Measured" 3 "Predicted" 6 "Error" 7 "Not available" ;
VAL_ 2399091087 YawRate_R_17 65024 "Error" 65280 "Not available" ;
VAL_ 2399091087 Occlusion_R_17 0 "Undefined" 1 "Occluded" 2 "On edge" 3 "Visible" 6 "Error" 7 "Not available" ;
VAL_ 2399091087 TrackingId_R_17 254 "Error" 255 "Not available" ;
VAL_ 2399091087 ReferencePoint_R_17 0 "Front left" 1 "Front" 2 "Front right" 3 "Right" 4 "Rear right" 5 "Rear" 6 "Rear left" 7 "Left" 8 "Unknown" 14 "Error" 15 "Not available" ;
VAL_ 2399091087 RadarCrossSection_R_17 2046 "Error" 2047 "Not available" ;
VAL_ 2399091087 AgeSinceCreated_R_17 1022 "Error" 1023 "Not available" ;
VAL_ 2399091087 LonPosition_R_18 8160 "Error" 8176 "Not available" ;
VAL_ 2399091087 LonPositionStd_R_18 1022 "Error" 1023 "Not available" ;
VAL_ 2399091087 LatPosition_R_18 8160 "Error" 8176 "Not available" ;
VAL_ 2399091087 LatPositionStd_R_18 1022 "Error" 1023 "Not available" ;
VAL_ 2399091087 LonGndVel_R_18 8160 "Error" 8176 "Not available" ;
VAL_ 2399091087 LonGndVelStd_R_18 1022 "Error" 1023 "Not available" ;
VAL_ 2399091087 LatGndVel_R_18 8160 "Error" 8176 "Not available" ;
VAL_ 2399091087 LatGndVelStd_R_18 1022 "Error" 1023 "Not available" ;
VAL_ 2399091087 ExistenceProbability_R_18 254 "Error" 255 "Not available" ;
VAL_ 2399091087 Width_R_18 254 "Error" 255 "Not available" ;
VAL_ 2399091087 Length_R_18 1022 "Error" 1023 "Not available" ;
VAL_ 2399091087 HeadingAngle_R_18 254 "Error" 255 "Not available" ;
VAL_ 2399091087 DynamicProperty_R_18 0 "Invalid object" 1 "Stationary" 2 "Stopped" 3 "Moving" 6 "Error" 7 "Not available" ;
VAL_ 2399091087 ClassMostProb_R_18 0 "Unknown" 1 "Car" 2 "Motorbike" 3 "Truck" 4 "Bicycle" 5 "Pedestrian" 6 "Error" 7 "Not available" ;
VAL_ 2399091087 ClassMostProbConf_R_18 254 "Error" 255 "Not available" ;
VAL_ 2399091087 ClassSecMostProb_R_18 0 "Unknown" 1 "Car" 2 "Motorbike" 3 "Truck" 4 "Bicycle" 5 "Pedestrian" 6 "Error" 7 "Not available" ;
VAL_ 2399091087 ClassSecMostProbConf_R_18 254 "Error" 255 "Not available" ;
VAL_ 2399091087 MaintenanceState_R_18 0 "Not active" 1 "Newly created" 2 "Measured" 3 "Predicted" 6 "Error" 7 "Not available" ;
VAL_ 2399091087 YawRate_R_18 65024 "Error" 65280 "Not available" ;
VAL_ 2399091087 Occlusion_R_18 0 "Undefined" 1 "Occluded" 2 "On edge" 3 "Visible" 6 "Error" 7 "Not available" ;
VAL_ 2399091087 TrackingId_R_18 254 "Error" 255 "Not available" ;
VAL_ 2399091087 ReferencePoint_R_18 0 "Front left" 1 "Front" 2 "Front right" 3 "Right" 4 "Rear right" 5 "Rear" 6 "Rear left" 7 "Left" 8 "Unknown" 14 "Error" 15 "Not available" ;
VAL_ 2399091087 RadarCrossSection_R_18 2046 "Error" 2047 "Not available" ;
VAL_ 2399091087 AgeSinceCreated_R_18 1022 "Error" 1023 "Not available" ;
VAL_ 2399091343 BatchId_SRRObj_R_10 6 "Error" 7 "Not available" ;
VAL_ 2399091343 LonPosition_R_19 8160 "Error" 8176 "Not available" ;
VAL_ 2399091343 LonPositionStd_R_19 1022 "Error" 1023 "Not available" ;
VAL_ 2399091343 LatPosition_R_19 8160 "Error" 8176 "Not available" ;
VAL_ 2399091343 LatPositionStd_R_19 1022 "Error" 1023 "Not available" ;
VAL_ 2399091343 LonGndVel_R_19 8160 "Error" 8176 "Not available" ;
VAL_ 2399091343 LonGndVelStd_R_19 1022 "Error" 1023 "Not available" ;
VAL_ 2399091343 LatGndVel_R_19 8160 "Error" 8176 "Not available" ;
VAL_ 2399091343 LatGndVelStd_R_19 1022 "Error" 1023 "Not available" ;
VAL_ 2399091343 ExistenceProbability_R_19 254 "Error" 255 "Not available" ;
VAL_ 2399091343 Width_R_19 254 "Error" 255 "Not available" ;
VAL_ 2399091343 Length_R_19 1022 "Error" 1023 "Not available" ;
VAL_ 2399091343 HeadingAngle_R_19 254 "Error" 255 "Not available" ;
VAL_ 2399091343 DynamicProperty_R_19 0 "Invalid object" 1 "Stationary" 2 "Stopped" 3 "Moving" 6 "Error" 7 "Not available" ;
VAL_ 2399091343 ClassMostProb_R_19 0 "Unknown" 1 "Car" 2 "Motorbike" 3 "Truck" 4 "Bicycle" 5 "Pedestrian" 6 "Error" 7 "Not available" ;
VAL_ 2399091343 ClassMostProbConf_R_19 254 "Error" 255 "Not available" ;
VAL_ 2399091343 ClassSecMostProb_R_19 0 "Unknown" 1 "Car" 2 "Motorbike" 3 "Truck" 4 "Bicycle" 5 "Pedestrian" 6 "Error" 7 "Not available" ;
VAL_ 2399091343 ClassSecMostProbConf_R_19 254 "Error" 255 "Not available" ;
VAL_ 2399091343 MaintenanceState_R_19 0 "Not active" 1 "Newly created" 2 "Measured" 3 "Predicted" 6 "Error" 7 "Not available" ;
VAL_ 2399091343 YawRate_R_19 65024 "Error" 65280 "Not available" ;
VAL_ 2399091343 Occlusion_R_19 0 "Undefined" 1 "Occluded" 2 "On edge" 3 "Visible" 6 "Error" 7 "Not available" ;
VAL_ 2399091343 TrackingId_R_19 254 "Error" 255 "Not available" ;
VAL_ 2399091343 ReferencePoint_R_19 0 "Front left" 1 "Front" 2 "Front right" 3 "Right" 4 "Rear right" 5 "Rear" 6 "Rear left" 7 "Left" 8 "Unknown" 14 "Error" 15 "Not available" ;
VAL_ 2399091343 RadarCrossSection_R_19 2046 "Error" 2047 "Not available" ;
VAL_ 2399091343 AgeSinceCreated_R_19 1022 "Error" 1023 "Not available" ;
VAL_ 2399091343 LonPosition_R_20 8160 "Error" 8176 "Not available" ;
VAL_ 2399091343 LonPositionStd_R_20 1022 "Error" 1023 "Not available" ;
VAL_ 2399091343 LatPosition_R_20 8160 "Error" 8176 "Not available" ;
VAL_ 2399091343 LatPositionStd_R_20 1022 "Error" 1023 "Not available" ;
VAL_ 2399091343 LonGndVel_R_20 8160 "Error" 8176 "Not available" ;
VAL_ 2399091343 LonGndVelStd_R_20 1022 "Error" 1023 "Not available" ;
VAL_ 2399091343 LatGndVel_R_20 8160 "Error" 8176 "Not available" ;
VAL_ 2399091343 LatGndVelStd_R_20 1022 "Error" 1023 "Not available" ;
VAL_ 2399091343 ExistenceProbability_R_20 254 "Error" 255 "Not available" ;
VAL_ 2399091343 Width_R_20 254 "Error" 255 "Not available" ;
VAL_ 2399091343 Length_R_20 1022 "Error" 1023 "Not available" ;
VAL_ 2399091343 HeadingAngle_R_20 254 "Error" 255 "Not available" ;
VAL_ 2399091343 DynamicProperty_R_20 0 "Invalid object" 1 "Stationary" 2 "Stopped" 3 "Moving" 6 "Error" 7 "Not available" ;
VAL_ 2399091343 ClassMostProb_R_20 0 "Unknown" 1 "Car" 2 "Motorbike" 3 "Truck" 4 "Bicycle" 5 "Pedestrian" 6 "Error" 7 "Not available" ;
VAL_ 2399091343 ClassMostProbConf_R_20 254 "Error" 255 "Not available" ;
VAL_ 2399091343 ClassSecMostProb_R_20 0 "Unknown" 1 "Car" 2 "Motorbike" 3 "Truck" 4 "Bicycle" 5 "Pedestrian" 6 "Error" 7 "Not available" ;
VAL_ 2399091343 ClassSecMostProbConf_R_20 254 "Error" 255 "Not available" ;
VAL_ 2399091343 MaintenanceState_R_20 0 "Not active" 1 "Newly created" 2 "Measured" 3 "Predicted" 6 "Error" 7 "Not available" ;
VAL_ 2399091343 YawRate_R_20 65024 "Error" 65280 "Not available" ;
VAL_ 2399091343 Occlusion_R_20 0 "Undefined" 1 "Occluded" 2 "On edge" 3 "Visible" 6 "Error" 7 "Not available" ;
VAL_ 2399091343 TrackingId_R_20 254 "Error" 255 "Not available" ;
VAL_ 2399091343 ReferencePoint_R_20 0 "Front left" 1 "Front" 2 "Front right" 3 "Right" 4 "Rear right" 5 "Rear" 6 "Rear left" 7 "Left" 8 "Unknown" 14 "Error" 15 "Not available" ;
VAL_ 2399091343 RadarCrossSection_R_20 2046 "Error" 2047 "Not available" ;
VAL_ 2399091343 AgeSinceCreated_R_20 1022 "Error" 1023 "Not available" ;
VAL_ 2399092775 VehicleSpeed 65024 "Error" 65280 "Not Available" ;
VAL_ 2399092775 YawRate 65024 "Error" 65280 "Not Available" ;
VAL_ 2399092775 LongitudinalAcceleration 254 "ErrorValue " 255 "Not Available" ;
VAL_ 2399092775 LateralAcceleration 65280 "NotAvailable" 65024 "ErrorValue" ;
VAL_ 2399092775 EffectiveWheelBase 254 "Error" 255 "NotAvailable" ;
VAL_ 2399092775 SteeringWheelAngle 65280 "Not Available" 65024 "Error" ;
VAL_ 2399092775 TrailerConnection 2 "Error" 0 "No trailer connected" 1 "Trailer connected" 3 "NotAvailable" ;
VAL_ 2399092775 ParkingBrakeStatus 2 "Error" 0 "Electric Park Brake disengaged" 1 "Electric Park Brake engaged" 3 "NotAvailable" ;
VAL_ 2399092775 VehicleSpeed_QF 0 "VeSpeedIncorrect" 1 "VehSpeed Estimated w/ABS" 2 "VehSpeed Correct" 3 "NotAvailable" ;
VAL_ 2399092775 YawRate_QF 2 "Error" 0 "YawRate Incorrect" 1 "YawRate correct" 3 "NotAvailable" ;
VAL_ 2399092775 missionMode 0 "Mission Mode deactivated" 1 "Mission Mode activated" 2 "error indicator" 3 "not available / not installed" ;
